VERSION ""

NS_ :

BS_:

BU_: ETH

BO_ 1060 PCS_alertLog: 8 Vector__XXX
 SG_ PCS_alertID M : 0|7@1+ (1,0) [0|0] "" Vector__XXX
 SG_ PCS_alertSet : 15|1@1+ (1,0) [0|0] "" Vector__XXX
 SG_ PCS_a001_llcFrequency m1 : 16|8@1+ (1,50) [0|0] "" Vector__XXX
 SG_ PCS_a002_phState m2 : 16|4@1+ (1,0) [0|0] "" Vector__XXX
 SG_ PCS_a003_phState m3 : 16|4@1+ (1,0) [0|0] "" Vector__XXX
 SG_ PCS_a004_phState m4 : 16|4@1+ (1,0) [0|0] "" Vector__XXX
 SG_ PCS_a005_outputV m5 : 16|8@1+ (2,0) [0|0] "" Vector__XXX
 SG_ PCS_a006_phState m6 : 16|4@1+ (1,0) [0|0] "" Vector__XXX
 SG_ PCS_a007_phATemperature m7 : 16|7@1+ (1,0) [0|0] "" Vector__XXX
 SG_ PCS_a008_phState m8 : 16|4@1+ (1,0) [0|0] "" Vector__XXX
 SG_ PCS_a009_phState m9 : 16|4@1+ (1,0) [0|0] "" Vector__XXX
 SG_ PCS_a010_phState m10 : 16|4@1+ (1,0) [0|0] "" Vector__XXX
 SG_ PCS_a011_phState m11 : 16|4@1+ (1,0) [0|0] "" Vector__XXX
 SG_ PCS_a012_phState m12 : 16|4@1+ (1,0) [0|0] "" Vector__XXX
 SG_ PCS_a013_phState m13 : 16|4@1+ (1,0) [0|0] "" Vector__XXX
 SG_ PCS_a014_phaTemperature m14 : 16|11@1- (0.1,40) [0|0] "" Vector__XXX
 SG_ PCS_a015_lvBusVoltage m15 : 16|8@1+ (0.15625,0) [0|0] "" Vector__XXX
 SG_ PCS_a016_phAVoltSrcMissingDetected m16 : 16|1@1+ (1,0) [0|0] "" Vector__XXX
 SG_ PCS_a018_PhaseDiff_L1N_L2N m18 : 16|9@1+ (1,-1) [0|0] "" Vector__XXX
 SG_ PCS_a019_pcsMaxAvailablePower m19 : 16|8@1+ (0.1,0) [0|0] "" Vector__XXX
 SG_ PCS_a020_chargeEnableLine m20 : 16|1@1+ (1,0) [0|0] "" Vector__XXX
 SG_ PCS_a021_HVP_hvsControl m21 : 16|1@1+ (1,0) [0|0] "" Vector__XXX
 SG_ PCS_a022_BMS_pcsRequest m22 : 16|1@1+ (1,0) [0|0] "" Vector__XXX
 SG_ PCS_a023_CP_chargeStatus m23 : 16|1@1+ (1,0) [0|0] "" Vector__XXX
 SG_ PCS_a024_VCFRONT_sensors m24 : 16|1@1+ (1,0) [0|0] "" Vector__XXX
 SG_ PCS_a025_cpu2ErrorCode m25 : 16|4@1+ (1,0) [0|0] "" Vector__XXX
 SG_ PCS_a026_CPU1_watchdog_alarmed m26 : 16|1@1+ (1,0) [0|0] "" Vector__XXX
 SG_ PCS_a027_chgPhATemp m27 : 16|8@1- (1,40) [0|0] "" Vector__XXX
 SG_ PCS_a028_outputV m28 : 16|10@1+ (0.5,0) [0|0] "" Vector__XXX
 SG_ PCS_a029_inputVrms m29 : 16|9@1+ (1,0) [0|0] "" Vector__XXX
 SG_ PCS_a030_canRxErrorType m30 : 16|3@1+ (1,0) [0|0] "" Vector__XXX
 SG_ PCS_a031_UI_chargeRequest m31 : 16|1@1+ (1,0) [0|0] "" Vector__XXX
 SG_ PCS_a032_phATransientRetryCount m32 : 16|9@1+ (0.1,0) [0|0] "" Vector__XXX
 SG_ PCS_a033_HV_busV m33 : 16|12@1+ (0.146484375,0) [0|0] "" Vector__XXX
 SG_ PCS_a034_HV_busV m34 : 16|12@1+ (0.146484375,0) [0|0] "" Vector__XXX
 SG_ PCS_a035_LV_busV m35 : 16|12@1+ (0.009765625,0) [0|0] "" Vector__XXX
 SG_ PCS_a036_LV_busV m36 : 16|12@1+ (0.009765625,0) [0|0] "" Vector__XXX
 SG_ PCS_a037_dcdcPwmDeassertedCount m37 : 16|8@1+ (1,0) [0|0] "" Vector__XXX
 SG_ PCS_a038_dcdcClaFaultCode m38 : 16|4@1+ (1,0) [0|0] "" Vector__XXX
 SG_ PCS_a039_SDModuleClockFault_HV m39 : 16|1@1+ (1,0) [0|0] "" Vector__XXX
 SG_ PCS_a040_dcdcLvVoltageTarget m40 : 16|8@1+ (0.1,0) [0|0] "" Vector__XXX
 SG_ PCS_a041_dcdcTemperature m41 : 16|11@1- (0.1,40) [0|0] "" Vector__XXX
 SG_ PCS_a042_dcdcEnableLine m42 : 16|1@1+ (1,0) [0|0] "" Vector__XXX
 SG_ PCS_a043_dcdcLvBusV m43 : 16|10@1+ (0.0390625,0) [0|0] "" Vector__XXX
 SG_ PCS_a044_FaultReasonCode m44 : 16|2@1+ (1,0) [0|0] "" Vector__XXX
 SG_ PCS_a045_hvBusEstimated_C_uF m45 : 16|10@1+ (7.820136852394917,0) [0|0] "" Vector__XXX
 SG_ PCS_a046_hvBusEstimated_C_uF m46 : 16|10@1+ (7.820136852394917,0) [0|0] "" Vector__XXX
 SG_ PCS_a047_cpu1BootLoaderCrcMismatch m47 : 16|1@1+ (1,0) [0|0] "" Vector__XXX
 SG_ PCS_a048_assertionReason m48 : 16|1@1+ (1,0) [0|0] "" Vector__XXX
 SG_ PCS_a049_dcdcTemperature m49 : 16|11@1- (0.1,40) [0|0] "" Vector__XXX
 SG_ PCS_a051_phState m51 : 16|4@1+ (1,0) [0|0] "" Vector__XXX
 SG_ PCS_a052_inputVrms m52 : 16|9@1+ (1,0) [0|0] "" Vector__XXX
 SG_ PCS_a053_inputVrms m53 : 16|9@1+ (1,0) [0|0] "" Vector__XXX
 SG_ PCS_a054_inputVrms m54 : 16|9@1+ (1,0) [0|0] "" Vector__XXX
 SG_ PCS_a057_inputVrms m57 : 16|10@1+ (0.5,0) [0|0] "" Vector__XXX
 SG_ PCS_a058_inputVrms m58 : 16|10@1+ (0.5,0) [0|0] "" Vector__XXX
 SG_ PCS_a059_inputVrms m59 : 16|10@1+ (0.5,0) [0|0] "" Vector__XXX
 SG_ PCS_a060_inputVPeak m60 : 16|10@1+ (0.5,0) [0|0] "" Vector__XXX
 SG_ PCS_a061_chgInputVdcOffset_L1N m61 : 16|8@1+ (1,0) [0|0] "" Vector__XXX
 SG_ PCS_a062_chgInputIOffset m62 : 16|12@1- (0.01,0) [0|0] "" Vector__XXX
 SG_ PCS_a063_chgOutputV m63 : 16|10@1+ (1,0) [0|0] "" Vector__XXX
 SG_ PCS_a064_chgOutputIOffset m64 : 16|12@1- (0.01,0) [0|0] "" Vector__XXX
 SG_ PCS_a065_inputVrms m65 : 16|10@1+ (0.5,0) [0|0] "" Vector__XXX
 SG_ PCS_a066_dcdcHvBusVolt m66 : 16|14@1+ (0.1,0) [0|0] "" Vector__XXX
 SG_ PCS_a067_dcdcLvBusVolt m67 : 16|13@1+ (0.01,0) [0|0] "" Vector__XXX
 SG_ PCS_a068_dcdcTankVolt m68 : 16|16@1- (0.03051757813,0) [0|0] "" Vector__XXX
 SG_ PCS_a069_phState m69 : 16|4@1+ (1,0) [0|0] "" Vector__XXX
 SG_ PCS_a070_phState m70 : 16|4@1+ (1,0) [0|0] "" Vector__XXX
 SG_ PCS_a071_phState m71 : 16|4@1+ (1,0) [0|0] "" Vector__XXX
 SG_ PCS_a072_task1Stopped m72 : 16|1@1+ (1,0) [0|0] "" Vector__XXX
 SG_ PCS_a073_inputL1NVrms m73 : 16|9@1+ (1,0) [0|0] "" Vector__XXX
 SG_ PCS_a074_dcdcLvBusV m74 : 16|10@1+ (0.0390625,0) [0|0] "" Vector__XXX
 SG_ PCS_a075_dcdcLvBusV m75 : 16|10@1+ (0.0390625,0) [0|0] "" Vector__XXX
 SG_ PCS_a076_pcsControlRequest m76 : 16|2@1+ (1,0) [0|0] "" Vector__XXX
 SG_ PCS_a078_phaTemperature m78 : 16|8@1- (1,40) [0|0] "" Vector__XXX
 SG_ PCS_a079_eepromOperation m79 : 16|4@1+ (1,0) [0|0] "" Vector__XXX
 SG_ PCS_a080_phADamaged m80 : 16|1@1+ (1,0) [0|0] "" Vector__XXX
 SG_ PCS_a081_dcdcLvBusV m81 : 16|10@1+ (0.0390625,0) [0|0] "" Vector__XXX
 SG_ PCS_a082_dcdcLvBusV m82 : 16|10@1+ (0.0390625,0) [0|0] "" Vector__XXX
 SG_ PCS_a083_logId m83 : 16|4@1+ (1,0) [0|0] "" Vector__XXX
 SG_ PCS_a084_dcdcSubState m84 : 16|5@1+ (1,0) [0|0] "" Vector__XXX
 SG_ PCS_a085_dcdcHalfPeriodUs m85 : 16|16@1+ (0.005,0) [0|0] "" Vector__XXX
 SG_ PCS_a086_dcdcTemperature m86 : 16|12@1- (0.1,0) [0|0] "" Vector__XXX
 SG_ PCS_a087_recordID m87 : 16|8@1+ (1,0) [0|0] "" Vector__XXX
 SG_ PCS_a088_gridConfig m88 : 16|4@1+ (1,0) [0|0] "" Vector__XXX
 SG_ PCS_a089_hvSlewRate m89 : 16|8@1- (2,0) [0|0] "" Vector__XXX
 SG_ PCS_a090_vRmsL1N m90 : 16|9@1+ (1,0) [0|0] "" Vector__XXX
 SG_ PCS_a091_intBusTarget m91 : 16|9@1+ (1,0) [0|0] "" Vector__XXX
 SG_ PCS_a092_pfcIrmsPhA m92 : 16|7@1+ (0.2,0) [0|0] "" Vector__XXX
 SG_ PCS_a093_powerRail5VN m93 : 16|10@1+ (0.01,0) [0|0] "" Vector__XXX
 SG_ PCS_a094_malfunctionCode m94 : 16|2@1+ (1,0) [0|0] "" Vector__XXX
 SG_ PCS_a095_powerRail5VN m95 : 16|10@1+ (0.01,0) [0|0] "" Vector__XXX
 SG_ PCS_a096_gridConfig m96 : 16|4@1+ (1,0) [0|0] "" Vector__XXX
 SG_ PCS_a097_phADamaged m97 : 16|1@1+ (1,0) [0|0] "" Vector__XXX
 SG_ PCS_a098_gridConfig m98 : 16|4@1+ (1,0) [0|0] "" Vector__XXX
 SG_ PCS_a099_gridConfig m99 : 16|4@1+ (1,0) [0|0] "" Vector__XXX
 SG_ PCS_a100_inputVrms m100 : 16|9@1+ (1,0) [0|0] "" Vector__XXX
 SG_ PCS_a101_phPllFreq m101 : 16|12@1+ (0.01,40) [0|0] "" Vector__XXX
 SG_ PCS_a102_pcsControlRequest m102 : 16|2@1+ (1,0) [0|0] "" Vector__XXX
 SG_ PCS_a103_lvBusVoltMin m103 : 16|8@1+ (0.1,0) [0|0] "" Vector__XXX
 SG_ PCS_a104_ambientTemperature m104 : 16|11@1- (0.1,40) [0|0] "" Vector__XXX
 SG_ PCS_a105_vRmsL1N m105 : 16|9@1+ (1,0) [0|0] "" Vector__XXX
 SG_ PCS_a107_VC_pcsInterface m107 : 16|1@1+ (1,0) [0|0] "" Vector__XXX
 SG_ PCS_a108_installedInAWrongPlatform m108 : 16|1@1+ (1,0) [0|0] "" Vector__XXX
 SG_ PCS_a109_inputL2NVrms m109 : 16|9@1+ (1,0) [0|0] "" Vector__XXX
 SG_ PCS_a016_phBVoltSrcMissingDetected m16 : 17|1@1+ (1,0) [0|0] "" Vector__XXX
 SG_ PCS_a020_chargeEnableCan m20 : 17|1@1+ (1,0) [0|0] "" Vector__XXX
 SG_ PCS_a022_BMS_chargeStatus m22 : 17|1@1+ (1,0) [0|0] "" Vector__XXX
 SG_ PCS_a023_CP_status m23 : 17|1@1+ (1,0) [0|0] "" Vector__XXX
 SG_ PCS_a024_VCFRONT_vehicleStatus m24 : 17|1@1+ (1,0) [0|0] "" Vector__XXX
 SG_ PCS_a026_CPU2_watchdog_alarmed m26 : 17|1@1+ (1,0) [0|0] "" Vector__XXX
 SG_ PCS_a039_SDModuleClockFault_LV m39 : 17|1@1+ (1,0) [0|0] "" Vector__XXX
 SG_ PCS_a042_dcdcEnableCan m42 : 17|1@1+ (1,0) [0|0] "" Vector__XXX
 SG_ PCS_a047_cpu2BootLoaderCrcMismatch m47 : 17|1@1+ (1,0) [0|0] "" Vector__XXX
 SG_ PCS_a048_4bitsData1 m48 : 17|4@1+ (1,0) [0|0] "" Vector__XXX
 SG_ PCS_a072_task2Stopped m72 : 17|1@1+ (1,0) [0|0] "" Vector__XXX
 SG_ PCS_a080_phBDamaged m80 : 17|1@1+ (1,0) [0|0] "" Vector__XXX
 SG_ PCS_a097_phBDamaged m97 : 17|1@1+ (1,0) [0|0] "" Vector__XXX
 SG_ PCS_a016_phCVoltSrcMissingDetected m16 : 18|1@1+ (1,0) [0|0] "" Vector__XXX
 SG_ PCS_a024_VCFRONT_systemStatus m24 : 18|1@1+ (1,0) [0|0] "" Vector__XXX
 SG_ PCS_a026_NMIFlagRegisters m26 : 18|11@1+ (1,0) [0|0] "" Vector__XXX
 SG_ PCS_a044_shortTime_us m44 : 18|10@1+ (0.03128054740957967,0) [0|0] "" Vector__XXX
 SG_ PCS_a076_dcdcSubState m76 : 18|5@1+ (1,0) [0|0] "" Vector__XXX
 SG_ PCS_a080_phCDamaged m80 : 18|1@1+ (1,0) [0|0] "" Vector__XXX
 SG_ PCS_a097_phCDamaged m97 : 18|1@1+ (1,0) [0|0] "" Vector__XXX
 SG_ PCS_a102_NMIFlagRegisters m102 : 18|11@1+ (1,0) [0|0] "" Vector__XXX
 SG_ PCS_a024_VCFRONT_coolant m24 : 19|1@1+ (1,0) [0|0] "" Vector__XXX
 SG_ PCS_a080_phANVRAMStoredState m80 : 19|3@1+ (1,0) [0|0] "" Vector__XXX
 SG_ PCS_a097_phANVRAMStoredState m97 : 19|3@1+ (1,0) [0|0] "" Vector__XXX
 SG_ PCS_a006_intBusPrechargeTarget m6 : 20|9@1+ (1,0) [0|0] "" Vector__XXX
 SG_ PCS_a008_phaseTemperature m8 : 20|11@1- (0.1,40) [0|0] "" Vector__XXX
 SG_ PCS_a009_pfcCurrentRms m9 : 20|9@1+ (0.1,0) [0|0] "" Vector__XXX
 SG_ PCS_a010_pfcCurrentRms m10 : 20|9@1+ (0.1,0) [0|0] "" Vector__XXX
 SG_ PCS_a011_llcCurrent m11 : 20|8@1+ (0.1,0) [0|0] "" Vector__XXX
 SG_ PCS_a012_llcFrequency m12 : 20|8@1+ (1,50) [0|0] "" Vector__XXX
 SG_ PCS_a013_intBusPrechargeTarget m13 : 20|9@1+ (1,0) [0|0] "" Vector__XXX
 SG_ PCS_a024_VCFRONT_vehNm m24 : 20|1@1+ (1,0) [0|0] "" Vector__XXX
 SG_ PCS_a025_bootromStatus m25 : 20|4@1+ (1,0) [0|0] "" Vector__XXX
 SG_ PCS_a038_dcdcSubState m38 : 20|5@1+ (1,0) [0|0] "" Vector__XXX
 SG_ PCS_a051_pfcCurrentRms m51 : 20|9@1+ (0.1,0) [0|0] "" Vector__XXX
 SG_ PCS_a069_inputIDelta m69 : 20|10@1+ (0.1,0) [0|0] "" Vector__XXX
 SG_ PCS_a070_inputVDelta m70 : 20|10@1+ (0.1,0) [0|0] "" Vector__XXX
 SG_ PCS_a071_inputVrms m71 : 20|10@1+ (0.5,0) [0|0] "" Vector__XXX
 SG_ PCS_a079_eepromOperationRegion m79 : 20|2@1+ (1,0) [0|0] "" Vector__XXX
 SG_ PCS_a088_phAFrequency m88 : 20|12@1+ (0.01,40) [0|0] "" Vector__XXX
 SG_ PCS_a096_phAFrequency m96 : 20|12@1+ (0.01,40) [0|0] "" Vector__XXX
 SG_ PCS_a098_phAFrequency m98 : 20|12@1+ (0.01,40) [0|0] "" Vector__XXX
 SG_ PCS_a099_phAFrequency m99 : 20|12@1+ (0.01,40) [0|0] "" Vector__XXX
 SG_ PCS_a024_VC_pcsManagement m24 : 21|1@1+ (1,0) [0|0] "" Vector__XXX
 SG_ PCS_a024_VCFRONT_LVPowerState m24 : 22|1@1+ (1,0) [0|0] "" Vector__XXX
 SG_ PCS_a007_phBTemperature m7 : 23|7@1+ (1,0) [0|0] "" Vector__XXX
 SG_ PCS_a076_dcdcEnableLine m76 : 23|1@1+ (1,0) [0|0] "" Vector__XXX
 SG_ PCS_a092_pfcIrmsPhB m92 : 23|7@1+ (0.2,0) [0|0] "" Vector__XXX
 SG_ PCS_a001_llcCurrent m1 : 24|8@1+ (0.1,0) [0|0] "" Vector__XXX
 SG_ PCS_a005_outputVOvThreshold m5 : 24|8@1+ (2,0) [0|0] "" Vector__XXX
 SG_ PCS_a019_utilityPowerAvailable m19 : 24|8@1+ (0.1,0) [0|0] "" Vector__XXX
 SG_ PCS_a025_bootloaderStatus m25 : 24|4@1+ (1,0) [0|0] "" Vector__XXX
 SG_ PCS_a027_chgPhBTemp m27 : 24|8@1- (1,40) [0|0] "" Vector__XXX
 SG_ PCS_a030_canID m30 : 24|16@1+ (1,0) [0|0] "" Vector__XXX
 SG_ PCS_a040_dcdcLvVoltage m40 : 24|8@1+ (0.1,0) [0|0] "" Vector__XXX
 SG_ PCS_a047_calculatedBootloaderCrc m47 : 24|32@1+ (1,0) [0|0] "" Vector__XXX
 SG_ PCS_a048_4bitsData2 m48 : 24|4@1+ (1,0) [0|0] "" Vector__XXX
 SG_ PCS_a061_chgInputVdcOffset_L2N m61 : 24|8@1+ (1,0) [0|0] "" Vector__XXX
 SG_ PCS_a076_dcdcPwmEnableDeassertedCount m76 : 24|8@1+ (1,0) [0|0] "" Vector__XXX
 SG_ PCS_a078_phbTemperature m78 : 24|8@1- (1,40) [0|0] "" Vector__XXX
 SG_ PCS_a079_recordID m79 : 24|8@1+ (1,0) [0|0] "" Vector__XXX
 SG_ PCS_a080_phBNVRAMStoredState m80 : 24|3@1+ (1,0) [0|0] "" Vector__XXX
 SG_ PCS_a084_dcdcLvBusV m84 : 24|8@1+ (0.15625,0) [0|0] "" Vector__XXX
 SG_ PCS_a087_recordStatus m87 : 24|16@1+ (1,0) [0|0] "" Vector__XXX
 SG_ PCS_a089_avgSlewRate m89 : 24|8@1- (2,0) [0|0] "" Vector__XXX
 SG_ PCS_a097_phBNVRAMStoredState m97 : 24|3@1+ (1,0) [0|0] "" Vector__XXX
 SG_ PCS_a103_lvBusVoltMax m103 : 24|8@1+ (0.1,0) [0|0] "" Vector__XXX
 SG_ PCS_a018_PhaseDiff_L2N_L3N m18 : 25|9@1+ (1,-1) [0|0] "" Vector__XXX
 SG_ PCS_a032_phBTransientRetryCount m32 : 25|9@1+ (0.1,0) [0|0] "" Vector__XXX
 SG_ PCS_a038_dcdcLvBusV m38 : 25|8@1+ (0.15625,0) [0|0] "" Vector__XXX
 SG_ PCS_a053_inputIrms m53 : 25|10@1+ (0.1,0) [0|0] "" Vector__XXX
 SG_ PCS_a054_inputIrms m54 : 25|10@1+ (0.1,0) [0|0] "" Vector__XXX
 SG_ PCS_a073_inputL2NVrms m73 : 25|9@1+ (1,0) [0|0] "" Vector__XXX
 SG_ PCS_a090_vRmsL2N m90 : 25|9@1+ (1,0) [0|0] "" Vector__XXX
 SG_ PCS_a091_intBusMaxRippleLevel m91 : 25|9@1+ (0.1,0) [0|0] "" Vector__XXX
 SG_ PCS_a100_phIntBusVolt m100 : 25|9@1+ (1,0) [0|0] "" Vector__XXX
 SG_ PCS_a105_vRmsL2N m105 : 25|9@1+ (1,0) [0|0] "" Vector__XXX
 SG_ PCS_a109_inputL3NVrms m109 : 25|9@1+ (1,0) [0|0] "" Vector__XXX
 SG_ PCS_a028_outputVUvThreshold m28 : 26|10@1+ (0.5,0) [0|0] "" Vector__XXX
 SG_ PCS_a043_dcdcHvBusV m43 : 26|12@1+ (0.146484375,0) [0|0] "" Vector__XXX
 SG_ PCS_a045_hvBusEstimated_R_kOhm m45 : 26|10@1+ (0.04887585532746823,0) [0|0] "" Vector__XXX
 SG_ PCS_a046_hvBusEstimated_R_kOhm m46 : 26|10@1+ (0.04887585532746823,0) [0|0] "" Vector__XXX
 SG_ PCS_a057_inputFrequency m57 : 26|9@1+ (0.1,40) [0|0] "" Vector__XXX
 SG_ PCS_a058_inputFrequency m58 : 26|12@1+ (0.01,40) [0|0] "" Vector__XXX
 SG_ PCS_a059_inputOvRmsThreshold m59 : 26|10@1+ (0.5,0) [0|0] "" Vector__XXX
 SG_ PCS_a060_inputOvPeakThreshold m60 : 26|10@1+ (0.5,0) [0|0] "" Vector__XXX
 SG_ PCS_a063_hvpHvLinkVoltage m63 : 26|11@1- (1,0) [0|0] "" Vector__XXX
 SG_ PCS_a065_inputFrequency m65 : 26|9@1+ (0.1,40) [0|0] "" Vector__XXX
 SG_ PCS_a074_dcdcHvBusV m74 : 26|12@1+ (0.146484375,0) [0|0] "" Vector__XXX
 SG_ PCS_a075_dcdcHvBusV m75 : 26|12@1+ (0.146484375,0) [0|0] "" Vector__XXX
 SG_ PCS_a081_dcdcHvBusV m81 : 26|12@1+ (0.146484375,0) [0|0] "" Vector__XXX
 SG_ PCS_a082_dcdcHvBusV m82 : 26|12@1+ (0.146484375,0) [0|0] "" Vector__XXX
 SG_ PCS_a093_powerRail3V3 m93 : 26|10@1+ (0.01,0) [0|0] "" Vector__XXX
 SG_ PCS_a095_pcsControlRequest m95 : 26|2@1+ (1,0) [0|0] "" Vector__XXX
 SG_ PCS_a014_phbTemperature m14 : 27|11@1- (0.1,40) [0|0] "" Vector__XXX
 SG_ PCS_a080_phCNVRAMStoredState m80 : 27|3@1+ (1,0) [0|0] "" Vector__XXX
 SG_ PCS_a097_phCNVRAMStoredState m97 : 27|3@1+ (1,0) [0|0] "" Vector__XXX
 SG_ PCS_a011_llcCurrentTarget m11 : 28|8@1+ (0.1,0) [0|0] "" Vector__XXX
 SG_ PCS_a012_llcCurrent m12 : 28|8@1+ (0.1,0) [0|0] "" Vector__XXX
 SG_ PCS_a025_bootromRequestFlag m25 : 28|1@1+ (1,0) [0|0] "" Vector__XXX
 SG_ PCS_a044_dcdcLvBusCurrent_A m44 : 28|10@1+ (0.39100684261974583,0) [0|0] "" Vector__XXX
 SG_ PCS_a086_pcsAmbientTemperature m86 : 28|12@1- (0.1,0) [0|0] "" Vector__XXX
 SG_ PCS_a101_phMachineModelFreq m101 : 28|12@1+ (0.01,40) [0|0] "" Vector__XXX
 SG_ PCS_a006_intBusV m6 : 29|9@1+ (1,0) [0|0] "" Vector__XXX
 SG_ PCS_a013_intBusV m13 : 29|9@1+ (1,0) [0|0] "" Vector__XXX
 SG_ PCS_a025_bootromRequestStatusFlag m25 : 29|1@1+ (1,0) [0|0] "" Vector__XXX
 SG_ PCS_a026_systemResetRegisters m26 : 29|11@1+ (1,0) [0|0] "" Vector__XXX
 SG_ PCS_a051_llcCurrent m51 : 29|8@1+ (0.1,0) [0|0] "" Vector__XXX
 SG_ PCS_a067_vcfrontPcsEFuseV m67 : 29|10@1+ (0.1,0) [0|0] "" Vector__XXX
 SG_ PCS_a102_systemResetRegisters m102 : 29|11@1+ (1,0) [0|0] "" Vector__XXX
 SG_ PCS_a007_phCTemperature m7 : 30|7@1+ (1,0) [0|0] "" Vector__XXX
 SG_ PCS_a069_inputVrms m69 : 30|10@1+ (0.5,0) [0|0] "" Vector__XXX
 SG_ PCS_a070_inputVrms m70 : 30|10@1+ (0.5,0) [0|0] "" Vector__XXX
 SG_ PCS_a071_intBusV m71 : 30|9@1+ (1,0) [0|0] "" Vector__XXX
 SG_ PCS_a092_pfcIrmsPhC m92 : 30|7@1+ (0.2,0) [0|0] "" Vector__XXX
 SG_ PCS_a008_inputVrms m8 : 31|9@1+ (1,0) [0|0] "" Vector__XXX
 SG_ PCS_a001_phState m1 : 32|4@1+ (1,0) [0|0] "" Vector__XXX
 SG_ PCS_a009_pfcCurrentTarget m9 : 32|12@1+ (0.01,0) [0|0] "" Vector__XXX
 SG_ PCS_a010_llcCurrent m10 : 32|8@1+ (0.1,0) [0|0] "" Vector__XXX
 SG_ PCS_a019_userPowerRequest m19 : 32|8@1+ (0.1,0) [0|0] "" Vector__XXX
 SG_ PCS_a025_cpu2StoredAppCrcLsb16 m25 : 32|16@1+ (1,0) [0|0] "" Vector__XXX
 SG_ PCS_a027_chgPhCTemp m27 : 32|8@1- (1,40) [0|0] "" Vector__XXX
 SG_ PCS_a029_chgInputPower m29 : 32|8@1+ (0.1,0) [0|0] "" Vector__XXX
 SG_ PCS_a040_dcdcLvOutputCurrent m40 : 32|13@1- (0.1,0) [0|0] "" Vector__XXX
 SG_ PCS_a048_8bitsData1 m48 : 32|8@1+ (1,0) [0|0] "" Vector__XXX
 SG_ PCS_a061_chgInputVdcOffset_L3N m61 : 32|8@1+ (1,0) [0|0] "" Vector__XXX
 SG_ PCS_a066_hvpHvLinkVoltage m66 : 32|11@1- (1,0) [0|0] "" Vector__XXX
 SG_ PCS_a068_dcdcTankVoltOffset m68 : 32|16@1- (0.001525878906,0) [0|0] "" Vector__XXX
 SG_ PCS_a078_phcTemperature m78 : 32|8@1- (1,40) [0|0] "" Vector__XXX
 SG_ PCS_a079_eepromOperationErrorCode m79 : 32|5@1+ (1,0) [0|0] "" Vector__XXX
 SG_ PCS_a084_dcdcHvBusV m84 : 32|10@1+ (0.5859375,0) [0|0] "" Vector__XXX
 SG_ PCS_a088_phBFrequency m88 : 32|12@1+ (0.01,40) [0|0] "" Vector__XXX
 SG_ PCS_a089_G m89 : 32|4@1+ (0.2,0) [0|0] "" Vector__XXX
 SG_ PCS_a096_phBFrequency m96 : 32|12@1+ (0.01,40) [0|0] "" Vector__XXX
 SG_ PCS_a098_phBFrequency m98 : 32|12@1+ (0.01,40) [0|0] "" Vector__XXX
 SG_ PCS_a099_phBFrequency m99 : 32|12@1+ (0.01,40) [0|0] "" Vector__XXX
 SG_ PCS_a103_hvBusVoltMax m103 : 32|9@1+ (1,0) [0|0] "" Vector__XXX
 SG_ PCS_a038_dcdcHvBusV m38 : 33|10@1+ (0.5859375,0) [0|0] "" Vector__XXX
 SG_ PCS_a018_PhaseDiff_L1N_L3N m18 : 34|9@1+ (1,-1) [0|0] "" Vector__XXX
 SG_ PCS_a032_phCTransientRetryCount m32 : 34|9@1+ (0.1,0) [0|0] "" Vector__XXX
 SG_ PCS_a073_inputL3NVrms m73 : 34|9@1+ (1,0) [0|0] "" Vector__XXX
 SG_ PCS_a090_vRmsL3N m90 : 34|9@1+ (1,0) [0|0] "" Vector__XXX
 SG_ PCS_a091_pfcCurrentIrms m91 : 34|8@1+ (0.1,0) [0|0] "" Vector__XXX
 SG_ PCS_a100_phKwhCounter m100 : 34|13@1+ (1,0) [0|0] "" Vector__XXX
 SG_ PCS_a105_vRmsL3N m105 : 34|9@1+ (1,0) [0|0] "" Vector__XXX
 SG_ PCS_a001_pfcCurrentRms m1 : 36|9@1+ (0.1,0) [0|0] "" Vector__XXX
 SG_ PCS_a011_llcFrequency m11 : 36|8@1+ (1,50) [0|0] "" Vector__XXX
 SG_ PCS_a012_outOfIBandDuration m12 : 36|7@1+ (0.05,0) [0|0] "" Vector__XXX
 SG_ PCS_a089_HV_busV m89 : 36|9@1+ (0.8203125,0) [0|0] "" Vector__XXX
 SG_ PCS_a007_ambientTemperature m7 : 37|7@1+ (1,0) [0|0] "" Vector__XXX
 SG_ PCS_a051_intBusV m51 : 37|9@1+ (1,0) [0|0] "" Vector__XXX
 SG_ PCS_a092_chgTempPhA m92 : 37|8@1- (1,40) [0|0] "" Vector__XXX
 SG_ PCS_a006_inputVrms m6 : 38|9@1+ (1,0) [0|0] "" Vector__XXX
 SG_ PCS_a013_inputVrms m13 : 38|9@1+ (1,0) [0|0] "" Vector__XXX
 SG_ PCS_a044_vTankPeak_abs_V m44 : 38|10@1+ (1,0) [0|0] "" Vector__XXX
 SG_ PCS_a071_inputFrequency m71 : 39|9@1+ (0.1,40) [0|0] "" Vector__XXX
 SG_ PCS_a008_inputIrms m8 : 40|10@1+ (0.1,0) [0|0] "" Vector__XXX
 SG_ PCS_a010_intBusV m10 : 40|9@1+ (1,0) [0|0] "" Vector__XXX
 SG_ PCS_a014_phcTemperature m14 : 40|11@1- (0.1,40) [0|0] "" Vector__XXX
 SG_ PCS_a019_phAFaulted m19 : 40|1@1+ (1,0) [0|0] "" Vector__XXX
 SG_ PCS_a027_chgPhANoFlowBucket m27 : 40|5@1+ (0.2,0) [0|0] "" Vector__XXX
 SG_ PCS_a029_bmsPowerCommand m29 : 40|8@1+ (0.1,0) [0|0] "" Vector__XXX
 SG_ PCS_a043_hvPrechargeTargetV m43 : 40|12@1+ (0.146484375,0) [0|0] "" Vector__XXX
 SG_ PCS_a048_8bitsData2 m48 : 40|8@1+ (1,0) [0|0] "" Vector__XXX
 SG_ PCS_a053_acChargeCurrentLimit m53 : 40|7@1+ (1,0) [0|0] "" Vector__XXX
 SG_ PCS_a054_acChargeCurrentLimit m54 : 40|7@1+ (1,0) [0|0] "" Vector__XXX
 SG_ PCS_a061_chgInputVdcOffset_L1L2 m61 : 40|8@1+ (1,0) [0|0] "" Vector__XXX
 SG_ PCS_a067_vcfrontVcrightVoltage m67 : 40|10@1+ (0.1,0) [0|0] "" Vector__XXX
 SG_ PCS_a069_intBusV m69 : 40|9@1+ (1,0) [0|0] "" Vector__XXX
 SG_ PCS_a070_intBusV m70 : 40|9@1+ (1,0) [0|0] "" Vector__XXX
 SG_ PCS_a075_dcdcSubState m75 : 40|5@1+ (1,0) [0|0] "" Vector__XXX
 SG_ PCS_a078_dcdcTemperature m78 : 40|8@1- (1,40) [0|0] "" Vector__XXX
 SG_ PCS_a079_operationAddress m79 : 40|16@1+ (1,0) [0|0] "" Vector__XXX
 SG_ PCS_a081_faultedSubstate m81 : 40|5@1+ (1,0) [0|0] "" Vector__XXX
 SG_ PCS_a082_faultedSubstate m82 : 40|5@1+ (1,0) [0|0] "" Vector__XXX
 SG_ PCS_a086_vcfrontPTCoolantTemp m86 : 40|12@1- (0.1,0) [0|0] "" Vector__XXX
 SG_ PCS_a093_powerRail1V5 m93 : 40|8@1+ (0.01,0) [0|0] "" Vector__XXX
 SG_ PCS_a101_phMachineModelCurrent m101 : 40|9@1+ (0.1,0) [0|0] "" Vector__XXX
 SG_ PCS_a102_dcdcEnableLine m102 : 40|1@1+ (1,0) [0|0] "" Vector__XXX
 SG_ PCS_a019_phBFaulted m19 : 41|1@1+ (1,0) [0|0] "" Vector__XXX
 SG_ PCS_a103_hvPrechargeTargetV m103 : 41|9@1+ (1,0) [0|0] "" Vector__XXX
 SG_ PCS_a019_phCFaulted m19 : 42|1@1+ (1,0) [0|0] "" Vector__XXX
 SG_ PCS_a084_dcdcHvBusVDropRate m84 : 42|12@1+ (1,0) [0|0] "" Vector__XXX
 SG_ PCS_a091_phaseInputVrms m91 : 42|9@1+ (1,0) [0|0] "" Vector__XXX
 SG_ PCS_a012_batteryV m12 : 43|9@1+ (1,0) [0|0] "" Vector__XXX
 SG_ PCS_a018_PhaseDiff_L1L2_L1N m18 : 43|9@1+ (1,-1) [0|0] "" Vector__XXX
 SG_ PCS_a032_phAFaulted m32 : 43|1@1+ (1,0) [0|0] "" Vector__XXX
 SG_ PCS_a038_dcdcLvBusCurrent_A m38 : 43|10@1- (0.78125,0) [0|0] "" Vector__XXX
 SG_ PCS_a073_inputNGVrms m73 : 43|9@1+ (1,0) [0|0] "" Vector__XXX
 SG_ PCS_a090_vRmsL1L2 m90 : 43|9@1+ (1,0) [0|0] "" Vector__XXX
 SG_ PCS_a105_vRmsL1L2 m105 : 43|9@1+ (1,0) [0|0] "" Vector__XXX
 SG_ PCS_a007_inputVrms m7 : 44|9@1+ (1,0) [0|0] "" Vector__XXX
 SG_ PCS_a009_llcCurrent m9 : 44|8@1+ (0.1,0) [0|0] "" Vector__XXX
 SG_ PCS_a011_intBusV m11 : 44|8@1+ (2,0) [0|0] "" Vector__XXX
 SG_ PCS_a032_phBFaulted m32 : 44|1@1+ (1,0) [0|0] "" Vector__XXX
 SG_ PCS_a088_phCFrequency m88 : 44|12@1+ (0.01,40) [0|0] "" Vector__XXX
 SG_ PCS_a096_phCFrequency m96 : 44|12@1+ (0.01,40) [0|0] "" Vector__XXX
 SG_ PCS_a098_phCFrequency m98 : 44|12@1+ (0.01,40) [0|0] "" Vector__XXX
 SG_ PCS_a099_phCFrequency m99 : 44|12@1+ (0.01,40) [0|0] "" Vector__XXX
 SG_ PCS_a001_intBusV m1 : 45|9@1+ (1,0) [0|0] "" Vector__XXX
 SG_ PCS_a032_phCFaulted m32 : 45|1@1+ (1,0) [0|0] "" Vector__XXX
 SG_ PCS_a089_PhaseShift m89 : 45|5@1+ (0.5,0) [0|0] "" Vector__XXX
 SG_ PCS_a092_chgTempPhB m92 : 45|8@1- (1,40) [0|0] "" Vector__XXX
 SG_ PCS_a051_intBusVTarget m51 : 46|9@1+ (1,0) [0|0] "" Vector__XXX
 SG_ PCS_a006_inputVToIntBusDeltaMax m6 : 47|7@1+ (1,0) [0|0] "" Vector__XXX
 SG_ PCS_a013_inputVToIntBusDeltaMax m13 : 47|7@1+ (1,0) [0|0] "" Vector__XXX
 SG_ PCS_a053_startingInputVrms m53 : 47|9@1+ (1,0) [0|0] "" Vector__XXX
 SG_ PCS_a054_startingInputVrms m54 : 47|9@1+ (1,0) [0|0] "" Vector__XXX
 SG_ PCS_a027_chgPhBNoFlowBucket m27 : 48|5@1+ (0.2,0) [0|0] "" Vector__XXX
 SG_ PCS_a029_phaseConfig m29 : 48|4@1+ (1,0) [0|0] "" Vector__XXX
 SG_ PCS_a048_16bitsData1 m48 : 48|8@1+ (1,0) [0|0] "" Vector__XXX
 SG_ PCS_a061_PllSourceIrrational_L1N m61 : 48|1@1+ (1,0) [0|0] "" Vector__XXX
 SG_ PCS_a071_llcFrequency m71 : 48|8@1+ (1,50) [0|0] "" Vector__XXX
 SG_ PCS_a078_ptCoolantTemp m78 : 48|8@1- (1,40) [0|0] "" Vector__XXX
 SG_ PCS_a093_powerRail1V2 m93 : 48|8@1+ (0.01,0) [0|0] "" Vector__XXX
 SG_ PCS_a100_phKwhCounterDeltaFromMax m100 : 48|13@1+ (1,0) [0|0] "" Vector__XXX
 SG_ PCS_a010_intBusVTarget m10 : 49|9@1+ (1,0) [0|0] "" Vector__XXX
 SG_ PCS_a061_PllSourceIrrational_L2N m61 : 49|1@1+ (1,0) [0|0] "" Vector__XXX
 SG_ PCS_a069_inputFrequency m69 : 49|9@1+ (0.1,40) [0|0] "" Vector__XXX
 SG_ PCS_a070_inputFrequency m70 : 49|9@1+ (0.1,40) [0|0] "" Vector__XXX
 SG_ PCS_a101_phInputVoltage m101 : 49|9@1+ (1,0) [0|0] "" Vector__XXX
 SG_ PCS_a061_PllSourceIrrational_L3N m61 : 50|1@1+ (1,0) [0|0] "" Vector__XXX
 SG_ PCS_a089_Freq m89 : 50|9@1+ (1,0) [0|0] "" Vector__XXX
 SG_ PCS_a103_faultPresent m103 : 50|1@1+ (1,0) [0|0] "" Vector__XXX
 SG_ PCS_a061_PllSourceIrrational_L1L2 m61 : 51|1@1+ (1,0) [0|0] "" Vector__XXX
 SG_ PCS_a091_phaseTemp m91 : 51|8@1- (1,0) [0|0] "" Vector__XXX
 SG_ PCS_a103_lvBusCurrentMax m103 : 51|8@1+ (1,0) [0|0] "" Vector__XXX
 SG_ PCS_a009_intBusV m9 : 52|8@1+ (2,0) [0|0] "" Vector__XXX
 SG_ PCS_a011_outputV m11 : 52|8@1+ (2,0) [0|0] "" Vector__XXX
 SG_ PCS_a012_transientRetryCount m12 : 52|9@1+ (0.1,0) [0|0] "" Vector__XXX
 SG_ PCS_a018_L1NLocked m18 : 52|1@1+ (1,0) [0|0] "" Vector__XXX
 SG_ PCS_a073_phaseConfig m73 : 52|4@1+ (1,0) [0|0] "" Vector__XXX
 SG_ PCS_a090_evaluatedGridConfig m90 : 52|4@1+ (1,0) [0|0] "" Vector__XXX
 SG_ PCS_a105_L1NStatus m105 : 52|2@1+ (1,0) [0|0] "" Vector__XXX
 SG_ PCS_a007_inputIrms m7 : 53|8@1+ (0.5,0) [0|0] "" Vector__XXX
 SG_ PCS_a018_L2NLocked m18 : 53|1@1+ (1,0) [0|0] "" Vector__XXX
 SG_ PCS_a038_dcdcPwmEnableDeassertedCount m38 : 53|7@1+ (1,0) [0|0] "" Vector__XXX
 SG_ PCS_a092_chgTempPhC m92 : 53|8@1- (1,40) [0|0] "" Vector__XXX
 SG_ PCS_a006_inputFrequency m6 : 54|7@1+ (1,40) [0|0] "" Vector__XXX
 SG_ PCS_a013_inputFrequency m13 : 54|7@1+ (1,40) [0|0] "" Vector__XXX
 SG_ PCS_a018_L3NLocked m18 : 54|1@1+ (1,0) [0|0] "" Vector__XXX
 SG_ PCS_a105_L2NStatus m105 : 54|2@1+ (1,0) [0|0] "" Vector__XXX
 SG_ PCS_a018_L1L2Locked m18 : 55|1@1+ (1,0) [0|0] "" Vector__XXX
 SG_ PCS_a051_intBusStaticRipple m51 : 55|6@1+ (1,0) [0|0] "" Vector__XXX
 SG_ PCS_a027_chgPhCNoFlowBucket m27 : 56|5@1+ (0.2,0) [0|0] "" Vector__XXX
 SG_ PCS_a053_phaseConfig m53 : 56|4@1+ (1,0) [0|0] "" Vector__XXX
 SG_ PCS_a054_phaseConfig m54 : 56|4@1+ (1,0) [0|0] "" Vector__XXX
 SG_ PCS_a073_cpType m73 : 56|2@1+ (1,0) [0|0] "" Vector__XXX
 SG_ PCS_a079_eepromErrorCount m79 : 56|5@1+ (1,0) [0|0] "" Vector__XXX
 SG_ PCS_a090_phASourceMissing m90 : 56|1@1+ (1,0) [0|0] "" Vector__XXX
 SG_ PCS_a093_irrational1V2Rail m93 : 56|1@1+ (1,0) [0|0] "" Vector__XXX
 SG_ PCS_a105_L3NStatus m105 : 56|2@1+ (1,0) [0|0] "" Vector__XXX
 SG_ PCS_a090_phBSourceMissing m90 : 57|1@1+ (1,0) [0|0] "" Vector__XXX
 SG_ PCS_a093_irrational1V5Rail m93 : 57|1@1+ (1,0) [0|0] "" Vector__XXX
 SG_ PCS_a090_phCSourceMissing m90 : 58|1@1+ (1,0) [0|0] "" Vector__XXX
 SG_ PCS_a093_irrational3V3Rail m93 : 58|1@1+ (1,0) [0|0] "" Vector__XXX
 SG_ PCS_a101_retryCount m101 : 58|2@1+ (1,0) [0|0] "" Vector__XXX
 SG_ PCS_a105_L1L2Status m105 : 58|2@1+ (1,0) [0|0] "" Vector__XXX
 SG_ PCS_a089_fastDischargeMode m89 : 59|1@1+ (1,0) [0|0] "" Vector__XXX
 SG_ PCS_a093_irrational5VNRail m93 : 59|1@1+ (1,0) [0|0] "" Vector__XXX
 SG_ PCS_a103_usingReducedMinPrechargePowerLimit m103 : 59|1@1+ (1,0) [0|0] "" Vector__XXX
 SG_ PCS_a038_dcdcPwmEnableLine m38 : 60|1@1+ (1,0) [0|0] "" Vector__XXX
 SG_ PCS_a089_slowDischargeMode m89 : 60|1@1+ (1,0) [0|0] "" Vector__XXX
 SG_ PCS_alertSource : 61|3@1+ (1,0) [0|0] "" Vector__XXX

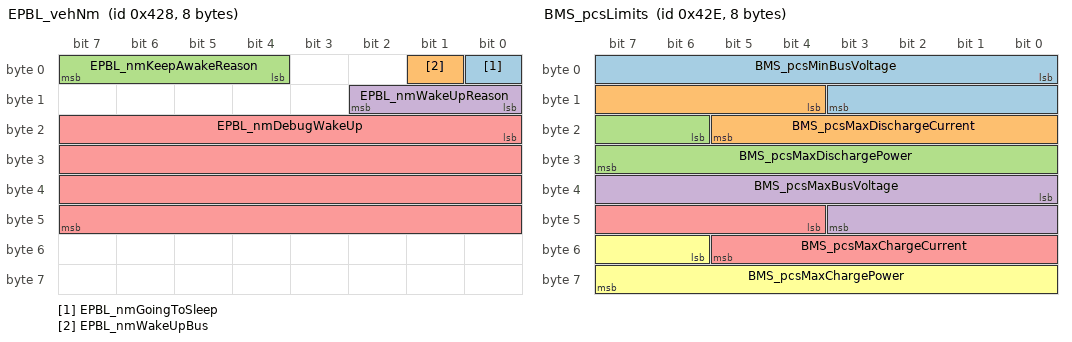
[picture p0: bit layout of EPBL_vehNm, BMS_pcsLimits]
BO_ 1064 EPBL_vehNm: 8 Vector__XXX
 SG_ EPBL_nmGoingToSleep : 0|1@1+ (1,0) [0|0] "" Vector__XXX
 SG_ EPBL_nmWakeUpBus : 1|1@1+ (1,0) [0|0] "" Vector__XXX
 SG_ EPBL_nmKeepAwakeReason : 4|4@1+ (1,0) [0|0] "" Vector__XXX
 SG_ EPBL_nmWakeUpReason : 8|3@1+ (1,0) [0|0] "" Vector__XXX
 SG_ EPBL_nmDebugWakeUp : 16|32@1+ (1,0) [0|0] "" Vector__XXX

BO_ 1066 VCSEC_TPMSConnectionData: 8 Vector__XXX
 SG_ VCSEC_TPMSSensorState0 : 0|3@1+ (1,0) [0|0] "" Vector__XXX
 SG_ VCSEC_TPMSRSSI0 : 3|7@1+ (1,-127) [0|0] "" Vector__XXX
 SG_ VCSEC_TPMSConnectionTypeCurrent0 : 10|2@1+ (1,0) [0|0] "" Vector__XXX
 SG_ VCSEC_TPMSConnectionTypeDesired0 : 12|2@1+ (1,0) [0|0] "" Vector__XXX
 SG_ VCSEC_TPMSSensorState1 : 14|3@1+ (1,0) [0|0] "" Vector__XXX
 SG_ VCSEC_TPMSRSSI1 : 17|7@1+ (1,-127) [0|0] "" Vector__XXX
 SG_ VCSEC_TPMSConnectionTypeCurrent1 : 24|2@1+ (1,0) [0|0] "" Vector__XXX
 SG_ VCSEC_TPMSConnectionTypeDesired1 : 26|2@1+ (1,0) [0|0] "" Vector__XXX
 SG_ VCSEC_TPMSSensorState2 : 28|3@1+ (1,0) [0|0] "" Vector__XXX
 SG_ VCSEC_TPMSRSSI2 : 31|7@1+ (1,-127) [0|0] "" Vector__XXX
 SG_ VCSEC_TPMSConnectionTypeCurrent2 : 38|2@1+ (1,0) [0|0] "" Vector__XXX
 SG_ VCSEC_TPMSConnectionTypeDesired2 : 40|2@1+ (1,0) [0|0] "" Vector__XXX
 SG_ VCSEC_TPMSSensorState3 : 42|3@1+ (1,0) [0|0] "" Vector__XXX
 SG_ VCSEC_TPMSRSSI3 : 45|7@1+ (1,-127) [0|0] "" Vector__XXX
 SG_ VCSEC_TPMSConnectionTypeCurrent3 : 52|2@1+ (1,0) [0|0] "" Vector__XXX
 SG_ VCSEC_TPMSConnectionTypeDesired3 : 54|2@1+ (1,0) [0|0] "" Vector__XXX
 SG_ VCSEC_TPMSSensorPresence0 : 56|2@1+ (1,0) [0|0] "" Vector__XXX
 SG_ VCSEC_TPMSSensorPresence1 : 58|2@1+ (1,0) [0|0] "" Vector__XXX
 SG_ VCSEC_TPMSSensorPresence2 : 60|2@1+ (1,0) [0|0] "" Vector__XXX
 SG_ VCSEC_TPMSSensorPresence3 : 62|2@1+ (1,0) [0|0] "" Vector__XXX

BO_ 1070 BMS_pcsLimits: 8 Vector__XXX
 SG_ BMS_pcsMinBusVoltage : 0|12@1+ (0.25,0) [0|0] "" Vector__XXX
 SG_ BMS_pcsMaxDischargeCurrent : 12|10@1+ (0.1,0) [0|0] "" Vector__XXX
 SG_ BMS_pcsMaxDischargePower : 22|10@1+ (0.025,0) [0|0] "" Vector__XXX
 SG_ BMS_pcsMaxBusVoltage : 32|12@1+ (0.25,0) [0|0] "" Vector__XXX
 SG_ BMS_pcsMaxChargeCurrent : 44|10@1+ (0.1,0) [0|0] "" Vector__XXX
 SG_ BMS_pcsMaxChargePower : 54|10@1+ (0.025,0) [0|0] "" Vector__XXX

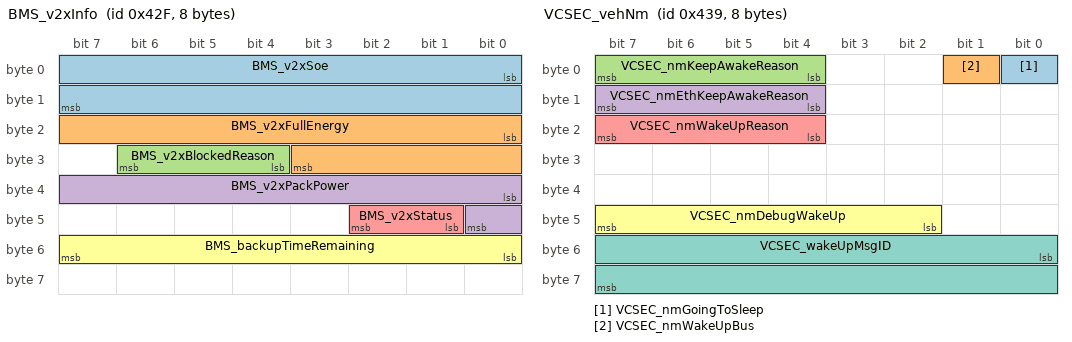
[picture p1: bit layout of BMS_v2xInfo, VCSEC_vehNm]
BO_ 1071 BMS_v2xInfo: 8 Vector__XXX
 SG_ BMS_v2xSoe : 0|16@1+ (0.002,0) [0|0] "" Vector__XXX
 SG_ BMS_v2xFullEnergy : 16|12@1+ (0.05,0) [0|0] "" Vector__XXX
 SG_ BMS_v2xBlockedReason : 28|3@1+ (1,0) [0|0] "" Vector__XXX
 SG_ BMS_v2xPackPower : 32|9@1+ (0.1,-25) [0|0] "" Vector__XXX
 SG_ BMS_v2xStatus : 41|2@1+ (1,0) [0|0] "" Vector__XXX
 SG_ BMS_backupTimeRemaining : 48|8@1+ (1,0) [0|0] "" Vector__XXX

BO_ 1074 BMS_hvsNm: 8 Vector__XXX
 SG_ BMS_hvsGoToSleep : 0|1@1+ (1,0) [0|0] "" Vector__XXX
 SG_ BMS_nmHeartbeatCounter : 1|4@1+ (1,0) [0|0] "" Vector__XXX

BO_ 1081 VCSEC_vehNm: 8 Vector__XXX
 SG_ VCSEC_nmGoingToSleep : 0|1@1+ (1,0) [0|0] "" Vector__XXX
 SG_ VCSEC_nmWakeUpBus : 1|1@1+ (1,0) [0|0] "" Vector__XXX
 SG_ VCSEC_nmKeepAwakeReason : 4|4@1+ (1,0) [0|0] "" Vector__XXX
 SG_ VCSEC_nmEthKeepAwakeReason : 12|4@1+ (1,0) [0|0] "" Vector__XXX
 SG_ VCSEC_nmWakeUpReason : 20|4@1+ (1,0) [0|0] "" Vector__XXX
 SG_ VCSEC_nmDebugWakeUp : 42|6@1+ (1,0) [0|0] "" Vector__XXX
 SG_ VCSEC_wakeUpMsgID : 48|16@1+ (1,0) [0|0] "" Vector__XXX

BO_ 1082 VCSEC_TPMSLocate: 8 Vector__XXX
 SG_ VCSEC_TPMSLocateIndex M : 0|2@1+ (1,0) [0|0] "" Vector__XXX
 SG_ VCSEC_TPMSLongBiasAccum0 m0 : 2|16@1- (1,0) [0|0] "" Vector__XXX
 SG_ VCSEC_TPMSLongBiasAccum1 m1 : 2|16@1- (1,0) [0|0] "" Vector__XXX
 SG_ VCSEC_TPMSLongBiasAccum2 m2 : 2|16@1- (1,0) [0|0] "" Vector__XXX
 SG_ VCSEC_TPMSLongBiasAccum3 m3 : 2|16@1- (1,0) [0|0] "" Vector__XXX
 SG_ VCSEC_TPMSLatBiasAccum0 m0 : 18|16@1- (1,0) [0|0] "" Vector__XXX
 SG_ VCSEC_TPMSLatBiasAccum1 m1 : 18|16@1- (1,0) [0|0] "" Vector__XXX
 SG_ VCSEC_TPMSLatBiasAccum2 m2 : 18|16@1- (1,0) [0|0] "" Vector__XXX
 SG_ VCSEC_TPMSLatBiasAccum3 m3 : 18|16@1- (1,0) [0|0] "" Vector__XXX
 SG_ VCSEC_TPMSLatBiasCount0 m0 : 34|14@1+ (1,0) [0|0] "" Vector__XXX
 SG_ VCSEC_TPMSLatBiasCount1 m1 : 34|14@1+ (1,0) [0|0] "" Vector__XXX
 SG_ VCSEC_TPMSLatBiasCount2 m2 : 34|14@1+ (1,0) [0|0] "" Vector__XXX
 SG_ VCSEC_TPMSLatBiasCount3 m3 : 34|14@1+ (1,0) [0|0] "" Vector__XXX
 SG_ VCSEC_TPMSLongBiasCount0 m0 : 48|14@1+ (1,0) [0|0] "" Vector__XXX
 SG_ VCSEC_TPMSLongBiasCount1 m1 : 48|14@1+ (1,0) [0|0] "" Vector__XXX
 SG_ VCSEC_TPMSLongBiasCount2 m2 : 48|14@1+ (1,0) [0|0] "" Vector__XXX
 SG_ VCSEC_TPMSLongBiasCount3 m3 : 48|14@1+ (1,0) [0|0] "" Vector__XXX

BO_ 1083 VCSEC_peripheralOTAStatus: 8 Vector__XXX
 SG_ VCSEC_peripheralOTAStatusIndex M : 0|3@1+ (1,0) [0|0] "" Vector__XXX
 SG_ VCSEC_KeyfobStagingProgress m4 : 8|7@1+ (1,0) [0|0] "" Vector__XXX
 SG_ VCSEC_TPMSStagingProgress0 m0 : 8|7@1+ (1,0) [0|0] "" Vector__XXX
 SG_ VCSEC_TPMSStagingProgress1 m1 : 8|7@1+ (1,0) [0|0] "" Vector__XXX
 SG_ VCSEC_TPMSStagingProgress2 m2 : 8|7@1+ (1,0) [0|0] "" Vector__XXX
 SG_ VCSEC_TPMSStagingProgress3 m3 : 8|7@1+ (1,0) [0|0] "" Vector__XXX
 SG_ VCSEC_KeyfobUpdateLastTxStatus m4 : 16|8@1+ (1,0) [0|0] "" Vector__XXX
 SG_ VCSEC_TPMSUpdateState0 m0 : 16|8@1+ (1,0) [0|0] "" Vector__XXX
 SG_ VCSEC_TPMSUpdateState1 m1 : 16|8@1+ (1,0) [0|0] "" Vector__XXX
 SG_ VCSEC_TPMSUpdateState2 m2 : 16|8@1+ (1,0) [0|0] "" Vector__XXX
 SG_ VCSEC_TPMSUpdateState3 m3 : 16|8@1+ (1,0) [0|0] "" Vector__XXX
 SG_ VCSEC_KeyfobUpdateLastRespStatus m4 : 24|8@1+ (1,0) [0|0] "" Vector__XXX
 SG_ VCSEC_TPMSUpdateLastStatus0 m0 : 24|8@1+ (1,0) [0|0] "" Vector__XXX
 SG_ VCSEC_TPMSUpdateLastStatus1 m1 : 24|8@1+ (1,0) [0|0] "" Vector__XXX
 SG_ VCSEC_TPMSUpdateLastStatus2 m2 : 24|8@1+ (1,0) [0|0] "" Vector__XXX
 SG_ VCSEC_TPMSUpdateLastStatus3 m3 : 24|8@1+ (1,0) [0|0] "" Vector__XXX
 SG_ VCSEC_KeyfobUpdateBlockTimeoutCount m4 : 32|4@1+ (1,0) [0|0] "" Vector__XXX
 SG_ VCSEC_TPMSUpdateBlockTimeoutCount0 m0 : 32|4@1+ (1,0) [0|0] "" Vector__XXX
 SG_ VCSEC_TPMSUpdateBlockTimeoutCount1 m1 : 32|4@1+ (1,0) [0|0] "" Vector__XXX
 SG_ VCSEC_TPMSUpdateBlockTimeoutCount2 m2 : 32|4@1+ (1,0) [0|0] "" Vector__XXX
 SG_ VCSEC_TPMSUpdateBlockTimeoutCount3 m3 : 32|4@1+ (1,0) [0|0] "" Vector__XXX
 SG_ VCSEC_KeyfobUpdateBlockErrorCount m4 : 36|4@1+ (1,0) [0|0] "" Vector__XXX
 SG_ VCSEC_TPMSUpdateBlockErrorCount0 m0 : 36|4@1+ (1,0) [0|0] "" Vector__XXX
 SG_ VCSEC_TPMSUpdateBlockErrorCount1 m1 : 36|4@1+ (1,0) [0|0] "" Vector__XXX
 SG_ VCSEC_TPMSUpdateBlockErrorCount2 m2 : 36|4@1+ (1,0) [0|0] "" Vector__XXX
 SG_ VCSEC_TPMSUpdateBlockErrorCount3 m3 : 36|4@1+ (1,0) [0|0] "" Vector__XXX
 SG_ VCSEC_KeyfobUpdateCRCRequestTimeoutCount m4 : 40|4@1+ (1,0) [0|0] "" Vector__XXX
 SG_ VCSEC_TPMSUpdateCRCRequestTimeoutCount0 m0 : 40|4@1+ (1,0) [0|0] "" Vector__XXX
 SG_ VCSEC_TPMSUpdateCRCRequestTimeoutCount1 m1 : 40|4@1+ (1,0) [0|0] "" Vector__XXX
 SG_ VCSEC_TPMSUpdateCRCRequestTimeoutCount2 m2 : 40|4@1+ (1,0) [0|0] "" Vector__XXX
 SG_ VCSEC_TPMSUpdateCRCRequestTimeoutCount3 m3 : 40|4@1+ (1,0) [0|0] "" Vector__XXX
 SG_ VCSEC_KeyfobUpdateLocationSetCount m4 : 44|4@1+ (1,0) [0|0] "" Vector__XXX
 SG_ VCSEC_TPMSUpdateLocationSetCount0 m0 : 44|4@1+ (1,0) [0|0] "" Vector__XXX
 SG_ VCSEC_TPMSUpdateLocationSetCount1 m1 : 44|4@1+ (1,0) [0|0] "" Vector__XXX
 SG_ VCSEC_TPMSUpdateLocationSetCount2 m2 : 44|4@1+ (1,0) [0|0] "" Vector__XXX
 SG_ VCSEC_TPMSUpdateLocationSetCount3 m3 : 44|4@1+ (1,0) [0|0] "" Vector__XXX
 SG_ VCSEC_KeyfobUpdateStalledBlockCount m4 : 48|4@1+ (1,0) [0|0] "" Vector__XXX
 SG_ VCSEC_TPMSUpdateStalledBlockCount0 m0 : 48|4@1+ (1,0) [0|0] "" Vector__XXX
 SG_ VCSEC_TPMSUpdateStalledBlockCount1 m1 : 48|4@1+ (1,0) [0|0] "" Vector__XXX
 SG_ VCSEC_TPMSUpdateStalledBlockCount2 m2 : 48|4@1+ (1,0) [0|0] "" Vector__XXX
 SG_ VCSEC_TPMSUpdateStalledBlockCount3 m3 : 48|4@1+ (1,0) [0|0] "" Vector__XXX
 SG_ VCSEC_KeyfobUpdateWaitForFlashCount m4 : 52|4@1+ (1,0) [0|0] "" Vector__XXX
 SG_ VCSEC_TPMSUpdateWaitForFlashCount0 m0 : 52|4@1+ (1,0) [0|0] "" Vector__XXX
 SG_ VCSEC_TPMSUpdateWaitForFlashCount1 m1 : 52|4@1+ (1,0) [0|0] "" Vector__XXX
 SG_ VCSEC_TPMSUpdateWaitForFlashCount2 m2 : 52|4@1+ (1,0) [0|0] "" Vector__XXX
 SG_ VCSEC_TPMSUpdateWaitForFlashCount3 m3 : 52|4@1+ (1,0) [0|0] "" Vector__XXX
 SG_ VCSEC_KeyfobUpdateExpectReconnect m4 : 56|1@1+ (1,0) [0|0] "" Vector__XXX
 SG_ VCSEC_TPMSUpdateExpectReconnect0 m0 : 56|1@1+ (1,0) [0|0] "" Vector__XXX
 SG_ VCSEC_TPMSUpdateExpectReconnect1 m1 : 56|1@1+ (1,0) [0|0] "" Vector__XXX
 SG_ VCSEC_TPMSUpdateExpectReconnect2 m2 : 56|1@1+ (1,0) [0|0] "" Vector__XXX
 SG_ VCSEC_TPMSUpdateExpectReconnect3 m3 : 56|1@1+ (1,0) [0|0] "" Vector__XXX
 SG_ VCSEC_TPMSUpdateHasUpdated0 m0 : 57|1@1+ (1,0) [0|0] "" Vector__XXX
 SG_ VCSEC_TPMSUpdateHasUpdated1 m1 : 57|1@1+ (1,0) [0|0] "" Vector__XXX
 SG_ VCSEC_TPMSUpdateHasUpdated2 m2 : 57|1@1+ (1,0) [0|0] "" Vector__XXX
 SG_ VCSEC_TPMSUpdateHasUpdated3 m3 : 57|1@1+ (1,0) [0|0] "" Vector__XXX
 SG_ VCSEC_keyWhitelistIndexBeingUpdated m4 : 57|5@1+ (1,0) [0|0] "" Vector__XXX
 SG_ VCSEC_TPMSUpdateHasStarted0 m0 : 58|1@1+ (1,0) [0|0] "" Vector__XXX
 SG_ VCSEC_TPMSUpdateHasStarted1 m1 : 58|1@1+ (1,0) [0|0] "" Vector__XXX
 SG_ VCSEC_TPMSUpdateHasStarted2 m2 : 58|1@1+ (1,0) [0|0] "" Vector__XXX
 SG_ VCSEC_TPMSUpdateHasStarted3 m3 : 58|1@1+ (1,0) [0|0] "" Vector__XXX
 SG_ VCSEC_TPMSUpdateRetryLimitReached0 m0 : 59|1@1+ (1,0) [0|0] "" Vector__XXX
 SG_ VCSEC_TPMSUpdateRetryLimitReached1 m1 : 59|1@1+ (1,0) [0|0] "" Vector__XXX
 SG_ VCSEC_TPMSUpdateRetryLimitReached2 m2 : 59|1@1+ (1,0) [0|0] "" Vector__XXX
 SG_ VCSEC_TPMSUpdateRetryLimitReached3 m3 : 59|1@1+ (1,0) [0|0] "" Vector__XXX

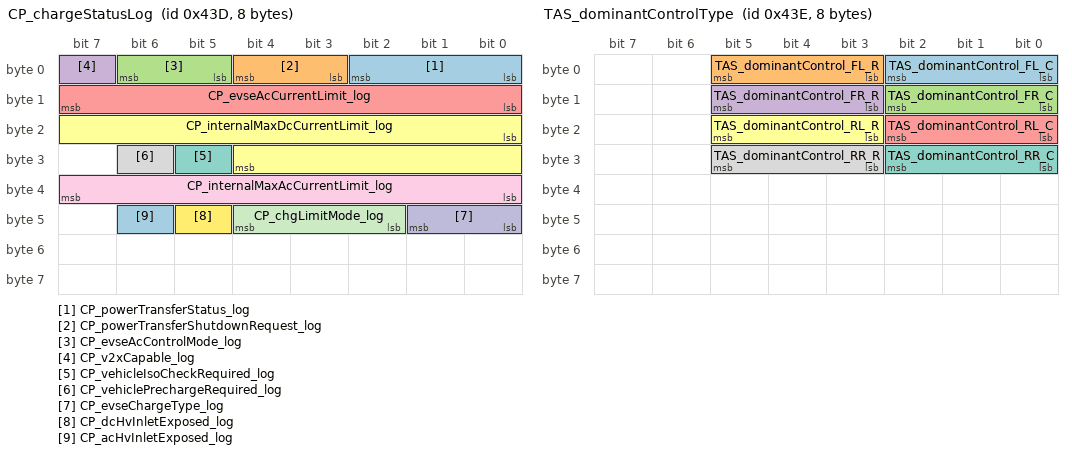
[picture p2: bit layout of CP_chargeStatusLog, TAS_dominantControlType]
BO_ 1085 CP_chargeStatusLog: 8 Vector__XXX
 SG_ CP_powerTransferStatus_log : 0|3@1+ (1,0) [0|0] "" Vector__XXX
 SG_ CP_powerTransferShutdownRequest_log : 3|2@1+ (1,0) [0|0] "" Vector__XXX
 SG_ CP_evseAcControlMode_log : 5|2@1+ (1,0) [0|0] "" Vector__XXX
 SG_ CP_v2xCapable_log : 7|1@1+ (1,0) [0|0] "" Vector__XXX
 SG_ CP_evseAcCurrentLimit_log : 8|8@1+ (0.5,0) [0|0] "" Vector__XXX
 SG_ CP_internalMaxDcCurrentLimit_log : 16|13@1+ (0.25,0) [0|0] "" Vector__XXX
 SG_ CP_vehicleIsoCheckRequired_log : 29|1@1+ (1,0) [0|0] "" Vector__XXX
 SG_ CP_vehiclePrechargeRequired_log : 30|1@1+ (1,0) [0|0] "" Vector__XXX
 SG_ CP_internalMaxAcCurrentLimit_log : 32|8@1+ (0.5,0) [0|0] "" Vector__XXX
 SG_ CP_evseChargeType_log : 40|2@1+ (1,0) [0|0] "" Vector__XXX
 SG_ CP_chgLimitMode_log : 42|3@1+ (1,0) [0|0] "" Vector__XXX
 SG_ CP_dcHvInletExposed_log : 45|1@1+ (1,0) [0|0] "" Vector__XXX
 SG_ CP_acHvInletExposed_log : 46|1@1+ (1,0) [0|0] "" Vector__XXX

BO_ 1086 TAS_dominantControlType: 8 Vector__XXX
 SG_ TAS_dominantControl_FL_C : 0|3@1+ (1,0) [0|0] "" Vector__XXX
 SG_ TAS_dominantControl_FL_R : 3|3@1+ (1,0) [0|0] "" Vector__XXX
 SG_ TAS_dominantControl_FR_C : 8|3@1+ (1,0) [0|0] "" Vector__XXX
 SG_ TAS_dominantControl_FR_R : 11|3@1+ (1,0) [0|0] "" Vector__XXX
 SG_ TAS_dominantControl_RL_C : 16|3@1+ (1,0) [0|0] "" Vector__XXX
 SG_ TAS_dominantControl_RL_R : 19|3@1+ (1,0) [0|0] "" Vector__XXX
 SG_ TAS_dominantControl_RR_C : 24|3@1+ (1,0) [0|0] "" Vector__XXX
 SG_ TAS_dominantControl_RR_R : 27|3@1+ (1,0) [0|0] "" Vector__XXX

BO_ 1089 VC_pcsInterface: 8 Vector__XXX
 SG_ VC_pcsLVVoltageTarget m0 : 0|13@1+ (0.01,0) [0|0] "" Vector__XXX
 SG_ VC_pcsResistanceFiltered m1 : 0|16@1+ (0.01,0) [0|0] "" Vector__XXX
 SG_ VC_pcsLVMinVoltageLimit m0 : 13|13@1+ (0.01,0) [0|0] "" Vector__XXX
 SG_ VC_pcsLVMaxDchrgCurrentLimit m1 : 16|12@1+ (0.1,0) [0|0] "" Vector__XXX
 SG_ VC_pcsLVMaxVoltageLimit m0 : 27|13@1+ (0.01,0) [0|0] "" Vector__XXX
 SG_ VC_defaultPcsLVVoltageTarget m1 : 28|13@1+ (0.01,0) [0|0] "" Vector__XXX
 SG_ VC_lvHwProtSelfTestActive m1 : 41|1@1+ (1,0) [0|0] "" Vector__XXX
 SG_ VC_lvBatteryDischargeRequest m1 : 42|1@1+ (1,0) [0|0] "" Vector__XXX
 SG_ VC_goodForPCSPowerCycle m0 : 46|1@1+ (1,0) [0|0] "" Vector__XXX
 SG_ VC_LVBatteryCannotSupportVehicle m0 : 47|1@1+ (1,0) [0|0] "" Vector__XXX
 SG_ VC_pcsInterfaceMuxIndex M : 48|1@1+ (1,0) [0|0] "" Vector__XXX
 SG_ VC_pcsInterfaceCounter : 50|4@1+ (1,0) [0|0] "" Vector__XXX
 SG_ VC_pcsInterfaceChecksum : 56|8@1+ (1,0) [0|0] "" Vector__XXX

BO_ 1090 VCBATT_pcsInterface: 8 Vector__XXX
 SG_ VCBATT_pcsLVVoltageTarget m0 : 0|13@1+ (0.01,0) [0|0] "" Vector__XXX
 SG_ VCBATT_pcsResistanceFiltered m1 : 0|16@1+ (0.01,0) [0|0] "" Vector__XXX
 SG_ VCBATT_pcsLVMinVoltageLimit m0 : 13|13@1+ (0.01,0) [0|0] "" Vector__XXX
 SG_ VCBATT_pcsLVMaxDchrgCurrentLimit m1 : 16|12@1+ (0.1,0) [0|0] "" Vector__XXX
 SG_ VCBATT_pcsLVMaxVoltageLimit m0 : 27|13@1+ (0.01,0) [0|0] "" Vector__XXX
 SG_ VCBATT_defaultPcsLVVoltageTarget m1 : 28|13@1+ (0.01,0) [0|0] "" Vector__XXX
 SG_ VCBATT_lvHwProtSelfTestActive m1 : 41|1@1+ (1,0) [0|0] "" Vector__XXX
 SG_ VCBATT_lvBatteryDischargeRequest m1 : 42|1@1+ (1,0) [0|0] "" Vector__XXX
 SG_ VCBATT_goodForPCSPowerCycle m0 : 46|1@1+ (1,0) [0|0] "" Vector__XXX
 SG_ VCBATT_LVBatteryCannotSupportVehicle m0 : 47|1@1+ (1,0) [0|0] "" Vector__XXX
 SG_ VCBATT_pcsInterfaceMuxIndex M : 48|1@1+ (1,0) [0|0] "" Vector__XXX
 SG_ VCBATT_pcsInterfaceCounter : 50|4@1+ (1,0) [0|0] "" Vector__XXX
 SG_ VCBATT_pcsInterfaceChecksum : 56|8@1+ (1,0) [0|0] "" Vector__XXX

BO_ 1091 VC_pcsManagement: 8 Vector__XXX
 SG_ VC_pcsManagementChecksum : 0|8@1+ (1,0) [0|0] "" Vector__XXX
 SG_ VC_pcsManagementCounter : 8|4@1+ (1,0) [0|0] "" Vector__XXX
 SG_ VC_pcsManagementMuxIndex M : 12|1@1+ (1,0) [0|0] "" Vector__XXX
 SG_ VC_dcdcLVVoltageTargetMax m0 : 16|10@1+ (0.1,0) [0|0] "" Vector__XXX
 SG_ VC_dcdcLVVoltageTargetMin m0 : 26|10@1+ (0.1,0) [0|0] "" Vector__XXX
 SG_ VC_dcdcLVInputPowerLimit m0 : 36|8@1+ (50,0) [0|0] "" Vector__XXX

BO_ 1092 PCS2_alertLog: 8 Vector__XXX
 SG_ PCS2_alertID M : 0|8@1+ (1,0) [0|0] "" Vector__XXX
 SG_ PCS2_alertSet : 15|1@1+ (1,0) [0|0] "" Vector__XXX
 SG_ PCS2_a001_CPU0_watchdog_alarmed m1 : 16|1@1+ (1,0) [0|0] "" Vector__XXX
 SG_ PCS2_a002_canRxErrorType m2 : 16|3@1+ (1,0) [0|0] "" Vector__XXX
 SG_ PCS2_a003_assertionCode m3 : 16|2@1+ (1,0) [0|0] "" Vector__XXX
 SG_ PCS2_a004_acL1NOverVoltageTrip m4 : 16|1@1+ (1,0) [0|0] "" Vector__XXX
 SG_ PCS2_a005_acL1OverCurrentTrip m5 : 16|1@1+ (1,0) [0|0] "" Vector__XXX
 SG_ PCS2_a006_acL2NOverVoltageTrip m6 : 16|1@1+ (1,0) [0|0] "" Vector__XXX
 SG_ PCS2_a007_acL2OverCurrentTrip m7 : 16|1@1+ (1,0) [0|0] "" Vector__XXX
 SG_ PCS2_a008_acL3NOverVoltageTrip m8 : 16|1@1+ (1,0) [0|0] "" Vector__XXX
 SG_ PCS2_a009_acL3OverCurrentTrip m9 : 16|1@1+ (1,0) [0|0] "" Vector__XXX
 SG_ PCS2_a010_acLNOverCurrentTrip m10 : 16|1@1+ (1,0) [0|0] "" Vector__XXX
 SG_ PCS2_a011_hvdcOverCurrentTrip m11 : 16|1@1+ (1,0) [0|0] "" Vector__XXX
 SG_ PCS2_a012_cycloATankOverCurrentTrip m12 : 16|1@1+ (1,0) [0|0] "" Vector__XXX
 SG_ PCS2_a013_DcdcALv2Temp m13 : 16|11@1- (0.15,70.05) [0|0] "" Vector__XXX
 SG_ PCS2_a014_cycloBTankOverCurrentTrip m14 : 16|1@1+ (1,0) [0|0] "" Vector__XXX
 SG_ PCS2_a015_DcdcAHvTemp m15 : 16|11@1- (0.15,70.05) [0|0] "" Vector__XXX
 SG_ PCS2_a016_dcdcATankOverCurrentTrip m16 : 16|1@1+ (1,0) [0|0] "" Vector__XXX
 SG_ PCS2_a017_DcdcBLv2Temp m17 : 16|11@1- (0.15,70.05) [0|0] "" Vector__XXX
 SG_ PCS2_a018_dcdcBTankOverCurrentTrip m18 : 16|1@1+ (1,0) [0|0] "" Vector__XXX
 SG_ PCS2_a019_DcacADcTemp m19 : 16|11@1- (0.15,70.05) [0|0] "" Vector__XXX
 SG_ PCS2_a020_DcacBDcTemp m20 : 16|11@1- (0.15,70.05) [0|0] "" Vector__XXX
 SG_ PCS2_a021_4V5RailUnderVoltageTrip m21 : 16|1@1+ (1,0) [0|0] "" Vector__XXX
 SG_ PCS2_a024_DcacATxTemp m24 : 16|11@1- (0.15,70.05) [0|0] "" Vector__XXX
 SG_ PCS2_a025_DcacBTxTemp m25 : 16|11@1- (0.15,70.05) [0|0] "" Vector__XXX
 SG_ PCS2_a026_AcConnectorTemp m26 : 16|11@1- (0.15,70.05) [0|0] "" Vector__XXX
 SG_ PCS2_a027_AmbientTemp m27 : 16|11@1- (0.15,70.05) [0|0] "" Vector__XXX
 SG_ PCS2_a028_CoolantTemp m28 : 16|11@1- (0.15,70.05) [0|0] "" Vector__XXX
 SG_ PCS2_a029_DcacAAc1Temp m29 : 16|11@1- (0.15,70.05) [0|0] "" Vector__XXX
 SG_ PCS2_a030_DcacAAc2Temp m30 : 16|11@1- (0.15,70.05) [0|0] "" Vector__XXX
 SG_ PCS2_a031_DcacBAc1Temp m31 : 16|11@1- (0.15,70.05) [0|0] "" Vector__XXX
 SG_ PCS2_a032_DcacBAc2Temp m32 : 16|11@1- (0.15,70.05) [0|0] "" Vector__XXX
 SG_ PCS2_a033_taskUtilizationPercentage m33 : 16|8@1+ (1,0) [0|0] "" Vector__XXX
 SG_ PCS2_a034_lvBusVoltage m34 : 16|13@1+ (0.01,0) [0|0] "" Vector__XXX
 SG_ PCS2_a035_lvBusVoltage m35 : 16|13@1+ (0.01,0) [0|0] "" Vector__XXX
 SG_ PCS2_a036_hvBusVoltage m36 : 16|11@1+ (1,0) [0|0] "" Vector__XXX
 SG_ PCS2_a037_hvBusVoltage m37 : 16|11@1+ (1,0) [0|0] "" Vector__XXX
 SG_ PCS2_a038_hvBusVoltage m38 : 16|11@1+ (1,0) [0|0] "" Vector__XXX
 SG_ PCS2_a039_hvBusVoltage m39 : 16|11@1+ (1,0) [0|0] "" Vector__XXX
 SG_ PCS2_a040_hvBusVoltage m40 : 16|11@1+ (1,0) [0|0] "" Vector__XXX
 SG_ PCS2_a041_hvBusVoltage m41 : 16|11@1+ (1,0) [0|0] "" Vector__XXX
 SG_ PCS2_a042_hvBattVoltage m42 : 16|11@1+ (1,0) [0|0] "" Vector__XXX
 SG_ PCS2_a043_hvBattVoltage m43 : 16|11@1+ (1,0) [0|0] "" Vector__XXX
 SG_ PCS2_a044_hvBattVoltage m44 : 16|11@1+ (1,0) [0|0] "" Vector__XXX
 SG_ PCS2_a045_hvBattVoltage m45 : 16|11@1+ (1,0) [0|0] "" Vector__XXX
 SG_ PCS2_a046_hvBattVoltage m46 : 16|11@1+ (1,0) [0|0] "" Vector__XXX
 SG_ PCS2_a047_hvBattVoltage m47 : 16|11@1+ (1,0) [0|0] "" Vector__XXX
 SG_ PCS2_a048_hvBusVoltage m48 : 16|11@1+ (1,0) [0|0] "" Vector__XXX
 SG_ PCS2_a049_hvBusVoltage m49 : 16|11@1+ (1,0) [0|0] "" Vector__XXX
 SG_ PCS2_a050_VC_pcsInterface m50 : 16|1@1+ (1,0) [0|0] "" Vector__XXX
 SG_ PCS2_a051_BMS_pcsRequest m51 : 16|1@1+ (1,0) [0|0] "" Vector__XXX
 SG_ PCS2_a052_CP_chargeStatus m52 : 16|1@1+ (1,0) [0|0] "" Vector__XXX
 SG_ PCS2_a053_HV_dcdcControl m53 : 16|1@1+ (1,0) [0|0] "" Vector__XXX
 SG_ PCS2_a054_UI_chargeRequest m54 : 16|1@1+ (1,0) [0|0] "" Vector__XXX
 SG_ PCS2_a055_tankCapacitanceDefined m55 : 16|1@1+ (1,0) [0|0] "" Vector__XXX
 SG_ PCS2_a056_tankCapacitanceDefined m56 : 16|1@1+ (1,0) [0|0] "" Vector__XXX
 SG_ PCS2_a057_tankCapacitanceDefined m57 : 16|1@1+ (1,0) [0|0] "" Vector__XXX
 SG_ PCS2_a058_tankCapacitanceDefined m58 : 16|1@1+ (1,0) [0|0] "" Vector__XXX
 SG_ PCS2_a059_dcdcHvcEnableLineTZLatchedBit m59 : 16|1@1+ (1,0) [0|0] "" Vector__XXX
 SG_ PCS2_a060_maxRetriesAllowed m60 : 16|4@1+ (1,0) [0|0] "" Vector__XXX
 SG_ PCS2_a061_maxRetriesAllowed m61 : 16|4@1+ (1,0) [0|0] "" Vector__XXX
 SG_ PCS2_a062_acL1NVrms m62 : 16|7@1+ (3,0) [0|0] "" Vector__XXX
 SG_ PCS2_a063_phase_diff_L1N_L2N m63 : 16|8@1+ (1,0) [0|0] "" Vector__XXX
 SG_ PCS2_a064_leakageInductance m64 : 16|12@1+ (0.1,0) [0|0] "" Vector__XXX
 SG_ PCS2_a065_leakageInductance m65 : 16|12@1+ (0.1,0) [0|0] "" Vector__XXX
 SG_ PCS2_a066_leakageInductance m66 : 16|12@1+ (0.1,0) [0|0] "" Vector__XXX
 SG_ PCS2_a067_leakageInductance m67 : 16|12@1+ (0.1,0) [0|0] "" Vector__XXX
 SG_ PCS2_a068_recordProblemBitfield m68 : 16|8@1+ (1,0) [0|0] "" Vector__XXX
 SG_ PCS2_a069_recordNotFound m69 : 16|1@1+ (1,0) [0|0] "" Vector__XXX
 SG_ PCS2_a070_recordNotFound m70 : 16|1@1+ (1,0) [0|0] "" Vector__XXX
 SG_ PCS2_a071_hvBattBotSensorMeasurement m71 : 16|12@1- (1,0) [0|0] "" Vector__XXX
 SG_ PCS2_a072_hvBattTopSensorMeasurement m72 : 16|12@1- (1,0) [0|0] "" Vector__XXX
 SG_ PCS2_a073_hvBusBotSensorMeasurement m73 : 16|12@1- (1,0) [0|0] "" Vector__XXX
 SG_ PCS2_a074_hvBusTopSensorMeasurement m74 : 16|12@1- (1,0) [0|0] "" Vector__XXX
 SG_ PCS2_a075_hvBattFullSensorMeasurement m75 : 16|12@1- (1,0) [0|0] "" Vector__XXX
 SG_ PCS2_a076_hvBusFullSensorMeasurement m76 : 16|12@1- (1,0) [0|0] "" Vector__XXX
 SG_ PCS2_a077_lvBusVoltageMeasurement m77 : 16|13@1+ (0.01,0) [0|0] "" Vector__XXX
 SG_ PCS2_a078_acL1NVoltageOffset m78 : 16|13@1- (0.5,0) [0|0] "" Vector__XXX
 SG_ PCS2_a079_acL2NVoltageOffset m79 : 16|13@1- (0.5,0) [0|0] "" Vector__XXX
 SG_ PCS2_a080_acL3NVoltageOffset m80 : 16|13@1- (0.5,0) [0|0] "" Vector__XXX
 SG_ PCS2_a081_acL1CurrentOffset m81 : 16|12@1- (0.5,0) [0|0] "" Vector__XXX
 SG_ PCS2_a082_acL2CurrentOffset m82 : 16|12@1- (0.5,0) [0|0] "" Vector__XXX
 SG_ PCS2_a083_acL3CurrentOffset m83 : 16|12@1- (0.5,0) [0|0] "" Vector__XXX
 SG_ PCS2_a084_acNCurrentOffset m84 : 16|12@1- (0.5,0) [0|0] "" Vector__XXX
 SG_ PCS2_a085_dcacEnableLineStatus m85 : 16|1@1+ (1,0) [0|0] "" Vector__XXX
 SG_ PCS2_a086_lvBusVoltage m86 : 16|13@1+ (0.01,0) [0|0] "" Vector__XXX
 SG_ PCS2_a087_lvBusVoltage m87 : 16|13@1+ (0.01,0) [0|0] "" Vector__XXX
 SG_ PCS2_a088_linesFaulted m88 : 16|3@1+ (1,0) [0|0] "" Vector__XXX
 SG_ PCS2_a090_DcdcModelLvMosfetTemp m90 : 16|9@1- (1,106) [0|0] "" Vector__XXX
 SG_ PCS2_a091_DcdcModelTxWindingTemp m91 : 16|9@1- (1,106) [0|0] "" Vector__XXX
 SG_ PCS2_a092_zcd_alert_counts m92 : 16|5@1+ (1,0) [0|0] "" Vector__XXX
 SG_ PCS2_a094_cycloABlockedReason m94 : 16|3@1+ (1,0) [0|0] "" Vector__XXX
 SG_ PCS2_a095_cycloABlockedReason m95 : 16|3@1+ (1,0) [0|0] "" Vector__XXX
 SG_ PCS2_a096_VCSUPER_thermalStatus10Hz m96 : 16|1@1+ (1,0) [0|0] "" Vector__XXX
 SG_ PCS2_a097_GTW_carState m97 : 16|1@1+ (1,0) [0|0] "" Vector__XXX
 SG_ PCS2_a098_EGGRIGHT3_thermalCommand10Hz m98 : 16|1@1+ (1,0) [0|0] "" Vector__XXX
 SG_ PCS2_a099_lineFaulted m99 : 16|2@1+ (1,0) [0|0] "" Vector__XXX
 SG_ PCS2_a100_linesFaulted m100 : 16|3@1+ (1,0) [0|0] "" Vector__XXX
 SG_ PCS2_a101_lineFaulted m101 : 16|2@1+ (1,0) [0|0] "" Vector__XXX
 SG_ PCS2_a102_linesFaulted m102 : 16|3@1+ (1,0) [0|0] "" Vector__XXX
 SG_ PCS2_a103_IsoTempSensor m103 : 16|4@1+ (1,0) [0|0] "" Vector__XXX
 SG_ PCS2_a104_lineFaulted m104 : 16|2@1+ (1,0) [0|0] "" Vector__XXX
 SG_ PCS2_a105_linesFaulted m105 : 16|3@1+ (1,0) [0|0] "" Vector__XXX
 SG_ PCS2_a106_systemNeutral m106 : 16|2@1+ (1,0) [0|0] "" Vector__XXX
 SG_ PCS2_a107_line_1_damper_current m107 : 16|6@1- (1,0) [0|0] "" Vector__XXX
 SG_ PCS2_a109_consecutiveTriggerEvents m109 : 16|9@1+ (1,0) [0|0] "" Vector__XXX
 SG_ PCS2_a110_deratingFactorThreshold m110 : 16|7@1+ (0.01,0) [0|0] "" Vector__XXX
 SG_ PCS2_a112_linesFaulted m112 : 16|3@1+ (1,0) [0|0] "" Vector__XXX
 SG_ PCS2_a113_receivedCoolantFlow m113 : 16|9@1+ (0.1,0) [0|0] "" Vector__XXX
 SG_ PCS2_a114_estimatedHvbusCapacitance m114 : 16|10@1+ (10,0) [0|0] "" Vector__XXX
 SG_ PCS2_a115_lineVoltage m115 : 16|7@1+ (3,0) [0|0] "" Vector__XXX
 SG_ PCS2_a116_chgRetryCount m116 : 16|9@1+ (0.1,0) [0|0] "" Vector__XXX
 SG_ PCS2_a117_VCRIGHT_LVHealth m117 : 16|1@1+ (1,0) [0|0] "" Vector__XXX
 SG_ PCS2_a118_presentHvBusVoltage m118 : 16|11@1+ (1,0) [0|0] "" Vector__XXX
 SG_ PCS2_a119_presentHvBusVoltage m119 : 16|11@1+ (1,0) [0|0] "" Vector__XXX
 SG_ PCS2_a120_logId m120 : 16|8@1+ (1,0) [0|0] "" Vector__XXX
 SG_ PCS2_a121_maxDcdcLvTemp m121 : 16|8@1- (1,46) [0|0] "" Vector__XXX
 SG_ PCS2_a122_recordNotFound m122 : 16|1@1+ (1,0) [0|0] "" Vector__XXX
 SG_ PCS2_a123_DcdcBHvTemp m123 : 16|11@1- (0.15,70.05) [0|0] "" Vector__XXX
 SG_ PCS2_a124_tankCurrentRef m124 : 16|3@1+ (10,100) [0|0] "" Vector__XXX
 SG_ PCS2_a125_lntp_state m125 : 16|1@1+ (1,0) [0|0] "" Vector__XXX
 SG_ PCS2_a126_ipcCpu0LockSuccessiveGrabFailCount m126 : 16|3@1+ (1,0) [0|0] "" Vector__XXX
 SG_ PCS2_a127_acLineClkHealthStatus m127 : 16|2@1+ (1,0) [0|0] "" Vector__XXX
 SG_ PCS2_a128_acLineClkHealthStatus m128 : 16|2@1+ (1,0) [0|0] "" Vector__XXX
 SG_ PCS2_a129_hvBusVoltage m129 : 16|7@1+ (10,100) [0|0] "" Vector__XXX
 SG_ PCS2_a130_serverStateAtRetry m130 : 16|3@1+ (1,0) [0|0] "" Vector__XXX
 SG_ PCS2_a131_microgridHeartbeat1hzRms m131 : 16|8@1+ (0.001,0) [0|0] "" Vector__XXX
 SG_ PCS2_a132_gridFrequency m132 : 16|13@1+ (0.01,0) [0|0] "" Vector__XXX
 SG_ PCS2_a136_failedSequence m136 : 16|4@1+ (1,0) [0|0] "" Vector__XXX
 SG_ PCS2_a137_failedSequence m137 : 16|4@1+ (1,0) [0|0] "" Vector__XXX
 SG_ PCS2_a140_halfBusCompensation m140 : 16|7@1- (1,0) [0|0] "" Vector__XXX
 SG_ PCS2_a141_boostOverCurrentThreshold m141 : 16|13@1- (0.1,0) [0|0] "" Vector__XXX
 SG_ PCS2_a142_AcLineGdpsDataMissing m142 : 16|1@1+ (1,0) [0|0] "" Vector__XXX
 SG_ PCS2_a143_AcTankGdpsDataMissing m143 : 16|1@1+ (1,0) [0|0] "" Vector__XXX
 SG_ PCS2_a144_DcTankGdpsDataMissing m144 : 16|1@1+ (1,0) [0|0] "" Vector__XXX
 SG_ PCS2_a145_DcdcHvdcGdpsDataMissing m145 : 16|1@1+ (1,0) [0|0] "" Vector__XXX
 SG_ PCS2_a146_leg1_Irms m146 : 16|10@1+ (0.1,0) [0|0] "" Vector__XXX
 SG_ PCS2_a147_4V5RailOverVoltageTrip m147 : 16|1@1+ (1,0) [0|0] "" Vector__XXX
 SG_ PCS2_a148_l1nPostRelayVoltage m148 : 16|7@1- (10,0) [0|0] "" Vector__XXX
 SG_ PCS2_a149_buckBoostPermanentFault m149 : 16|1@1+ (1,0) [0|0] "" Vector__XXX
 SG_ PCS2_a150_presentBurstMode m150 : 16|2@1+ (1,0) [0|0] "" Vector__XXX
 SG_ PCS2_a151_DcdcBLv1Temp m151 : 16|11@1- (0.15,70.05) [0|0] "" Vector__XXX
 SG_ PCS2_a152_DcdcBLv3Temp m152 : 16|11@1- (0.15,70.05) [0|0] "" Vector__XXX
 SG_ PCS2_a153_zcd_alert_counts m153 : 16|5@1+ (1,0) [0|0] "" Vector__XXX
 SG_ PCS2_a154_adcReferenceDataMissing m154 : 16|1@1+ (1,0) [0|0] "" Vector__XXX
 SG_ PCS2_a155_VC_LVHealth m155 : 16|1@1+ (1,0) [0|0] "" Vector__XXX
 SG_ PCS2_a156_VCFRONT_coolant m156 : 16|1@1+ (1,0) [0|0] "" Vector__XXX
 SG_ PCS2_a157_VC_pcsManagement m157 : 16|1@1+ (1,0) [0|0] "" Vector__XXX
 SG_ PCS2_a158_DcdcModelHvMosfetTemp m158 : 16|9@1- (1,106) [0|0] "" Vector__XXX
 SG_ PCS2_a159_HVDCGdpsHealthStatus m159 : 16|2@1+ (1,0) [0|0] "" Vector__XXX
 SG_ PCS2_a160_VCLEFT_networkManagement m160 : 16|1@1+ (1,0) [0|0] "" Vector__XXX
 SG_ PCS2_a161_VCREAR_networkManagement m161 : 16|1@1+ (1,0) [0|0] "" Vector__XXX
 SG_ PCS2_a162_cycloTankLeakageInductance m162 : 16|12@1+ (0.1,0) [0|0] "" Vector__XXX
 SG_ PCS2_a163_cycloTankLeakageInductance m163 : 16|12@1+ (0.1,0) [0|0] "" Vector__XXX
 SG_ PCS2_a164_zcdFallingPu m164 : 16|7@1+ (0.01,0) [0|0] "" Vector__XXX
 SG_ PCS2_a165_dutyP m165 : 16|7@1+ (0.01,0) [0|0] "" Vector__XXX
 SG_ PCS2_a166_vcrTZLatchStatus m166 : 16|1@1+ (1,0) [0|0] "" Vector__XXX
 SG_ PCS2_a168_timeBelow70pct m168 : 16|14@1+ (0.002,0) [0|0] "" Vector__XXX
 SG_ PCS2_a169_measuredHalfPeriodDifference m169 : 16|10@1+ (1,0) [0|0] "" Vector__XXX
 SG_ PCS2_a172_dcdcExternalRequest m172 : 16|2@1+ (1,0) [0|0] "" Vector__XXX
 SG_ PCS2_a175_lvBusVoltage m175 : 16|6@1+ (1,1) [0|0] "" Vector__XXX
 SG_ PCS2_a001_CPU1_watchdog_alarmed m1 : 17|1@1+ (1,0) [0|0] "" Vector__XXX
 SG_ PCS2_a004_chgMainStateMachineState m4 : 17|4@1+ (1,0) [0|0] "" Vector__XXX
 SG_ PCS2_a005_chgMainStateMachineState m5 : 17|4@1+ (1,0) [0|0] "" Vector__XXX
 SG_ PCS2_a006_chgMainStateMachineState m6 : 17|4@1+ (1,0) [0|0] "" Vector__XXX
 SG_ PCS2_a007_chgMainStateMachineState m7 : 17|4@1+ (1,0) [0|0] "" Vector__XXX
 SG_ PCS2_a008_chgMainStateMachineState m8 : 17|4@1+ (1,0) [0|0] "" Vector__XXX
 SG_ PCS2_a009_chgMainStateMachineState m9 : 17|4@1+ (1,0) [0|0] "" Vector__XXX
 SG_ PCS2_a010_chgMainStateMachineState m10 : 17|4@1+ (1,0) [0|0] "" Vector__XXX
 SG_ PCS2_a011_hvdcMaxThreshold m11 : 17|13@1- (0.1,0) [0|0] "" Vector__XXX
 SG_ PCS2_a021_10V0RailUnderVoltageTrip m21 : 17|1@1+ (1,0) [0|0] "" Vector__XXX
 SG_ PCS2_a051_BMS_chargeStatus m51 : 17|1@1+ (1,0) [0|0] "" Vector__XXX
 SG_ PCS2_a052_CP_status m52 : 17|1@1+ (1,0) [0|0] "" Vector__XXX
 SG_ PCS2_a053_HVP_hvsControl m53 : 17|1@1+ (1,0) [0|0] "" Vector__XXX
 SG_ PCS2_a055_leakageInductanceDefined m55 : 17|1@1+ (1,0) [0|0] "" Vector__XXX
 SG_ PCS2_a056_leakageInductanceDefined m56 : 17|1@1+ (1,0) [0|0] "" Vector__XXX
 SG_ PCS2_a057_leakageInductanceDefined m57 : 17|1@1+ (1,0) [0|0] "" Vector__XXX
 SG_ PCS2_a058_leakageInductanceDefined m58 : 17|1@1+ (1,0) [0|0] "" Vector__XXX
 SG_ PCS2_a059_dcdcHvcEnableLineStatus m59 : 17|1@1+ (1,0) [0|0] "" Vector__XXX
 SG_ PCS2_a069_recordOversized m69 : 17|1@1+ (1,0) [0|0] "" Vector__XXX
 SG_ PCS2_a070_recordOversized m70 : 17|1@1+ (1,0) [0|0] "" Vector__XXX
 SG_ PCS2_a085_dcacTZFlagStatus m85 : 17|1@1+ (1,0) [0|0] "" Vector__XXX
 SG_ PCS2_a122_recordOversized m122 : 17|1@1+ (1,0) [0|0] "" Vector__XXX
 SG_ PCS2_a125_lnbp_state m125 : 17|1@1+ (1,0) [0|0] "" Vector__XXX
 SG_ PCS2_a142_AcLineGdpsDataOutOfSpec m142 : 17|1@1+ (1,0) [0|0] "" Vector__XXX
 SG_ PCS2_a143_AcTankGdpsDataOutOfSpec m143 : 17|1@1+ (1,0) [0|0] "" Vector__XXX
 SG_ PCS2_a144_DcTankGdpsDataOutOfSpec m144 : 17|1@1+ (1,0) [0|0] "" Vector__XXX
 SG_ PCS2_a145_DcdcHvdcGdpsDataOutOfSpec m145 : 17|1@1+ (1,0) [0|0] "" Vector__XXX
 SG_ PCS2_a147_10V0RailOverVoltageTrip m147 : 17|1@1+ (1,0) [0|0] "" Vector__XXX
 SG_ PCS2_a149_buckBoostRampFaultCount m149 : 17|5@1+ (1,0) [0|0] "" Vector__XXX
 SG_ PCS2_a154_adcReferenceOutOfSpec m154 : 17|1@1+ (1,0) [0|0] "" Vector__XXX
 SG_ PCS2_a156_VCFRONT_sensors m156 : 17|1@1+ (1,0) [0|0] "" Vector__XXX
 SG_ PCS2_a166_hvcTZLatchStatus m166 : 17|1@1+ (1,0) [0|0] "" Vector__XXX
 SG_ PCS2_a001_CPU2_watchdog_alarmed m1 : 18|1@1+ (1,0) [0|0] "" Vector__XXX
 SG_ PCS2_a021_18V0RailUnderVoltageTrip m21 : 18|1@1+ (1,0) [0|0] "" Vector__XXX
 SG_ PCS2_a051_BMS_gridFormControl m51 : 18|1@1+ (1,0) [0|0] "" Vector__XXX
 SG_ PCS2_a052_CP_gridFormControl m52 : 18|1@1+ (1,0) [0|0] "" Vector__XXX
 SG_ PCS2_a055_magnetizingInductanceDefined m55 : 18|1@1+ (1,0) [0|0] "" Vector__XXX
 SG_ PCS2_a056_magnetizingInductanceDefined m56 : 18|1@1+ (1,0) [0|0] "" Vector__XXX
 SG_ PCS2_a057_magnetizingInductanceDefined m57 : 18|1@1+ (1,0) [0|0] "" Vector__XXX
 SG_ PCS2_a058_magnetizingInductanceDefined m58 : 18|1@1+ (1,0) [0|0] "" Vector__XXX
 SG_ PCS2_a059_dcdcVcrEnableLineTZLatchedBit m59 : 18|1@1+ (1,0) [0|0] "" Vector__XXX
 SG_ PCS2_a069_recordUndersized m69 : 18|1@1+ (1,0) [0|0] "" Vector__XXX
 SG_ PCS2_a070_recordUndersized m70 : 18|1@1+ (1,0) [0|0] "" Vector__XXX
 SG_ PCS2_a085_bmsEnableRequest m85 : 18|1@1+ (1,0) [0|0] "" Vector__XXX
 SG_ PCS2_a101_lineToChassisVoltage m101 : 18|10@1- (1,0) [0|0] "" Vector__XXX
 SG_ PCS2_a122_recordUndersized m122 : 18|1@1+ (1,0) [0|0] "" Vector__XXX
 SG_ PCS2_a125_lntn_state m125 : 18|1@1+ (1,0) [0|0] "" Vector__XXX
 SG_ PCS2_a127_dcac1_L1EnableHealthStatus m127 : 18|2@1+ (1,0) [0|0] "" Vector__XXX
 SG_ PCS2_a128_dcac2_L1EnableHealthStatus m128 : 18|2@1+ (1,0) [0|0] "" Vector__XXX
 SG_ PCS2_a142_AcLineGdpsDataStale m142 : 18|1@1+ (1,0) [0|0] "" Vector__XXX
 SG_ PCS2_a143_AcTankGdpsDataStale m143 : 18|1@1+ (1,0) [0|0] "" Vector__XXX
 SG_ PCS2_a144_DcTankGdpsDataStale m144 : 18|1@1+ (1,0) [0|0] "" Vector__XXX
 SG_ PCS2_a145_DcdcHvdcGdpsDataStale m145 : 18|1@1+ (1,0) [0|0] "" Vector__XXX
 SG_ PCS2_a147_18V0RailOverVoltageTrip m147 : 18|1@1+ (1,0) [0|0] "" Vector__XXX
 SG_ PCS2_a150_previousBurstMode m150 : 18|2@1+ (1,0) [0|0] "" Vector__XXX
 SG_ PCS2_a166_vcrEnableLineStatus m166 : 18|1@1+ (1,0) [0|0] "" Vector__XXX
 SG_ PCS2_a172_dcdcInternalRequest m172 : 18|2@1+ (1,0) [0|0] "" Vector__XXX
 SG_ PCS2_a001_CPU3_watchdog_alarmed m1 : 19|1@1+ (1,0) [0|0] "" Vector__XXX
 SG_ PCS2_a021_4V5RailUnderVoltageThreshold m21 : 19|5@1+ (1,0) [0|0] "" Vector__XXX
 SG_ PCS2_a051_BMS_pcsLimits m51 : 19|1@1+ (1,0) [0|0] "" Vector__XXX
 SG_ PCS2_a059_dcdcVcrEnableLineStatus m59 : 19|1@1+ (1,0) [0|0] "" Vector__XXX
 SG_ PCS2_a069_recordVersionMismatch m69 : 19|1@1+ (1,0) [0|0] "" Vector__XXX
 SG_ PCS2_a070_recordVersionMismatch m70 : 19|1@1+ (1,0) [0|0] "" Vector__XXX
 SG_ PCS2_a085_outletGridFormEnableRequest m85 : 19|1@1+ (1,0) [0|0] "" Vector__XXX
 SG_ PCS2_a094_cycloBBlockedReason m94 : 19|3@1+ (1,0) [0|0] "" Vector__XXX
 SG_ PCS2_a095_cycloBBlockedReason m95 : 19|3@1+ (1,0) [0|0] "" Vector__XXX
 SG_ PCS2_a102_lineToLineVoltage m102 : 19|10@1- (1,0) [0|0] "" Vector__XXX
 SG_ PCS2_a122_recordVersionMismatch m122 : 19|1@1+ (1,0) [0|0] "" Vector__XXX
 SG_ PCS2_a124_L1NInstantaneousVoltage m124 : 19|7@1- (10,0) [0|0] "" Vector__XXX
 SG_ PCS2_a125_lnbn_state m125 : 19|1@1+ (1,0) [0|0] "" Vector__XXX
 SG_ PCS2_a126_ipcCpu1LockSuccessiveGrabFailCount m126 : 19|3@1+ (1,0) [0|0] "" Vector__XXX
 SG_ PCS2_a147_BuckBoostLVInputOVTrip m147 : 19|1@1+ (1,0) [0|0] "" Vector__XXX
 SG_ PCS2_a166_hvcEnableLineStatus m166 : 19|1@1+ (1,0) [0|0] "" Vector__XXX
 SG_ PCS2_a001_power_on_reset_triggered m1 : 20|1@1+ (1,0) [0|0] "" Vector__XXX
 SG_ PCS2_a051_BMS_packConfig m51 : 20|1@1+ (1,0) [0|0] "" Vector__XXX
 SG_ PCS2_a059_dcdcStageState m59 : 20|3@1+ (1,0) [0|0] "" Vector__XXX
 SG_ PCS2_a060_retryCount m60 : 20|4@1+ (1,0) [0|0] "" Vector__XXX
 SG_ PCS2_a061_retryCount m61 : 20|4@1+ (1,0) [0|0] "" Vector__XXX
 SG_ PCS2_a069_recordCRCMismatch m69 : 20|1@1+ (1,0) [0|0] "" Vector__XXX
 SG_ PCS2_a070_recordCRCMismatch m70 : 20|1@1+ (1,0) [0|0] "" Vector__XXX
 SG_ PCS2_a085_cpGridFormEnableRequest m85 : 20|1@1+ (1,0) [0|0] "" Vector__XXX
 SG_ PCS2_a103_IsoTempSenseIrrational m103 : 20|1@1+ (1,0) [0|0] "" Vector__XXX
 SG_ PCS2_a122_recordCRCMismatch m122 : 20|1@1+ (1,0) [0|0] "" Vector__XXX
 SG_ PCS2_a127_dcac1_L2EnableHealthStatus m127 : 20|2@1+ (1,0) [0|0] "" Vector__XXX
 SG_ PCS2_a128_dcac2_L2EnableHealthStatus m128 : 20|2@1+ (1,0) [0|0] "" Vector__XXX
 SG_ PCS2_a136_mosfetLegUnderTest m136 : 20|3@1+ (1,0) [0|0] "" Vector__XXX
 SG_ PCS2_a137_mosfetLegUnderTest m137 : 20|3@1+ (1,0) [0|0] "" Vector__XXX
 SG_ PCS2_a172_dcdcStageState m172 : 20|3@1+ (1,0) [0|0] "" Vector__XXX
 SG_ PCS2_a001_software_reset_requested m1 : 21|1@1+ (1,0) [0|0] "" Vector__XXX
 SG_ PCS2_a004_gridFormStateMachineState m4 : 21|3@1+ (1,0) [0|0] "" Vector__XXX
 SG_ PCS2_a005_gridFormStateMachineState m5 : 21|3@1+ (1,0) [0|0] "" Vector__XXX
 SG_ PCS2_a006_gridFormStateMachineState m6 : 21|3@1+ (1,0) [0|0] "" Vector__XXX
 SG_ PCS2_a007_gridFormStateMachineState m7 : 21|3@1+ (1,0) [0|0] "" Vector__XXX
 SG_ PCS2_a008_gridFormStateMachineState m8 : 21|3@1+ (1,0) [0|0] "" Vector__XXX
 SG_ PCS2_a009_gridFormStateMachineState m9 : 21|3@1+ (1,0) [0|0] "" Vector__XXX
 SG_ PCS2_a010_gridFormStateMachineState m10 : 21|3@1+ (1,0) [0|0] "" Vector__XXX
 SG_ PCS2_a051_HVBATT_pcsAuxRequest m51 : 21|1@1+ (1,0) [0|0] "" Vector__XXX
 SG_ PCS2_a085_packEOLGridFormEnableRequest m85 : 21|1@1+ (1,0) [0|0] "" Vector__XXX
 SG_ PCS2_a092_zcd_error_pu m92 : 21|7@1+ (0.01,0) [0|0] "" Vector__XXX
 SG_ PCS2_a103_IsoTempSenseOutOfBounds m103 : 21|1@1+ (1,0) [0|0] "" Vector__XXX
 SG_ PCS2_a001_reset_pin_asserted m1 : 22|1@1+ (1,0) [0|0] "" Vector__XXX
 SG_ PCS2_a051_BMS_coolantStatus m51 : 22|1@1+ (1,0) [0|0] "" Vector__XXX
 SG_ PCS2_a103_IsoTempSensorFallTimeOutOfBounds m103 : 22|1@1+ (1,0) [0|0] "" Vector__XXX
 SG_ PCS2_a127_dcac1_L3EnableHealthStatus m127 : 22|2@1+ (1,0) [0|0] "" Vector__XXX
 SG_ PCS2_a128_dcac2_L3EnableHealthStatus m128 : 22|2@1+ (1,0) [0|0] "" Vector__XXX
 SG_ PCS2_a175_lvBusVoltageTarget m175 : 22|6@1+ (1,1) [0|0] "" Vector__XXX
 SG_ PCS2_a001_hardware_security_watchdog_alarmed m1 : 23|1@1+ (1,0) [0|0] "" Vector__XXX
 SG_ PCS2_a103_IsoTempSensorRiseTimeOutOfBounds m103 : 23|1@1+ (1,0) [0|0] "" Vector__XXX
 SG_ PCS2_a172_vcrEfuseState m172 : 23|1@1+ (1,0) [0|0] "" Vector__XXX
 SG_ PCS2_a001_debugger_warm_reset m1 : 24|1@1+ (1,0) [0|0] "" Vector__XXX
 SG_ PCS2_a002_canID m2 : 24|32@1+ (1,0) [0|0] "" Vector__XXX
 SG_ PCS2_a004_acManagerOperatingMode m4 : 24|4@1+ (1,0) [0|0] "" Vector__XXX
 SG_ PCS2_a005_acManagerOperatingMode m5 : 24|4@1+ (1,0) [0|0] "" Vector__XXX
 SG_ PCS2_a006_acManagerOperatingMode m6 : 24|4@1+ (1,0) [0|0] "" Vector__XXX
 SG_ PCS2_a007_acManagerOperatingMode m7 : 24|4@1+ (1,0) [0|0] "" Vector__XXX
 SG_ PCS2_a008_acManagerOperatingMode m8 : 24|4@1+ (1,0) [0|0] "" Vector__XXX
 SG_ PCS2_a009_acManagerOperatingMode m9 : 24|4@1+ (1,0) [0|0] "" Vector__XXX
 SG_ PCS2_a010_acManagerOperatingMode m10 : 24|4@1+ (1,0) [0|0] "" Vector__XXX
 SG_ PCS2_a021_10V0RailUnderVoltageThreshold m21 : 24|5@1+ (1,0) [0|0] "" Vector__XXX
 SG_ PCS2_a033_longestModuleIndex m33 : 24|6@1+ (1,0) [0|0] "" Vector__XXX
 SG_ PCS2_a059_dcdcStageRequestProcessed m59 : 24|2@1+ (1,0) [0|0] "" Vector__XXX
 SG_ PCS2_a060_pauseRequestedByDcdc m60 : 24|1@1+ (1,0) [0|0] "" Vector__XXX
 SG_ PCS2_a061_pauseRequestedByDcdc m61 : 24|1@1+ (1,0) [0|0] "" Vector__XXX
 SG_ PCS2_a062_acL2NVrms m62 : 24|7@1+ (3,0) [0|0] "" Vector__XXX
 SG_ PCS2_a063_phase_diff_L1N_L3N m63 : 24|8@1+ (1,0) [0|0] "" Vector__XXX
 SG_ PCS2_a068_diagnosticWord m68 : 24|32@1+ (1,0) [0|0] "" Vector__XXX
 SG_ PCS2_a088_startVoltageRms m88 : 24|7@1+ (3,0) [0|0] "" Vector__XXX
 SG_ PCS2_a099_lineToChassisVoltageRms m99 : 24|7@1+ (3,0) [0|0] "" Vector__XXX
 SG_ PCS2_a100_lineToLineVoltageRms m100 : 24|7@1+ (3,0) [0|0] "" Vector__XXX
 SG_ PCS2_a103_IsoTempSensorMIA m103 : 24|1@1+ (1,0) [0|0] "" Vector__XXX
 SG_ PCS2_a104_lineToChassisVoltageRms m104 : 24|7@1+ (3,0) [0|0] "" Vector__XXX
 SG_ PCS2_a105_lineToLineVoltageRms m105 : 24|7@1+ (3,0) [0|0] "" Vector__XXX
 SG_ PCS2_a106_systemNeutralToChassisVoltage m106 : 24|7@1+ (3,0) [0|0] "" Vector__XXX
 SG_ PCS2_a107_line_2_damper_current m107 : 24|6@1- (1,0) [0|0] "" Vector__XXX
 SG_ PCS2_a110_combinedDeratingFactor m110 : 24|7@1+ (0.01,0) [0|0] "" Vector__XXX
 SG_ PCS2_a112_startVoltageRms m112 : 24|7@1+ (3,0) [0|0] "" Vector__XXX
 SG_ PCS2_a121_maxDcdcLvModelTemp m121 : 24|8@1- (1,46) [0|0] "" Vector__XXX
 SG_ PCS2_a126_ipcCpu2LockSuccessiveGrabFailCount m126 : 24|3@1+ (1,0) [0|0] "" Vector__XXX
 SG_ PCS2_a127_dcac1_LNEnableHealthStatus m127 : 24|2@1+ (1,0) [0|0] "" Vector__XXX
 SG_ PCS2_a128_dcac2_LNEnableHealthStatus m128 : 24|2@1+ (1,0) [0|0] "" Vector__XXX
 SG_ PCS2_a129_lvBusVoltage m129 : 24|10@1+ (0.1,0) [0|0] "" Vector__XXX
 SG_ PCS2_a130_retriesAttempted m130 : 24|8@1+ (1,0) [0|0] "" Vector__XXX
 SG_ PCS2_a131_microgridHeartbeat2hzRms m131 : 24|8@1+ (0.001,0) [0|0] "" Vector__XXX
 SG_ PCS2_a136_mosfetIndexUnderTest m136 : 24|4@1+ (1,0) [0|0] "" Vector__XXX
 SG_ PCS2_a137_mosfetIndexUnderTest m137 : 24|4@1+ (1,0) [0|0] "" Vector__XXX
 SG_ PCS2_a140_halfBusHvTopVoltage m140 : 24|11@1+ (1,0) [0|0] "" Vector__XXX
 SG_ PCS2_a147_4V5RailOverVoltageThreshold m147 : 24|5@1+ (1,0) [0|0] "" Vector__XXX
 SG_ PCS2_a148_l2nPostRelayVoltage m148 : 24|7@1- (10,0) [0|0] "" Vector__XXX
 SG_ PCS2_a149_buckBoostCmpssFaultCount m149 : 24|5@1+ (1,0) [0|0] "" Vector__XXX
 SG_ PCS2_a150_levelNotFinishedCounts m150 : 24|6@1+ (1,0) [0|0] "" Vector__XXX
 SG_ PCS2_a153_zcd_rising_pu m153 : 24|7@1+ (0.01,0) [0|0] "" Vector__XXX
 SG_ PCS2_a164_zcdRisingPu m164 : 24|7@1+ (0.01,0) [0|0] "" Vector__XXX
 SG_ PCS2_a165_dutyS m165 : 24|7@1+ (0.01,0) [0|0] "" Vector__XXX
 SG_ PCS2_a172_vcrEfuseCommandedState m172 : 24|1@1+ (1,0) [0|0] "" Vector__XXX
 SG_ PCS2_a001_cpuID m1 : 25|3@1+ (1,0) [0|0] "" Vector__XXX
 SG_ PCS2_a090_DcdcModelLvMosfetCoolantTemp m90 : 25|9@1- (1,106) [0|0] "" Vector__XXX
 SG_ PCS2_a091_DcdcModelTxWindingCoolantTemp m91 : 25|9@1- (1,106) [0|0] "" Vector__XXX
 SG_ PCS2_a103_IsoTempSensorRiseFallMismatch m103 : 25|1@1+ (1,0) [0|0] "" Vector__XXX
 SG_ PCS2_a109_chgMainStateMachineState m109 : 25|4@1+ (1,0) [0|0] "" Vector__XXX
 SG_ PCS2_a113_receivedCoolantTemp m113 : 25|11@1- (0.15,70.05) [0|0] "" Vector__XXX
 SG_ PCS2_a116_maxChgRetriesAllowed m116 : 25|9@1+ (0.1,0) [0|0] "" Vector__XXX
 SG_ PCS2_a158_DcdcModelHvMosfetCoolantTemp m158 : 25|9@1- (1,106) [0|0] "" Vector__XXX
 SG_ PCS2_a059_dcdcRequest m59 : 26|2@1+ (1,0) [0|0] "" Vector__XXX
 SG_ PCS2_a103_RiseTimeOpenLoop m103 : 26|11@1+ (50,0) [0|0] "" Vector__XXX
 SG_ PCS2_a114_estimatedResistanceLinear m114 : 26|16@1+ (10,0) [0|0] "" Vector__XXX
 SG_ PCS2_a124_L2NInstantaneousVoltage m124 : 26|7@1- (10,0) [0|0] "" Vector__XXX
 SG_ PCS2_a127_dcac1_acTankClkHealthStatus m127 : 26|2@1+ (1,0) [0|0] "" Vector__XXX
 SG_ PCS2_a128_dcac2_acTankClkHealthStatus m128 : 26|2@1+ (1,0) [0|0] "" Vector__XXX
 SG_ PCS2_a146_leg2_Irms m146 : 26|10@1+ (0.1,0) [0|0] "" Vector__XXX
 SG_ PCS2_a169_sequence m169 : 26|4@1+ (1,0) [0|0] "" Vector__XXX
 SG_ PCS2_a013_DcdcALv2TempUpperThreshold m13 : 27|11@1- (0.15,70.05) [0|0] "" Vector__XXX
 SG_ PCS2_a015_DcdcAHvTempUpperThreshold m15 : 27|11@1- (0.15,70.05) [0|0] "" Vector__XXX
 SG_ PCS2_a017_DcdcBLv2TempUpperThreshold m17 : 27|11@1- (0.15,70.05) [0|0] "" Vector__XXX
 SG_ PCS2_a019_DcacADcTempUpperThreshold m19 : 27|11@1- (0.15,70.05) [0|0] "" Vector__XXX
 SG_ PCS2_a020_DcacBDcTempUpperThreshold m20 : 27|11@1- (0.15,70.05) [0|0] "" Vector__XXX
 SG_ PCS2_a024_DcacATxTempUpperThreshold m24 : 27|11@1- (0.15,70.05) [0|0] "" Vector__XXX
 SG_ PCS2_a025_DcacBTxTempUpperThreshold m25 : 27|11@1- (0.15,70.05) [0|0] "" Vector__XXX
 SG_ PCS2_a026_AcConnectorTempUpperThreshold m26 : 27|11@1- (0.15,70.05) [0|0] "" Vector__XXX
 SG_ PCS2_a027_AmbientTempUpperThreshold m27 : 27|11@1- (0.15,70.05) [0|0] "" Vector__XXX
 SG_ PCS2_a028_CoolantTempUpperThreshold m28 : 27|11@1- (0.15,70.05) [0|0] "" Vector__XXX
 SG_ PCS2_a029_DcacAAc1TempUpperThreshold m29 : 27|11@1- (0.15,70.05) [0|0] "" Vector__XXX
 SG_ PCS2_a030_DcacAAc2TempUpperThreshold m30 : 27|11@1- (0.15,70.05) [0|0] "" Vector__XXX
 SG_ PCS2_a031_DcacBAc1TempUpperThreshold m31 : 27|11@1- (0.15,70.05) [0|0] "" Vector__XXX
 SG_ PCS2_a032_DcacBAc2TempUpperThreshold m32 : 27|11@1- (0.15,70.05) [0|0] "" Vector__XXX
 SG_ PCS2_a036_hvBusTopVoltage m36 : 27|11@1+ (1,0) [0|0] "" Vector__XXX
 SG_ PCS2_a037_hvBusTopVoltage m37 : 27|11@1+ (1,0) [0|0] "" Vector__XXX
 SG_ PCS2_a038_hvBusTopVoltage m38 : 27|11@1+ (1,0) [0|0] "" Vector__XXX
 SG_ PCS2_a039_hvBusTopVoltage m39 : 27|11@1+ (1,0) [0|0] "" Vector__XXX
 SG_ PCS2_a040_hvBusTopVoltage m40 : 27|11@1+ (1,0) [0|0] "" Vector__XXX
 SG_ PCS2_a041_hvBusTopVoltage m41 : 27|11@1+ (1,0) [0|0] "" Vector__XXX
 SG_ PCS2_a042_hvBattTopVoltage m42 : 27|11@1+ (1,0) [0|0] "" Vector__XXX
 SG_ PCS2_a043_hvBattTopVoltage m43 : 27|11@1+ (1,0) [0|0] "" Vector__XXX
 SG_ PCS2_a044_hvBattTopVoltage m44 : 27|11@1+ (1,0) [0|0] "" Vector__XXX
 SG_ PCS2_a045_hvBattTopVoltage m45 : 27|11@1+ (1,0) [0|0] "" Vector__XXX
 SG_ PCS2_a046_hvBattTopVoltage m46 : 27|11@1+ (1,0) [0|0] "" Vector__XXX
 SG_ PCS2_a047_hvBattTopVoltage m47 : 27|11@1+ (1,0) [0|0] "" Vector__XXX
 SG_ PCS2_a048_hvBusTopVoltage m48 : 27|11@1+ (1,0) [0|0] "" Vector__XXX
 SG_ PCS2_a049_hvBusTopVoltage m49 : 27|11@1+ (1,0) [0|0] "" Vector__XXX
 SG_ PCS2_a118_hvVoltageTarget m118 : 27|11@1+ (1,0) [0|0] "" Vector__XXX
 SG_ PCS2_a119_startUpHvVoltage m119 : 27|11@1+ (1,0) [0|0] "" Vector__XXX
 SG_ PCS2_a123_DcdcBHvTempUpperThreshold m123 : 27|11@1- (0.15,70.05) [0|0] "" Vector__XXX
 SG_ PCS2_a126_ipcCpu3LockSuccessiveGrabFailCount m126 : 27|3@1+ (1,0) [0|0] "" Vector__XXX
 SG_ PCS2_a151_DcdcBLv1TempUpperThreshold m151 : 27|11@1- (0.15,70.05) [0|0] "" Vector__XXX
 SG_ PCS2_a152_DcdcBLv3TempUpperThreshold m152 : 27|11@1- (0.15,70.05) [0|0] "" Vector__XXX
 SG_ PCS2_a064_leakageInductanceOutOfSpec m64 : 28|1@1+ (1,0) [0|0] "" Vector__XXX
 SG_ PCS2_a065_leakageInductanceOutOfSpec m65 : 28|1@1+ (1,0) [0|0] "" Vector__XXX
 SG_ PCS2_a066_leakageInductanceOutOfSpec m66 : 28|1@1+ (1,0) [0|0] "" Vector__XXX
 SG_ PCS2_a067_leakageInductanceOutOfSpec m67 : 28|1@1+ (1,0) [0|0] "" Vector__XXX
 SG_ PCS2_a071_hvBattExternalRefValue m71 : 28|11@1+ (1,0) [0|0] "" Vector__XXX
 SG_ PCS2_a072_hvBattExternalRefValue m72 : 28|11@1+ (1,0) [0|0] "" Vector__XXX
 SG_ PCS2_a073_hvBusExternalRefValue m73 : 28|11@1+ (1,0) [0|0] "" Vector__XXX
 SG_ PCS2_a074_hvBusExternalRefValue m74 : 28|11@1+ (1,0) [0|0] "" Vector__XXX
 SG_ PCS2_a075_hvBattExternalRefValue m75 : 28|11@1+ (1,0) [0|0] "" Vector__XXX
 SG_ PCS2_a076_hvBusExternalRefValue m76 : 28|11@1+ (1,0) [0|0] "" Vector__XXX
 SG_ PCS2_a081_acL1CurrentRMS m81 : 28|11@1- (0.1,0) [0|0] "" Vector__XXX
 SG_ PCS2_a082_acL2CurrentRMS m82 : 28|11@1- (0.1,0) [0|0] "" Vector__XXX
 SG_ PCS2_a083_acL3CurrentRMS m83 : 28|11@1- (0.1,0) [0|0] "" Vector__XXX
 SG_ PCS2_a084_acNCurrentRMS m84 : 28|11@1- (0.1,0) [0|0] "" Vector__XXX
 SG_ PCS2_a092_zcd_threshold_at_fault m92 : 28|4@1+ (0.01,0) [0|0] "" Vector__XXX
 SG_ PCS2_a127_dcac1_dcTankClkHealthStatus m127 : 28|2@1+ (1,0) [0|0] "" Vector__XXX
 SG_ PCS2_a128_dcac2_dcTankClkHealthStatus m128 : 28|2@1+ (1,0) [0|0] "" Vector__XXX
 SG_ PCS2_a136_measuredResonantFrequency m136 : 28|15@1+ (0.1,0) [0|0] "" Vector__XXX
 SG_ PCS2_a137_measuredResonantFrequency m137 : 28|15@1+ (0.1,0) [0|0] "" Vector__XXX
 SG_ PCS2_a162_cycloTankMagInductance m162 : 28|12@1+ (0.1,0) [0|0] "" Vector__XXX
 SG_ PCS2_a163_cycloTankMagInductance m163 : 28|12@1+ (0.1,0) [0|0] "" Vector__XXX
 SG_ PCS2_a175_hvBusVoltage m175 : 28|11@1+ (1,0) [0|0] "" Vector__XXX
 SG_ PCS2_a109_acManagerOperatingMode m109 : 29|4@1+ (1,0) [0|0] "" Vector__XXX
 SG_ PCS2_a132_L1NGridVoltage m132 : 29|8@1+ (2,0) [0|0] "" Vector__XXX
 SG_ PCS2_a149_buckBoost18VOVFault m149 : 29|1@1+ (1,0) [0|0] "" Vector__XXX
 SG_ PCS2_a033_qualifyCounts m33 : 30|4@1+ (1,0) [0|0] "" Vector__XXX
 SG_ PCS2_a127_dcac1_hvEnableHealthStatus m127 : 30|2@1+ (1,0) [0|0] "" Vector__XXX
 SG_ PCS2_a128_dcac2_hvEnableHealthStatus m128 : 30|2@1+ (1,0) [0|0] "" Vector__XXX
 SG_ PCS2_a149_buckBoostInputOVFault m149 : 30|1@1+ (1,0) [0|0] "" Vector__XXX
 SG_ PCS2_a168_timeBelow50pct m168 : 30|14@1+ (0.002,0) [0|0] "" Vector__XXX
 SG_ PCS2_a149_buckBoost18VLeakyBucketFault m149 : 31|1@1+ (1,0) [0|0] "" Vector__XXX
 SG_ PCS2_a005_acL1MaxThreshold m5 : 32|13@1- (0.1,0) [0|0] "" Vector__XXX
 SG_ PCS2_a007_acL2MaxThreshold m7 : 32|13@1- (0.1,0) [0|0] "" Vector__XXX
 SG_ PCS2_a009_acL3MaxThreshold m9 : 32|13@1- (0.1,0) [0|0] "" Vector__XXX
 SG_ PCS2_a011_hvdcMinThreshold m11 : 32|13@1- (0.1,0) [0|0] "" Vector__XXX
 SG_ PCS2_a021_18V0RailUnderVoltageThreshold m21 : 32|5@1+ (1,0) [0|0] "" Vector__XXX
 SG_ PCS2_a034_voltageFaultThreshold m34 : 32|13@1+ (0.01,0) [0|0] "" Vector__XXX
 SG_ PCS2_a035_voltageFaultThreshold m35 : 32|13@1+ (0.01,0) [0|0] "" Vector__XXX
 SG_ PCS2_a062_acL3NVrms m62 : 32|7@1+ (3,0) [0|0] "" Vector__XXX
 SG_ PCS2_a063_phase_diff_L2N_L3N m63 : 32|8@1+ (1,0) [0|0] "" Vector__XXX
 SG_ PCS2_a064_magnetizingInductance m64 : 32|12@1+ (0.1,0) [0|0] "" Vector__XXX
 SG_ PCS2_a065_magnetizingInductance m65 : 32|12@1+ (0.1,0) [0|0] "" Vector__XXX
 SG_ PCS2_a066_magnetizingInductance m66 : 32|12@1+ (0.1,0) [0|0] "" Vector__XXX
 SG_ PCS2_a067_magnetizingInductance m67 : 32|12@1+ (0.1,0) [0|0] "" Vector__XXX
 SG_ PCS2_a077_lvBusExternalRefValue m77 : 32|13@1+ (0.01,0) [0|0] "" Vector__XXX
 SG_ PCS2_a078_acL1NVoltageRMS m78 : 32|7@1+ (3,0) [0|0] "" Vector__XXX
 SG_ PCS2_a079_acL2NVoltageRMS m79 : 32|7@1+ (3,0) [0|0] "" Vector__XXX
 SG_ PCS2_a080_acL3NVoltageRMS m80 : 32|7@1+ (3,0) [0|0] "" Vector__XXX
 SG_ PCS2_a086_voltageFaultThreshold m86 : 32|13@1+ (0.01,0) [0|0] "" Vector__XXX
 SG_ PCS2_a087_voltageFaultThreshold m87 : 32|13@1+ (0.01,0) [0|0] "" Vector__XXX
 SG_ PCS2_a088_underVoltageRmsThreshold m88 : 32|7@1+ (3,0) [0|0] "" Vector__XXX
 SG_ PCS2_a092_zcd_fault_counter_limit m92 : 32|5@1+ (1,0) [0|0] "" Vector__XXX
 SG_ PCS2_a099_neutralToChassisVoltageRms m99 : 32|7@1+ (3,0) [0|0] "" Vector__XXX
 SG_ PCS2_a100_overVoltageRmsThreshold m100 : 32|7@1+ (3,0) [0|0] "" Vector__XXX
 SG_ PCS2_a101_neutralToChassisVoltage m101 : 32|8@1- (5,0) [0|0] "" Vector__XXX
 SG_ PCS2_a102_lineToLineVoltageRms m102 : 32|7@1+ (3,0) [0|0] "" Vector__XXX
 SG_ PCS2_a104_underVoltageRmsThreshold m104 : 32|7@1+ (3,0) [0|0] "" Vector__XXX
 SG_ PCS2_a105_underVoltageRmsThreshold m105 : 32|7@1+ (3,0) [0|0] "" Vector__XXX
 SG_ PCS2_a106_overVoltageThreshold m106 : 32|7@1+ (3,0) [0|0] "" Vector__XXX
 SG_ PCS2_a107_line_3_damper_current m107 : 32|6@1- (1,0) [0|0] "" Vector__XXX
 SG_ PCS2_a110_txTempDeratingFactor m110 : 32|7@1+ (0.01,0) [0|0] "" Vector__XXX
 SG_ PCS2_a112_underVoltageRmsThreshold m112 : 32|7@1+ (3,0) [0|0] "" Vector__XXX
 SG_ PCS2_a121_remoteCoolantTemp m121 : 32|8@1- (1,46) [0|0] "" Vector__XXX
 SG_ PCS2_a127_dcac1_HealthCheckRetryCnt m127 : 32|5@1+ (1,0) [0|0] "" Vector__XXX
 SG_ PCS2_a128_dcac2_HealthCheckRetryCnt m128 : 32|5@1+ (1,0) [0|0] "" Vector__XXX
 SG_ PCS2_a147_10V0RailOverVoltageThreshold m147 : 32|5@1+ (1,0) [0|0] "" Vector__XXX
 SG_ PCS2_a148_l3nPostRelayVoltage m148 : 32|7@1- (10,0) [0|0] "" Vector__XXX
 SG_ PCS2_a149_buckBoost18VUVCmpssFault m149 : 32|1@1+ (1,0) [0|0] "" Vector__XXX
 SG_ PCS2_a150_burstOnCycles m150 : 32|3@1+ (1,0) [0|0] "" Vector__XXX
 SG_ PCS2_a153_zcd_falling_pu m153 : 32|7@1+ (0.01,0) [0|0] "" Vector__XXX
 SG_ PCS2_a164_thetaP m164 : 32|7@1- (0.05,0) [0|0] "" Vector__XXX
 SG_ PCS2_a165_fallingEdgeWindowPu m165 : 32|7@1+ (0.01,0) [0|0] "" Vector__XXX
 SG_ PCS2_a169_mosfetLegUnderTest m169 : 32|3@1+ (1,0) [0|0] "" Vector__XXX
 SG_ PCS2_a109_acRelayState m109 : 33|3@1+ (1,0) [0|0] "" Vector__XXX
 SG_ PCS2_a124_L3NInstantaneousVoltage m124 : 33|7@1- (10,0) [0|0] "" Vector__XXX
 SG_ PCS2_a149_buckBoostLVOVCmpssFault m149 : 33|1@1+ (1,0) [0|0] "" Vector__XXX
 SG_ PCS2_a033_longestModuleUtilizationPercentage m33 : 34|8@1+ (1,0) [0|0] "" Vector__XXX
 SG_ PCS2_a129_instantMeasuredZCDEvent m129 : 34|9@1+ (5,-1000) [0|0] "" Vector__XXX
 SG_ PCS2_a149_buckBoostLVUVCmpssFault m149 : 34|1@1+ (1,0) [0|0] "" Vector__XXX
 SG_ PCS2_a140_halfBusHvBotVoltage m140 : 35|11@1+ (1,0) [0|0] "" Vector__XXX
 SG_ PCS2_a149_buckBoostRetryPreventedFault m149 : 35|1@1+ (1,0) [0|0] "" Vector__XXX
 SG_ PCS2_a169_mosfetIndexUnderTest m169 : 35|4@1+ (1,0) [0|0] "" Vector__XXX
 SG_ PCS2_a109_acL1L2PeakVoltage m109 : 36|8@1+ (5,0) [0|0] "" Vector__XXX
 SG_ PCS2_a113_sensedCoolantTemp m113 : 36|11@1- (0.15,70.05) [0|0] "" Vector__XXX
 SG_ PCS2_a146_leg3_Irms m146 : 36|10@1+ (0.1,0) [0|0] "" Vector__XXX
 SG_ PCS2_a149_buckBoostRampTarget m149 : 36|12@1+ (0.01,0) [0|0] "" Vector__XXX
 SG_ PCS2_a092_hvBusCurrent m92 : 37|8@1- (0.2,0) [0|0] "" Vector__XXX
 SG_ PCS2_a103_FallTimeOpenLoop m103 : 37|11@1+ (50,0) [0|0] "" Vector__XXX
 SG_ PCS2_a132_L2NGridVoltage m132 : 37|8@1+ (2,0) [0|0] "" Vector__XXX
 SG_ PCS2_a036_hvBusBotVoltage m36 : 38|11@1+ (1,0) [0|0] "" Vector__XXX
 SG_ PCS2_a037_hvBusBotVoltage m37 : 38|11@1+ (1,0) [0|0] "" Vector__XXX
 SG_ PCS2_a038_hvBusBotVoltage m38 : 38|11@1+ (1,0) [0|0] "" Vector__XXX
 SG_ PCS2_a039_hvBusBotVoltage m39 : 38|11@1+ (1,0) [0|0] "" Vector__XXX
 SG_ PCS2_a040_hvBusBotVoltage m40 : 38|11@1+ (1,0) [0|0] "" Vector__XXX
 SG_ PCS2_a041_hvBusBotVoltage m41 : 38|11@1+ (1,0) [0|0] "" Vector__XXX
 SG_ PCS2_a042_hvBattBotVoltage m42 : 38|11@1+ (1,0) [0|0] "" Vector__XXX
 SG_ PCS2_a043_hvBattBotVoltage m43 : 38|11@1+ (1,0) [0|0] "" Vector__XXX
 SG_ PCS2_a044_hvBattBotVoltage m44 : 38|11@1+ (1,0) [0|0] "" Vector__XXX
 SG_ PCS2_a045_hvBattBotVoltage m45 : 38|11@1+ (1,0) [0|0] "" Vector__XXX
 SG_ PCS2_a046_hvBattBotVoltage m46 : 38|11@1+ (1,0) [0|0] "" Vector__XXX
 SG_ PCS2_a047_hvBattBotVoltage m47 : 38|11@1+ (1,0) [0|0] "" Vector__XXX
 SG_ PCS2_a048_hvBusBotVoltage m48 : 38|11@1+ (1,0) [0|0] "" Vector__XXX
 SG_ PCS2_a049_hvBusBotVoltage m49 : 38|11@1+ (1,0) [0|0] "" Vector__XXX
 SG_ PCS2_a107_line_1_error m107 : 38|6@1+ (10,0) [0|0] "" Vector__XXX
 SG_ PCS2_a062_acL1L2Vrms m62 : 39|7@1+ (3,0) [0|0] "" Vector__XXX
 SG_ PCS2_a110_dcTempDeratingFactor m110 : 39|7@1+ (0.01,0) [0|0] "" Vector__XXX
 SG_ PCS2_a175_DcdcModelTxWindingTemp m175 : 39|7@1+ (1,50) [0|0] "" Vector__XXX
 SG_ PCS2_a063_phase_diff_L1L3_L2L3 m63 : 40|8@1+ (1,0) [0|0] "" Vector__XXX
 SG_ PCS2_a075_hvBattTopBottomVoltageDelta m75 : 40|11@1+ (1,0) [0|0] "" Vector__XXX
 SG_ PCS2_a076_hvBusTopBottomVoltageDelta m76 : 40|11@1+ (1,0) [0|0] "" Vector__XXX
 SG_ PCS2_a088_presentVoltageRms m88 : 40|7@1+ (3,0) [0|0] "" Vector__XXX
 SG_ PCS2_a090_DcDcModelLvMosfetCoolantFlowRate m90 : 40|8@1+ (0.2,0) [0|0] "" Vector__XXX
 SG_ PCS2_a091_DcDcModelTxWindingCoolantFlowRate m91 : 40|8@1+ (0.2,0) [0|0] "" Vector__XXX
 SG_ PCS2_a099_overVoltageRmsThreshold m99 : 40|7@1+ (3,0) [0|0] "" Vector__XXX
 SG_ PCS2_a100_iticCurveSection m100 : 40|3@1+ (1,0) [0|0] "" Vector__XXX
 SG_ PCS2_a101_lineToChassisVoltageRms m101 : 40|7@1+ (3,0) [0|0] "" Vector__XXX
 SG_ PCS2_a102_overVoltageThreshold m102 : 40|10@1- (1,0) [0|0] "" Vector__XXX
 SG_ PCS2_a104_iticCurveSection m104 : 40|2@1+ (1,0) [0|0] "" Vector__XXX
 SG_ PCS2_a105_iticCurveSection m105 : 40|2@1+ (1,0) [0|0] "" Vector__XXX
 SG_ PCS2_a112_presentVoltageRms m112 : 40|7@1+ (3,0) [0|0] "" Vector__XXX
 SG_ PCS2_a118_presentLvBusVoltage m118 : 40|13@1+ (0.01,0) [0|0] "" Vector__XXX
 SG_ PCS2_a119_presentLvBusVoltage m119 : 40|13@1+ (0.01,0) [0|0] "" Vector__XXX
 SG_ PCS2_a121_localCoolantTemp m121 : 40|8@1- (1,46) [0|0] "" Vector__XXX
 SG_ PCS2_a124_L1InstantaneousCurrentCmd m124 : 40|5@1- (10,0) [0|0] "" Vector__XXX
 SG_ PCS2_a127_dcac1_HealthCheckMaxRetry m127 : 40|5@1+ (1,0) [0|0] "" Vector__XXX
 SG_ PCS2_a128_dcac2_HealthCheckMaxRetry m128 : 40|5@1+ (1,0) [0|0] "" Vector__XXX
 SG_ PCS2_a147_18V0RailOverVoltageThreshold m147 : 40|5@1+ (1,0) [0|0] "" Vector__XXX
 SG_ PCS2_a148_l2nPreRelayVoltage m148 : 40|7@1- (10,0) [0|0] "" Vector__XXX
 SG_ PCS2_a153_zcd_half_period_pu m153 : 40|7@1+ (0.01,0) [0|0] "" Vector__XXX
 SG_ PCS2_a158_DcDcModelHvMosfetCoolantFlowRate m158 : 40|8@1+ (0.2,0) [0|0] "" Vector__XXX
 SG_ PCS2_a162_hvBusVoltage m162 : 40|7@1+ (10,100) [0|0] "" Vector__XXX
 SG_ PCS2_a163_storedTankCapacitance m163 : 40|10@1+ (0.1,50) [0|0] "" Vector__XXX
 SG_ PCS2_a164_thetaS m164 : 40|7@1- (0.05,0) [0|0] "" Vector__XXX
 SG_ PCS2_a165_risingEdgeWindowPu m165 : 40|7@1+ (0.01,0) [0|0] "" Vector__XXX
 SG_ PCS2_a169_measuredResonantFrequency m169 : 40|15@1+ (0.1,0) [0|0] "" Vector__XXX
 SG_ PCS2_a033_taskID m33 : 42|3@1+ (1,0) [0|0] "" Vector__XXX
 SG_ PCS2_a114_estimatedResistanceLogarithm m114 : 42|16@1+ (10,0) [0|0] "" Vector__XXX
 SG_ PCS2_a129_instantMeasuredZCDHalfPrdPU m129 : 43|7@1+ (0.01,0) [0|0] "" Vector__XXX
 SG_ PCS2_a136_retryCount m136 : 43|4@1+ (1,0) [0|0] "" Vector__XXX
 SG_ PCS2_a137_retryCount m137 : 43|4@1+ (1,0) [0|0] "" Vector__XXX
 SG_ PCS2_a064_magnetizingInductanceOutOfSpec m64 : 44|1@1+ (1,0) [0|0] "" Vector__XXX
 SG_ PCS2_a065_magnetizingInductanceOutOfSpec m65 : 44|1@1+ (1,0) [0|0] "" Vector__XXX
 SG_ PCS2_a066_magnetizingInductanceOutOfSpec m66 : 44|1@1+ (1,0) [0|0] "" Vector__XXX
 SG_ PCS2_a067_magnetizingInductanceOutOfSpec m67 : 44|1@1+ (1,0) [0|0] "" Vector__XXX
 SG_ PCS2_a107_line_2_error m107 : 44|6@1+ (10,0) [0|0] "" Vector__XXX
 SG_ PCS2_a109_acL1L3PeakVoltage m109 : 44|8@1+ (5,0) [0|0] "" Vector__XXX
 SG_ PCS2_a168_timeBelow30pct m168 : 44|14@1+ (0.002,0) [0|0] "" Vector__XXX
 SG_ PCS2_a005_acL1MinThreshold m5 : 45|13@1- (0.1,0) [0|0] "" Vector__XXX
 SG_ PCS2_a007_acL2MinThreshold m7 : 45|13@1- (0.1,0) [0|0] "" Vector__XXX
 SG_ PCS2_a009_acL3MinThreshold m9 : 45|13@1- (0.1,0) [0|0] "" Vector__XXX
 SG_ PCS2_a033_cycleSkewPercentage m33 : 45|8@1+ (1,0) [0|0] "" Vector__XXX
 SG_ PCS2_a064_capacitance m64 : 45|9@1+ (0.05,15) [0|0] "" Vector__XXX
 SG_ PCS2_a065_capacitance m65 : 45|9@1+ (0.05,15) [0|0] "" Vector__XXX
 SG_ PCS2_a066_capacitance m66 : 45|10@1+ (0.1,50) [0|0] "" Vector__XXX
 SG_ PCS2_a067_capacitance m67 : 45|10@1+ (0.1,50) [0|0] "" Vector__XXX
 SG_ PCS2_a092_lvBusVoltage m92 : 45|6@1+ (1,1) [0|0] "" Vector__XXX
 SG_ PCS2_a124_L2InstantaneousCurrentCmd m124 : 45|5@1- (10,0) [0|0] "" Vector__XXX
 SG_ PCS2_a132_L3NGridVoltage m132 : 45|8@1+ (2,0) [0|0] "" Vector__XXX
 SG_ PCS2_a062_acL1L3Vrms m62 : 46|7@1+ (3,0) [0|0] "" Vector__XXX
 SG_ PCS2_a110_inductorLossDeratingFactor m110 : 46|7@1+ (0.01,0) [0|0] "" Vector__XXX
 SG_ PCS2_a146_legN_Irms m146 : 46|10@1+ (0.1,0) [0|0] "" Vector__XXX
 SG_ PCS2_a175_DcdcModelLvMosfetTemp m175 : 46|7@1+ (1,50) [0|0] "" Vector__XXX
 SG_ PCS2_a088_presentCurrentRms m88 : 47|9@1+ (2,0) [0|0] "" Vector__XXX
 SG_ PCS2_a101_overVoltageThreshold m101 : 47|10@1- (1,0) [0|0] "" Vector__XXX
 SG_ PCS2_a113_localNoFlowDetectionState m113 : 47|1@1+ (1,0) [0|0] "" Vector__XXX
 SG_ PCS2_a136_externalFaultDetected m136 : 47|1@1+ (1,0) [0|0] "" Vector__XXX
 SG_ PCS2_a137_externalFaultDetected m137 : 47|1@1+ (1,0) [0|0] "" Vector__XXX
 SG_ PCS2_a063_L1NAvailableForCharging m63 : 48|1@1+ (1,0) [0|0] "" Vector__XXX
 SG_ PCS2_a090_DcDcModelLVMosfetCurrent m90 : 48|7@1+ (1,0) [0|0] "" Vector__XXX
 SG_ PCS2_a091_DcDcModelTxWindingCurrent m91 : 48|7@1+ (1,0) [0|0] "" Vector__XXX
 SG_ PCS2_a099_iticCurveSection m99 : 48|3@1+ (1,0) [0|0] "" Vector__XXX
 SG_ PCS2_a103_ClosedLoopTime m103 : 48|11@1+ (50,0) [0|0] "" Vector__XXX
 SG_ PCS2_a113_remoteNoFlowDetectionState m113 : 48|1@1+ (1,0) [0|0] "" Vector__XXX
 SG_ PCS2_a121_dcdcAActive m121 : 48|1@1+ (1,0) [0|0] "" Vector__XXX
 SG_ PCS2_a136_hvVoltage m136 : 48|11@1+ (1,0) [0|0] "" Vector__XXX
 SG_ PCS2_a137_hvVoltage m137 : 48|11@1+ (1,0) [0|0] "" Vector__XXX
 SG_ PCS2_a147_BuckBoostLVInputOVThreshold m147 : 48|5@1+ (1,0) [0|0] "" Vector__XXX
 SG_ PCS2_a148_l3nPreRelayVoltage m148 : 48|7@1- (10,0) [0|0] "" Vector__XXX
 SG_ PCS2_a153_switching_freq_kHz m153 : 48|10@1+ (1,150) [0|0] "" Vector__XXX
 SG_ PCS2_a158_DcDcModelHvMosfetCurrent m158 : 48|7@1+ (1,0) [0|0] "" Vector__XXX
 SG_ PCS2_a162_storedTankCapacitance m162 : 48|10@1+ (0.1,50) [0|0] "" Vector__XXX
 SG_ PCS2_a164_commandedSwitchFreq m164 : 48|10@1+ (1,150) [0|0] "" Vector__XXX
 SG_ PCS2_a165_tankCurrentCommand m165 : 48|11@1+ (0.1,0) [0|0] "" Vector__XXX
 SG_ PCS2_a036_voltageFaultThreshold m36 : 49|11@1+ (1,0) [0|0] "" Vector__XXX
 SG_ PCS2_a037_voltageFaultThreshold m37 : 49|11@1+ (1,0) [0|0] "" Vector__XXX
 SG_ PCS2_a038_voltageFaultThreshold m38 : 49|11@1+ (1,0) [0|0] "" Vector__XXX
 SG_ PCS2_a039_voltageFaultThreshold m39 : 49|11@1+ (1,0) [0|0] "" Vector__XXX
 SG_ PCS2_a040_voltageFaultThreshold m40 : 49|11@1+ (1,0) [0|0] "" Vector__XXX
 SG_ PCS2_a041_voltageFaultThreshold m41 : 49|11@1+ (1,0) [0|0] "" Vector__XXX
 SG_ PCS2_a042_voltageFaultThreshold m42 : 49|11@1+ (1,0) [0|0] "" Vector__XXX
 SG_ PCS2_a043_voltageFaultThreshold m43 : 49|11@1+ (1,0) [0|0] "" Vector__XXX
 SG_ PCS2_a044_voltageFaultThreshold m44 : 49|11@1+ (1,0) [0|0] "" Vector__XXX
 SG_ PCS2_a045_voltageFaultThreshold m45 : 49|11@1+ (1,0) [0|0] "" Vector__XXX
 SG_ PCS2_a046_voltageFaultThreshold m46 : 49|11@1+ (1,0) [0|0] "" Vector__XXX
 SG_ PCS2_a047_voltageFaultThreshold m47 : 49|11@1+ (1,0) [0|0] "" Vector__XXX
 SG_ PCS2_a048_voltageFaultThreshold m48 : 49|11@1+ (1,0) [0|0] "" Vector__XXX
 SG_ PCS2_a049_voltageFaultThreshold m49 : 49|11@1+ (1,0) [0|0] "" Vector__XXX
 SG_ PCS2_a063_L2NAvailableForCharging m63 : 49|1@1+ (1,0) [0|0] "" Vector__XXX
 SG_ PCS2_a121_dcdcBActive m121 : 49|1@1+ (1,0) [0|0] "" Vector__XXX
 SG_ PCS2_a063_L3NAvailableForCharging m63 : 50|1@1+ (1,0) [0|0] "" Vector__XXX
 SG_ PCS2_a102_iticCurveSection m102 : 50|3@1+ (1,0) [0|0] "" Vector__XXX
 SG_ PCS2_a107_line_3_error m107 : 50|6@1+ (10,0) [0|0] "" Vector__XXX
 SG_ PCS2_a121_dcdcAHasHigherLvTemp m121 : 50|1@1+ (1,0) [0|0] "" Vector__XXX
 SG_ PCS2_a124_L3InstantaneousCurrentCmd m124 : 50|5@1- (10,0) [0|0] "" Vector__XXX
 SG_ PCS2_a129_commandedSwitchFreq m129 : 50|10@1+ (1,150) [0|0] "" Vector__XXX
 SG_ PCS2_a163_hvBusVoltage m163 : 50|7@1+ (10,100) [0|0] "" Vector__XXX
 SG_ PCS2_a063_L1L2AvailableForCharging m63 : 51|1@1+ (1,0) [0|0] "" Vector__XXX
 SG_ PCS2_a092_hvBusVoltage m92 : 51|7@1+ (10,100) [0|0] "" Vector__XXX
 SG_ PCS2_a121_dcdcAHasHigherLvModeledTemp m121 : 51|1@1+ (1,0) [0|0] "" Vector__XXX
 SG_ PCS2_a063_L1L3AvailableForCharging m63 : 52|1@1+ (1,0) [0|0] "" Vector__XXX
 SG_ PCS2_a109_acL2L3PeakVoltage m109 : 52|8@1+ (5,0) [0|0] "" Vector__XXX
 SG_ PCS2_a121_cycloAActive m121 : 52|1@1+ (1,0) [0|0] "" Vector__XXX
 SG_ PCS2_a033_alertThreshold m33 : 53|7@1+ (1,0) [0|0] "" Vector__XXX
 SG_ PCS2_a062_acL2L3Vrms m62 : 53|7@1+ (3,0) [0|0] "" Vector__XXX
 SG_ PCS2_a063_L2L3AvailableForCharging m63 : 53|1@1+ (1,0) [0|0] "" Vector__XXX
 SG_ PCS2_a110_junctionTempDeratingFactor m110 : 53|7@1+ (0.01,0) [0|0] "" Vector__XXX
 SG_ PCS2_a118_failedToReachFixedTarget m118 : 53|1@1+ (1,0) [0|0] "" Vector__XXX
 SG_ PCS2_a121_cycloBActive m121 : 53|1@1+ (1,0) [0|0] "" Vector__XXX
 SG_ PCS2_a132_currentLimit m132 : 53|7@1+ (1,0) [0|0] "" Vector__XXX
 SG_ PCS2_a175_DcdcModelHvMosfetTemp m175 : 53|7@1+ (1,50) [0|0] "" Vector__XXX
 SG_ PCS2_a064_capacitanceOutOfSpec m64 : 54|1@1+ (1,0) [0|0] "" Vector__XXX
 SG_ PCS2_a065_capacitanceOutOfSpec m65 : 54|1@1+ (1,0) [0|0] "" Vector__XXX
 SG_ PCS2_a121_localRemoteCoolantDelta m121 : 54|1@1+ (1,0) [0|0] "" Vector__XXX
 SG_ PCS2_a066_capacitanceOutOfSpec m66 : 55|1@1+ (1,0) [0|0] "" Vector__XXX
 SG_ PCS2_a067_capacitanceOutOfSpec m67 : 55|1@1+ (1,0) [0|0] "" Vector__XXX
 SG_ PCS2_a121_lvSensorToLocalCoolantDelta m121 : 55|1@1+ (1,0) [0|0] "" Vector__XXX
 SG_ PCS2_a124_tankMargin m124 : 55|4@1+ (0.1,1) [0|0] "" Vector__XXX
 SG_ PCS2_a088_gridConfig m88 : 56|2@1+ (1,0) [0|0] "" Vector__XXX
 SG_ PCS2_a107_bmsEnableRequest m107 : 56|1@1+ (1,0) [0|0] "" Vector__XXX
 SG_ PCS2_a121_lvSensorToModeledTempDelta m121 : 56|1@1+ (1,0) [0|0] "" Vector__XXX
 SG_ PCS2_a146_legs_paralleled_by_relay m146 : 56|1@1+ (1,0) [0|0] "" Vector__XXX
 SG_ PCS2_a148_acRelayState m148 : 56|3@1+ (1,0) [0|0] "" Vector__XXX
 SG_ PCS2_a101_iticCurveSection m101 : 57|3@1+ (1,0) [0|0] "" Vector__XXX
 SG_ PCS2_a107_outletGridFormEnableRequest m107 : 57|1@1+ (1,0) [0|0] "" Vector__XXX
 SG_ PCS2_a121_lvSensorReadingTooHigh m121 : 57|1@1+ (1,0) [0|0] "" Vector__XXX
 SG_ PCS2_a146_ac_harness_l2_l3_shorted m146 : 57|1@1+ (1,0) [0|0] "" Vector__XXX
 SG_ PCS2_a107_cpGridFormEnableRequest m107 : 58|1@1+ (1,0) [0|0] "" Vector__XXX
 SG_ PCS2_a114_useLinearResult m114 : 58|1@1+ (1,0) [0|0] "" Vector__XXX
 SG_ PCS2_a153_charging_flag m153 : 58|1@1+ (1,0) [0|0] "" Vector__XXX
 SG_ PCS2_a168_reason m168 : 58|1@1+ (1,0) [0|0] "" Vector__XXX
 SG_ PCS2_a107_packEOLGridFormEnableRequest m107 : 59|1@1+ (1,0) [0|0] "" Vector__XXX
 SG_ PCS2_a114_useLogarithmResult m114 : 59|1@1+ (1,0) [0|0] "" Vector__XXX
 SG_ PCS2_a136_acVoltagePresent m136 : 59|1@1+ (1,0) [0|0] "" Vector__XXX
 SG_ PCS2_a137_acVoltagePresent m137 : 59|1@1+ (1,0) [0|0] "" Vector__XXX
 SG_ PCS2_a153_L3_negative_flag m153 : 59|1@1+ (1,0) [0|0] "" Vector__XXX
 SG_ PCS2_alertSource : 60|4@1+ (1,0) [0|0] "" Vector__XXX

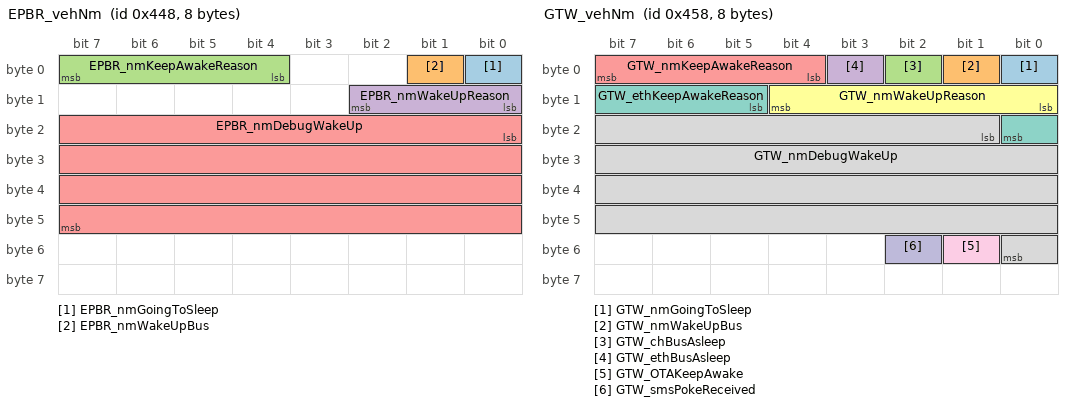
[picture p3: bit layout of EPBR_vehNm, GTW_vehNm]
BO_ 1096 EPBR_vehNm: 8 Vector__XXX
 SG_ EPBR_nmGoingToSleep : 0|1@1+ (1,0) [0|0] "" Vector__XXX
 SG_ EPBR_nmWakeUpBus : 1|1@1+ (1,0) [0|0] "" Vector__XXX
 SG_ EPBR_nmKeepAwakeReason : 4|4@1+ (1,0) [0|0] "" Vector__XXX
 SG_ EPBR_nmWakeUpReason : 8|3@1+ (1,0) [0|0] "" Vector__XXX
 SG_ EPBR_nmDebugWakeUp : 16|32@1+ (1,0) [0|0] "" Vector__XXX

BO_ 1106 BMS_voltageRegGain: 8 Vector__XXX
 SG_ BMS_driveGainKp : 0|10@1+ (8,0) [0|0] "" Vector__XXX
 SG_ BMS_driveGainKi : 10|11@1+ (1,0) [0|0] "" Vector__XXX

BO_ 1107 VEH_billing: 8 Vector__XXX
 SG_ VEH_pricebookId : 0|32@1+ (1,0) [0|0] "" Vector__XXX

BO_ 1112 GTW_vehNm: 8 Vector__XXX
 SG_ GTW_nmGoingToSleep : 0|1@1+ (1,0) [0|0] "" Vector__XXX
 SG_ GTW_nmWakeUpBus : 1|1@1+ (1,0) [0|0] "" Vector__XXX
 SG_ GTW_chBusAsleep : 2|1@1+ (1,0) [0|0] "" Vector__XXX
 SG_ GTW_ethBusAsleep : 3|1@1+ (1,0) [0|0] "" Vector__XXX
 SG_ GTW_nmKeepAwakeReason : 4|4@1+ (1,0) [0|0] "" Vector__XXX
 SG_ GTW_nmWakeUpReason : 8|5@1+ (1,0) [0|0] "" Vector__XXX
 SG_ GTW_ethKeepAwakeReason : 13|4@1+ (1,0) [0|0] "" Vector__XXX
 SG_ GTW_nmDebugWakeUp : 17|32@1+ (1,0) [0|0] "" Vector__XXX
 SG_ GTW_OTAKeepAwake : 49|1@1+ (1,0) [0|0] "" Vector__XXX
 SG_ GTW_smsPokeReceived : 50|1@1+ (1,0) [0|0] "" Vector__XXX

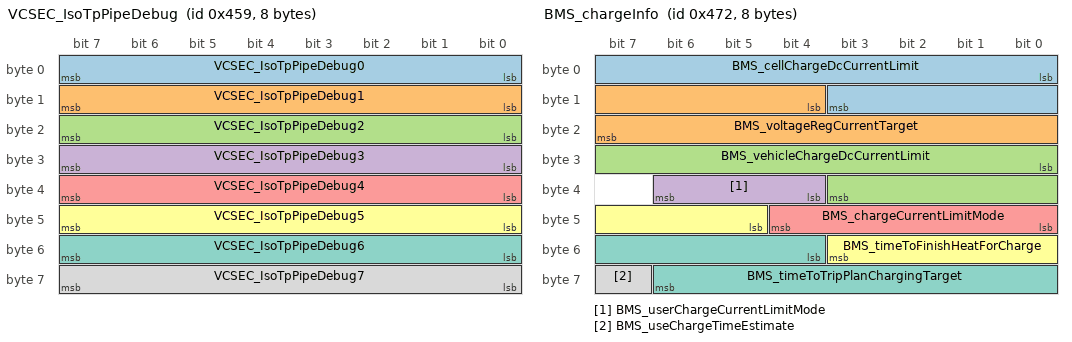
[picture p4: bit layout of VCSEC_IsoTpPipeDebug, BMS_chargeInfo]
BO_ 1113 VCSEC_IsoTpPipeDebug: 8 Vector__XXX
 SG_ VCSEC_IsoTpPipeDebug0 : 0|8@1+ (1,0) [0|0] "" Vector__XXX
 SG_ VCSEC_IsoTpPipeDebug1 : 8|8@1+ (1,0) [0|0] "" Vector__XXX
 SG_ VCSEC_IsoTpPipeDebug2 : 16|8@1+ (1,0) [0|0] "" Vector__XXX
 SG_ VCSEC_IsoTpPipeDebug3 : 24|8@1+ (1,0) [0|0] "" Vector__XXX
 SG_ VCSEC_IsoTpPipeDebug4 : 32|8@1+ (1,0) [0|0] "" Vector__XXX
 SG_ VCSEC_IsoTpPipeDebug5 : 40|8@1+ (1,0) [0|0] "" Vector__XXX
 SG_ VCSEC_IsoTpPipeDebug6 : 48|8@1+ (1,0) [0|0] "" Vector__XXX
 SG_ VCSEC_IsoTpPipeDebug7 : 56|8@1+ (1,0) [0|0] "" Vector__XXX

BO_ 1114 VCRIGHT_AP_hvacState10Hz: 8 Vector__XXX
 SG_ VCRIGHT_AP_hvacState10HzIndex M : 0|2@1+ (1,0) [0|0] "" Vector__XXX
 SG_ VCRIGHT_AP_autoDefogAvailable m0 : 2|1@1+ (1,0) [0|0] "" Vector__XXX
 SG_ VCRIGHT_AP_cameraTurnOnTime m1 : 2|9@1+ (5,0) [0|0] "" Vector__XXX
 SG_ VCRIGHT_AP_hvacFlashFoggingDetected m0 : 3|1@1+ (1,0) [0|0] "" Vector__XXX
 SG_ VCRIGHT_AP_hvacModelInitStatus m0 : 4|3@1+ (1,0) [0|0] "" Vector__XXX
 SG_ VCRIGHT_AP_cabinTempWindshield m0 : 7|8@1+ (0.5,-40) [0|0] "" Vector__XXX
 SG_ VCRIGHT_AP_cameraDefogType m1 : 11|2@1+ (1,0) [0|0] "" Vector__XXX
 SG_ VCRIGHT_ah_hvacFaultSurvivabilityTime m1 : 14|5@1+ (10,0) [0|0] "" Vector__XXX
 SG_ VCRIGHT_AP_cabinTempSideGlassRight m0 : 15|8@1+ (0.5,-40) [0|0] "" Vector__XXX
 SG_ VCRIGHT_ah_defoggingTimeNeeded m1 : 19|5@1+ (1,0) [0|0] "" Vector__XXX
 SG_ VCRIGHT_AP_cabinTempSideGlassLeft m0 : 23|8@1+ (0.5,-40) [0|0] "" Vector__XXX
 SG_ VCRIGHT_AP_cameraFanDutyRequest m1 : 24|7@1+ (1,0) [0|0] "" Vector__XXX
 SG_ VCRIGHT_AP_hvacRecircDoorPercent m0 : 31|6@1+ (1.6,0) [0|0] "" Vector__XXX
 SG_ VCRIGHT_ah_defogSystemState m1 : 31|3@1+ (1,0) [0|0] "" Vector__XXX
 SG_ VCRIGHT_AP_turnForwardCameraHeaterOnReason m1 : 34|3@1+ (1,0) [0|0] "" Vector__XXX
 SG_ VCRIGHT_AP_hvacAirDistributionMode m0 : 37|3@1+ (1,0) [0|0] "" Vector__XXX
 SG_ VCRIGHT_AP_turnCameraFanOffReason m1 : 38|3@1+ (1,0) [0|0] "" Vector__XXX
 SG_ VCRIGHT_AP_hvacEstimateWindshieldRH m0 : 40|8@1+ (1,0) [0|0] "" Vector__XXX
 SG_ VCRIGHT_AP_hvacMassflowTarget m0 : 48|8@1+ (1,0) [0|0] "" Vector__XXX
 SG_ VCRIGHT_AP_solarFluxOnRightWindow m1 : 48|8@1+ (5,0) [0|0] "" Vector__XXX
 SG_ VCRIGHT_AP_solarFluxOnLeftWindow m1 : 56|8@1+ (5,0) [0|0] "" Vector__XXX
 SG_ VCRIGHT_AP_tempDuctDefrost m0 : 56|8@1+ (0.5,-22) [0|0] "" Vector__XXX

BO_ 1115 VCRIGHT_AP_hvacState0Point1Hz: 8 Vector__XXX
 SG_ VCRIGHT_AP_hvacState0Point1HzIndex M : 0|1@1+ (1,0) [0|0] "" Vector__XXX
 SG_ VCRIGHT_AP_VOCPurgeRunCount m0 : 2|10@1+ (1,0) [0|0] "" Vector__XXX

BO_ 1116 CC_alertLog: 8 Vector__XXX
 SG_ CC_alertID M : 0|15@1+ (1,0) [0|0] "" Vector__XXX
 SG_ CC_alertType : 15|1@1+ (1,0) [0|0] "" Vector__XXX
 SG_ CC_a001_groundResistance m1 : 16|12@1+ (1000,0) [0|0] "" Vector__XXX
 SG_ CC_a003_gfciRmsCurrent m3 : 16|12@1+ (0.001,0) [0|0] "" Vector__XXX
 SG_ CC_a004_gfciErrorReason m4 : 16|8@1+ (1,0) [0|0] "" Vector__XXX
 SG_ CC_a006_line1Current m6 : 16|16@1+ (0.01,0) [0|0] "" Vector__XXX
 SG_ CC_a007_inputVoltage m7 : 16|16@1+ (0.01,0) [0|0] "" Vector__XXX
 SG_ CC_a008_inputVoltage m8 : 16|16@1+ (0.01,0) [0|0] "" Vector__XXX
 SG_ CC_a010_line1Voltage m10 : 16|12@1+ (0.1,0) [0|0] "" Vector__XXX
 SG_ CC_a011_pcbaTemp m11 : 16|9@1- (1,88) [0|0] "" Vector__XXX
 SG_ CC_a012_inputThermopile m12 : 16|12@1+ (1e-06,0) [0|0] "" Vector__XXX
 SG_ CC_a013_handleTemp m13 : 16|9@1- (1,88) [0|0] "" Vector__XXX
 SG_ CC_a014_failureCause m14 : 16|9@1+ (1,0) [0|0] "" Vector__XXX
 SG_ CC_a015_pilotHighVolage m15 : 16|16@1+ (0.001,0) [0|0] "" Vector__XXX
 SG_ CC_a027_handleTemperature m27 : 16|12@1- (0.1,0) [0|0] "" Vector__XXX
 SG_ CC_a032_meteringSpiCommsFailure m32 : 16|1@1+ (1,0) [0|0] "" Vector__XXX
 SG_ CC_a033_nominalVoltage m33 : 16|9@1+ (0.01,0) [0|0] "" Vector__XXX
 SG_ CC_a034_resetCause m34 : 16|4@1+ (1,0) [0|0] "" Vector__XXX
 SG_ CC_a035_gfciCalibrationOffset m35 : 16|16@1- (1,0) [0|0] "" Vector__XXX
 SG_ CC_a036_line1Voltage m36 : 16|12@1+ (0.1,0) [0|0] "" Vector__XXX
 SG_ CC_a037_expiredWatchdogModuleId m37 : 16|8@1+ (1,0) [0|0] "" Vector__XXX
 SG_ CC_a038_moduleMiaModuleId m38 : 16|8@1+ (1,0) [0|0] "" Vector__XXX
 SG_ CC_a039_intModuleTemperature m39 : 16|9@1- (1,88) [0|0] "" Vector__XXX
 SG_ CC_a040_handleTemperature m40 : 16|9@1- (1,88) [0|0] "" Vector__XXX
 SG_ CC_a041_inputThermopile m41 : 16|16@1- (1e-06,0) [0|0] "" Vector__XXX
 SG_ CC_a042_pcbaTemperature m42 : 16|9@1- (1,88) [0|0] "" Vector__XXX
 SG_ CC_a044_relayCoilVoltage m44 : 16|8@1+ (0.14,0) [0|0] "" Vector__XXX
 SG_ CC_a047_actuatorCurrPosDeg m47 : 16|12@1+ (0.1,0) [0|0] "" Vector__XXX
 SG_ CC_a048_adapterFaultReason m48 : 16|4@1+ (1,0) [0|0] "" Vector__XXX
 SG_ CC_a049_rs485FailReason m49 : 16|4@1+ (1,0) [0|0] "" Vector__XXX
 SG_ CC_a050_eFuseFaultReason m50 : 16|4@1+ (1,0) [0|0] "" Vector__XXX
 SG_ CC_a051_chcCriticalFaultReason m51 : 16|6@1+ (1,0) [0|0] "" Vector__XXX
 SG_ CC_a052_nominalVoltage m52 : 16|9@1+ (0.01,0) [0|0] "" Vector__XXX
 SG_ CC_a057_chcVitalsRequestFailureReason m57 : 16|4@1+ (1,0) [0|0] "" Vector__XXX
 SG_ CC_a060_persistenceFaultReason m60 : 16|4@1+ (1,0) [0|0] "" Vector__XXX
 SG_ CC_a032_meteringConfigMismatch m32 : 17|1@1+ (1,0) [0|0] "" Vector__XXX
 SG_ CC_a004_gfciAsicErrorBitfield m4 : 24|8@1+ (1,0) [0|0] "" Vector__XXX
 SG_ CC_a037_expiredWatchdogTaskId m37 : 24|8@1+ (1,0) [0|0] "" Vector__XXX
 SG_ CC_a038_moduleMiaTaskId m38 : 24|8@1+ (1,0) [0|0] "" Vector__XXX
 SG_ CC_a044_pcbaTemperature m44 : 24|9@1- (1,88) [0|0] "" Vector__XXX
 SG_ CC_a049_rs485DriverFault m49 : 24|32@1- (1,0) [0|0] "" Vector__XXX
 SG_ CC_a051_chcCriticalFaultUpdateAttempt m51 : 24|32@1+ (1,0) [0|0] "" Vector__XXX
 SG_ CC_a057_chcVitalsRequestExpectedCrc m57 : 24|32@1+ (1,0) [0|0] "" Vector__XXX
 SG_ CC_a014_meterFaultAddress m14 : 25|16@1+ (1,0) [0|0] "" Vector__XXX
 SG_ CC_a033_measuredVoltage m33 : 25|9@1+ (0.01,0) [0|0] "" Vector__XXX
 SG_ CC_a052_measuredVoltage m52 : 25|9@1+ (0.01,0) [0|0] "" Vector__XXX
 SG_ CC_a003_gfciRmsCurrentAvg m3 : 28|12@1+ (0.001,0) [0|0] "" Vector__XXX
 SG_ CC_a010_line2Voltage m10 : 28|12@1+ (0.1,0) [0|0] "" Vector__XXX
 SG_ CC_a012_inputThermopileDvdt m12 : 28|12@1+ (1e-06,0) [0|0] "" Vector__XXX
 SG_ CC_a027_handleTempFaultReason m27 : 28|4@1+ (1,0) [0|0] "" Vector__XXX
 SG_ CC_a036_line2Voltage m36 : 28|12@1+ (0.1,0) [0|0] "" Vector__XXX
 SG_ CC_a047_actuatorTargetPos m47 : 28|2@1+ (1,0) [0|0] "" Vector__XXX
 SG_ CC_a047_motorFaultReason m47 : 30|2@1+ (1,0) [0|0] "" Vector__XXX
 SG_ CC_a004_gfciSelfTestDuty m4 : 32|16@1- (0.0001,50) [0|0] "" Vector__XXX
 SG_ CC_a006_line2Current m6 : 32|16@1+ (0.01,0) [0|0] "" Vector__XXX
 SG_ CC_a007_inputLineVoltage m7 : 32|16@1+ (0.01,0) [0|0] "" Vector__XXX
 SG_ CC_a008_inputLineVoltage m8 : 32|16@1+ (0.01,0) [0|0] "" Vector__XXX
 SG_ CC_a015_smState m15 : 32|8@1+ (1,0) [0|0] "" Vector__XXX
 SG_ CC_a035_gfciFactoryOffset m35 : 32|16@1- (1,0) [0|0] "" Vector__XXX
 SG_ CC_a037_expiredWatchdogAppCRC m37 : 32|32@1+ (1,0) [0|0] "" Vector__XXX
 SG_ CC_a038_moduleMiaAppCRC m38 : 32|32@1+ (1,0) [0|0] "" Vector__XXX
 SG_ CC_a041_inputThermopileDvdt m41 : 32|16@1- (1e-06,0) [0|0] "" Vector__XXX
 SG_ CC_a003_dcGfciCurrent m3 : 40|10@1- (0.001,0) [0|0] "" Vector__XXX
 SG_ CC_a010_line3Voltage m10 : 40|12@1+ (0.1,0) [0|0] "" Vector__XXX
 SG_ CC_a036_line3Voltage m36 : 40|12@1+ (0.1,0) [0|0] "" Vector__XXX
 SG_ CC_a014_meterFaultData m14 : 41|16@1+ (1,0) [0|0] "" Vector__XXX
 SG_ CC_a004_gfciSelfTestCurrent m4 : 48|16@1- (0.0001,0) [0|0] "" Vector__XXX
 SG_ CC_a006_line3Current m6 : 48|16@1+ (0.01,0) [0|0] "" Vector__XXX
 SG_ CC_a007_inputNeutralVoltage m7 : 48|16@1+ (0.01,0) [0|0] "" Vector__XXX
 SG_ CC_a008_inputNeutralVoltage m8 : 48|16@1+ (0.01,0) [0|0] "" Vector__XXX
 SG_ CC_a035_gfciFactoryScaling m35 : 48|16@1+ (1,0) [0|0] "" Vector__XXX
 SG_ CC_a003_gfciFaultReason m3 : 50|4@1+ (1,0) [0|0] "" Vector__XXX
 SG_ CC_a010_line1StuckClosed m10 : 52|1@1+ (1,0) [0|0] "" Vector__XXX
 SG_ CC_a036_line1StuckOpen m36 : 52|1@1+ (1,0) [0|0] "" Vector__XXX
 SG_ CC_a010_line2StuckClosed m10 : 53|1@1+ (1,0) [0|0] "" Vector__XXX
 SG_ CC_a036_line2StuckOpen m36 : 53|1@1+ (1,0) [0|0] "" Vector__XXX
 SG_ CC_a010_line3StuckClosed m10 : 54|1@1+ (1,0) [0|0] "" Vector__XXX
 SG_ CC_a036_line3StuckOpen m36 : 54|1@1+ (1,0) [0|0] "" Vector__XXX
 SG_ CC_a003_gfciFaultBucket m3 : 56|4@1+ (1,0) [0|0] "" Vector__XXX
 SG_ CC_a014_meterRetryCount m14 : 57|4@1+ (1,0) [0|0] "" Vector__XXX

BO_ 1117 FC_evseBilling: 8 Vector__XXX
 SG_ FC_evseBillingDataSelect M : 0|1@1+ (1,0) [0|0] "" Vector__XXX
 SG_ FC_evseBillingEnergy m0 : 4|20@1+ (0.001,0) [0|0] "" Vector__XXX
 SG_ FC_evseMeterFwGitHash m1 : 4|56@1+ (1,0) [0|0] "" Vector__XXX
 SG_ FC_evseMeterPower m0 : 24|20@1+ (0.001,0) [0|0] "" Vector__XXX
 SG_ FC_evseMeterCurrent m0 : 44|10@1+ (1,0) [0|0] "" Vector__XXX
 SG_ FC_evseMeterVoltage m0 : 54|10@1+ (1,0) [0|0] "" Vector__XXX

BO_ 1118 VCFRONT1_LVSelfTests: 8 Vector__XXX
 SG_ VCFRONT1_LVSelfTestsChecksum : 0|8@1+ (1,0) [0|0] "" Vector__XXX
 SG_ VCFRONT1_LVSelfTestsCounter : 8|4@1+ (1,0) [0|0] "" Vector__XXX
 SG_ VCFRONT1_LVSelfTestsIndex M : 12|1@1+ (1,0) [0|0] "" Vector__XXX
 SG_ VCFRONT1_pcsDomainOvervoltageSelfTestResult m0 : 13|2@1+ (1,0) [0|0] "" Vector__XXX
 SG_ VCFRONT1_pcsDomainOvervoltageSelfTestState m0 : 16|3@1+ (1,0) [0|0] "" Vector__XXX
 SG_ VCFRONT1_pcsDomainUndervoltageSelfTestResult m0 : 19|2@1+ (1,0) [0|0] "" Vector__XXX
 SG_ VCFRONT1_pcsDomainUndervoltageSelfTestState m0 : 21|3@1+ (1,0) [0|0] "" Vector__XXX
 SG_ VCFRONT1_vcfrontBridgeEFuseASICSelfTestResult m0 : 24|2@1+ (1,0) [0|0] "" Vector__XXX
 SG_ VCFRONT1_vcfrontBridgeEFuseASICSelfTestState m0 : 26|3@1+ (1,0) [0|0] "" Vector__XXX
 SG_ VCFRONT1_pcsOvShutdownSelfTestResult m0 : 29|2@1+ (1,0) [0|0] "" Vector__XXX
 SG_ VCFRONT1_pcsOvShutdownSelfTestState m0 : 32|3@1+ (1,0) [0|0] "" Vector__XXX
 SG_ VCFRONT1_pcsOvShutdownOkToContinueSelfTests m0 : 35|1@1+ (1,0) [0|0] "" Vector__XXX
 SG_ VCFRONT1_uvProtectionState m0 : 36|4@1+ (1,0) [0|0] "" Vector__XXX

BO_ 1119 VCBATT1_LVSelfTests: 8 Vector__XXX
 SG_ VCBATT1_LVSelfTestsChecksum : 0|8@1+ (1,0) [0|0] "" Vector__XXX
 SG_ VCBATT1_LVSelfTestsCounter : 8|4@1+ (1,0) [0|0] "" Vector__XXX
 SG_ VCBATT1_LVSelfTestsIndex M : 12|1@1+ (1,0) [0|0] "" Vector__XXX
 SG_ VCBATT1_lvProtectionSelfTestsEnabled m1 : 13|1@1+ (1,0) [0|0] "" Vector__XXX
 SG_ VCBATT1_startBattDomainOvercurrentSelfTest m1 : 14|1@1+ (1,0) [0|0] "" Vector__XXX
 SG_ VCBATT1_startBattDomainOvervoltageSelfTest m1 : 15|1@1+ (1,0) [0|0] "" Vector__XXX
 SG_ VCBATT1_selfTestOrchestratorState m0 : 16|4@1+ (1,0) [0|0] "" Vector__XXX
 SG_ VCBATT1_startBattDomainUndervoltageSelfTest m1 : 16|1@1+ (1,0) [0|0] "" Vector__XXX
 SG_ VCBATT1_startDualPowerLoadsSelfTest m1 : 17|1@1+ (1,0) [0|0] "" Vector__XXX
 SG_ VCBATT1_startVCBattBridgeEFuseASICSelfTest m1 : 18|1@1+ (1,0) [0|0] "" Vector__XXX
 SG_ VCBATT1_startBattDomainOvercurrentVCLeftSelfTest m1 : 19|1@1+ (1,0) [0|0] "" Vector__XXX
 SG_ VCBATT1_selfTestsLastCompletedState m0 : 20|4@1+ (1,0) [0|0] "" Vector__XXX
 SG_ VCBATT1_startPCSOVShutdownSelfTest m1 : 20|1@1+ (1,0) [0|0] "" Vector__XXX
 SG_ VCBATT1_startPCSDomainOvervoltageSelfTest m1 : 21|1@1+ (1,0) [0|0] "" Vector__XXX
 SG_ VCBATT1_startBattDomainUndervoltageVCLeftSelfTest m1 : 22|1@1+ (1,0) [0|0] "" Vector__XXX
 SG_ VCBATT1_startPCSDomainUndervoltageSelfTest m1 : 23|1@1+ (1,0) [0|0] "" Vector__XXX
 SG_ VCBATT1_selfTestsTimedOut m0 : 24|1@1+ (1,0) [0|0] "" Vector__XXX
 SG_ VCBATT1_startVCFrontBridgeEFuseASICSelfTest m1 : 24|1@1+ (1,0) [0|0] "" Vector__XXX
 SG_ VCBATT1_battDomainOvercurrentSelfTestResult m1 : 25|2@1+ (1,0) [0|0] "" Vector__XXX
 SG_ VCBATT1_selfTestRetriesUsed m0 : 25|4@1+ (1,0) [0|0] "" Vector__XXX
 SG_ VCBATT1_battDomainOvercurrentSelfTestState m1 : 27|3@1+ (1,0) [0|0] "" Vector__XXX
 SG_ VCBATT1_battDomainOvervoltageSelfTestResult m1 : 30|2@1+ (1,0) [0|0] "" Vector__XXX
 SG_ VCBATT1_battDomainOvervoltageSelfTestState m1 : 32|3@1+ (1,0) [0|0] "" Vector__XXX
 SG_ VCBATT1_selfTestRetriesRemaining m0 : 32|4@1+ (1,0) [0|0] "" Vector__XXX
 SG_ VCBATT1_battDomainUndervoltageSelfTestResult m1 : 35|2@1+ (1,0) [0|0] "" Vector__XXX
 SG_ VCBATT1_selfTestsInProgress m0 : 36|1@1+ (1,0) [0|0] "" Vector__XXX
 SG_ VCBATT1_battDomainUndervoltageSelfTestState m1 : 37|3@1+ (1,0) [0|0] "" Vector__XXX
 SG_ VCBATT1_selfTestsRunningOrRetryPending m0 : 37|1@1+ (1,0) [0|0] "" Vector__XXX
 SG_ VCBATT1_selfTestsRequireHwProtArmed m0 : 38|1@1+ (1,0) [0|0] "" Vector__XXX
 SG_ VCBATT1_selfTestsBlockDriveOnWake m0 : 39|1@1+ (1,0) [0|0] "" Vector__XXX
 SG_ VCBATT1_dualPowerLoadsSelfTestResult m1 : 40|2@1+ (1,0) [0|0] "" Vector__XXX
 SG_ VCBATT1_selfTestsHoursUntilExpiry m0 : 40|8@1+ (1,0) [0|0] "" Vector__XXX
 SG_ VCBATT1_dualPowerLoadsSelfTestState m1 : 42|3@1+ (1,0) [0|0] "" Vector__XXX
 SG_ VCBATT1_vcbattBridgeEFuseASICSelfTestResult m1 : 45|2@1+ (1,0) [0|0] "" Vector__XXX
 SG_ VCBATT1_selfTestsKeepAwakeRequested m0 : 48|1@1+ (1,0) [0|0] "" Vector__XXX
 SG_ VCBATT1_vcbattBridgeEFuseASICSelfTestState m1 : 48|3@1+ (1,0) [0|0] "" Vector__XXX
 SG_ VCBATT1_selfTestsExpectVnfFaults m0 : 49|1@1+ (1,0) [0|0] "" Vector__XXX
 SG_ VCBATT1_uvProtectionState m1 : 51|4@1+ (1,0) [0|0] "" Vector__XXX

BO_ 1121 VC_TLVBMS_debug: 8 Vector__XXX
 SG_ VC_TLVBMS_debugMultiplexer M : 0|8@1+ (1,0) [0|0] "" Vector__XXX
 SG_ VC_TLVBMS_brickImpedanceAvg m5 : 8|14@1+ (2.5e-05,0) [0|0] "" Vector__XXX
 SG_ VC_TLVBMS_cacMin m1 : 8|12@1+ (0.005,0) [0|0] "" Vector__XXX
 SG_ VC_TLVBMS_dischargeVoltageLimit m4 : 8|12@1+ (0.015,0) [0|0] "" Vector__XXX
 SG_ VC_TLVBMS_impTestRGrowthMin m9 : 8|8@1+ (0.01,0.5) [0|0] "" Vector__XXX
 SG_ VC_TLVBMS_lowCurrentInterruptionCurrent m10 : 8|12@1- (0.001,0) [0|0] "" Vector__XXX
 SG_ VC_TLVBMS_maxDischargePower m6 : 8|12@1+ (2,-8000) [0|0] "" Vector__XXX
 SG_ VC_TLVBMS_packBirthEpochBinned m8 : 8|13@1+ (864000,0) [0|0] "" Vector__XXX
 SG_ VC_TLVBMS_socByOcvMinBrick1 m0 : 8|10@1+ (0.1,0) [0|0] "" Vector__XXX
 SG_ VC_TLVBMS_sohTestCompletionEpochTime m7 : 8|32@1+ (1,0) [0|0] "" Vector__XXX
 SG_ VC_TLVBMS_sohTestStateInternal m3 : 8|5@1+ (1,0) [0|0] "" Vector__XXX
 SG_ VC_TLVBMS_tempSense1 m2 : 8|11@1+ (0.1,-50) [0|0] "" Vector__XXX
 SG_ VC_TLVBMS_impTestRGrowthMax m9 : 16|8@1+ (0.01,0.5) [0|0] "" Vector__XXX
 SG_ VC_TLVBMS_sohTestEndMode m3 : 16|4@1+ (1,0) [0|0] "" Vector__XXX
 SG_ VC_TLVBMS_socByOcvMaxBrick1 m0 : 18|10@1+ (0.1,0) [0|0] "" Vector__XXX
 SG_ VC_TLVBMS_tempSense2 m2 : 19|11@1+ (0.1,-50) [0|0] "" Vector__XXX
 SG_ VC_TLVBMS_cacMax m1 : 20|12@1+ (0.005,0) [0|0] "" Vector__XXX
 SG_ VC_TLVBMS_lowCurrentInterruptionReason m10 : 20|2@1+ (1,0) [0|0] "" Vector__XXX
 SG_ VC_TLVBMS_maxRegenPower m6 : 20|12@1+ (2,0) [0|0] "" Vector__XXX
 SG_ VC_TLVBMS_socByOcvEstMax m4 : 20|10@1+ (0.1,0) [0|0] "" Vector__XXX
 SG_ VC_TLVBMS_sohTestInitialSoc m3 : 20|7@1+ (0.1,90) [0|0] "" Vector__XXX
 SG_ VC_TLVBMS_calendarAgingCapacityLoss m8 : 21|9@1+ (0.1,0) [0|0] "" Vector__XXX
 SG_ VC_TLVBMS_bleedFetTestNeeded m10 : 22|1@1+ (1,0) [0|0] "" Vector__XXX
 SG_ VC_TLVBMS_bleedFetTestAllowed m10 : 23|1@1+ (1,0) [0|0] "" Vector__XXX
 SG_ VC_TLVBMS_brickImpedanceMin m5 : 24|14@1+ (2.5e-05,0) [0|0] "" Vector__XXX
 SG_ VC_TLVBMS_impTestRGrowthFiltMax m9 : 24|8@1+ (0.01,0.5) [0|0] "" Vector__XXX
 SG_ VC_TLVBMS_sohTestEndingSoc m3 : 27|10@1+ (0.1,0) [0|0] "" Vector__XXX
 SG_ VC_TLVBMS_socByOcvMaxError m0 : 28|10@1+ (0.1,0) [0|0] "" Vector__XXX
 SG_ VC_TLVBMS_socByOcvEstMin m4 : 30|10@1+ (0.1,0) [0|0] "" Vector__XXX
 SG_ VC_TLVBMS_tempSenseEfuse m2 : 30|11@1+ (0.1,-50) [0|0] "" Vector__XXX
 SG_ VC_TLVBMS_cacMinBrickId m1 : 32|5@1+ (1,1) [0|0] "" Vector__XXX
 SG_ VC_TLVBMS_calendarAgingDcrGrowth m8 : 32|14@1- (0.1,200) [0|0] "" Vector__XXX
 SG_ VC_TLVBMS_impTestDeltaI m9 : 32|12@1- (0.25,0) [0|0] "" Vector__XXX
 SG_ VC_TLVBMS_maxDischargeLoadedBrickV m6 : 32|10@1+ (0.005,0) [0|0] "" Vector__XXX
 SG_ VC_TLVBMS_sohTestUsableCapacity m3 : 37|7@1+ (0.2,-0.2) [0|0] "" Vector__XXX
 SG_ VC_TLVBMS_socRestingCurrentThreshold m0 : 38|10@1+ (0.002,0) [0|0] "" Vector__XXX
 SG_ VC_TLVBMS_boundedNegativeSocErrorMax m4 : 40|10@1+ (0.1,0) [0|0] "" Vector__XXX
 SG_ VC_TLVBMS_brickImpedanceMax m5 : 40|14@1+ (2.5e-05,0) [0|0] "" Vector__XXX
 SG_ VC_TLVBMS_brickImpedanceNormFiltMax m7 : 40|8@1+ (0.01,0.5) [0|0] "" Vector__XXX
 SG_ VC_TLVBMS_cacMaxBrickId m1 : 40|5@1+ (1,1) [0|0] "" Vector__XXX
 SG_ VC_TLVBMS_tempSenseBusbar m2 : 41|11@1+ (0.1,-50) [0|0] "" Vector__XXX
 SG_ VC_TLVBMS_minDischargeLoadedBrickV m6 : 42|10@1+ (0.005,0) [0|0] "" Vector__XXX
 SG_ VC_TLVBMS_sohTestUsableEnergy m3 : 44|10@1+ (0.2,-0.2) [0|0] "" Vector__XXX
 SG_ VC_TLVBMS_capacityImbalancePct m8 : 46|10@1+ (0.1,0) [0|0] "" Vector__XXX
 SG_ VC_TLVBMS_brickImpedanceNormFiltMaxId m7 : 48|5@1+ (1,1) [0|0] "" Vector__XXX
 SG_ VC_TLVBMS_efuseFeedbackVSense m1 : 48|12@1+ (0.02,0) [0|0] "" Vector__XXX
 SG_ VC_TLVBMS_heaterCurrent m0 : 48|7@1+ (0.04,0) [0|0] "" Vector__XXX
 SG_ VC_TLVBMS_impTestRGrowthMinId m9 : 48|5@1+ (1,1) [0|0] "" Vector__XXX
 SG_ VC_TLVBMS_brickImpedanceDeltaI m4 : 50|12@1- (0.25,0) [0|0] "" Vector__XXX
 SG_ VC_TLVBMS_bmb6VSense m2 : 52|12@1+ (0.002,0) [0|0] "" Vector__XXX
 SG_ VC_TLVBMS_usableEnergyAvailable m6 : 52|12@1+ (1,0) [0|0] "" Vector__XXX
 SG_ VC_TLVBMS_impTestRGrowthMaxId m9 : 53|5@1+ (1,1) [0|0] "" Vector__XXX
 SG_ VC_TLVBMS_brickImpedanceMinId m5 : 54|5@1+ (1,1) [0|0] "" Vector__XXX
 SG_ VC_TLVBMS_sohTestDuration m3 : 54|10@1+ (0.1,-0.1) [0|0] "" Vector__XXX
 SG_ VC_TLVBMS_heaterOn m0 : 55|1@1+ (1,0) [0|0] "" Vector__XXX
 SG_ VC_TLVBMS_allBricksRestingForSoc m0 : 56|1@1+ (1,0) [0|0] "" Vector__XXX
 SG_ VC_TLVBMS_capacityImbalanceSource m8 : 56|3@1+ (1,0) [0|0] "" Vector__XXX
 SG_ VC_TLVBMS_sohTestLabel m7 : 56|4@1+ (1,0) [0|0] "" Vector__XXX
 SG_ VC_TLVBMS_allBricksRestingForCac m0 : 57|1@1+ (1,0) [0|0] "" Vector__XXX
 SG_ VC_TLVBMS_chargingIsActiveFine m0 : 58|1@1+ (1,0) [0|0] "" Vector__XXX
 SG_ VC_TLVBMS_impTestRGrowthFiltMaxId m9 : 58|5@1+ (1,1) [0|0] "" Vector__XXX
 SG_ VC_TLVBMS_brickImpedanceMaxId m5 : 59|5@1+ (1,1) [0|0] "" Vector__XXX
 SG_ VC_TLVBMS_chargingIsActiveCoarse m0 : 59|1@1+ (1,0) [0|0] "" Vector__XXX
 SG_ VC_TLVBMS_socByDeltaVEnabled m0 : 60|1@1+ (1,0) [0|0] "" Vector__XXX
 SG_ VC_TLVBMS_hwCellProtectionsTripped m0 : 61|1@1+ (1,0) [0|0] "" Vector__XXX
 SG_ VC_TLVBMS_hwOverCurrentSet m0 : 62|1@1+ (1,0) [0|0] "" Vector__XXX
 SG_ VC_TLVBMS_socByTopOfChargeEnabled m0 : 63|1@1+ (1,0) [0|0] "" Vector__XXX

BO_ 1122 VCBATT1_TLVBMS_debug: 8 Vector__XXX
 SG_ VCBATT1_TLVBMS_debugMultiplexer M : 0|8@1+ (1,0) [0|0] "" Vector__XXX
 SG_ VCBATT1_TLVBMS_brickImpedanceAvg m5 : 8|14@1+ (2.5e-05,0) [0|0] "" Vector__XXX
 SG_ VCBATT1_TLVBMS_cacMin m1 : 8|12@1+ (0.005,0) [0|0] "" Vector__XXX
 SG_ VCBATT1_TLVBMS_dischargeVoltageLimit m4 : 8|12@1+ (0.015,0) [0|0] "" Vector__XXX
 SG_ VCBATT1_TLVBMS_impTestRGrowthMin m9 : 8|8@1+ (0.01,0.5) [0|0] "" Vector__XXX
 SG_ VCBATT1_TLVBMS_lowCurrentInterruptionCurrent m10 : 8|12@1- (0.001,0) [0|0] "" Vector__XXX
 SG_ VCBATT1_TLVBMS_maxDischargePower m6 : 8|12@1+ (2,-8000) [0|0] "" Vector__XXX
 SG_ VCBATT1_TLVBMS_packBirthEpochBinned m8 : 8|13@1+ (864000,0) [0|0] "" Vector__XXX
 SG_ VCBATT1_TLVBMS_socByOcvMinBrick1 m0 : 8|10@1+ (0.1,0) [0|0] "" Vector__XXX
 SG_ VCBATT1_TLVBMS_sohTestCompletionEpochTime m7 : 8|32@1+ (1,0) [0|0] "" Vector__XXX
 SG_ VCBATT1_TLVBMS_sohTestStateInternal m3 : 8|5@1+ (1,0) [0|0] "" Vector__XXX
 SG_ VCBATT1_TLVBMS_tempSense1 m2 : 8|11@1+ (0.1,-50) [0|0] "" Vector__XXX
 SG_ VCBATT1_TLVBMS_impTestRGrowthMax m9 : 16|8@1+ (0.01,0.5) [0|0] "" Vector__XXX
 SG_ VCBATT1_TLVBMS_sohTestEndMode m3 : 16|4@1+ (1,0) [0|0] "" Vector__XXX
 SG_ VCBATT1_TLVBMS_socByOcvMaxBrick1 m0 : 18|10@1+ (0.1,0) [0|0] "" Vector__XXX
 SG_ VCBATT1_TLVBMS_tempSense2 m2 : 19|11@1+ (0.1,-50) [0|0] "" Vector__XXX
 SG_ VCBATT1_TLVBMS_cacMax m1 : 20|12@1+ (0.005,0) [0|0] "" Vector__XXX
 SG_ VCBATT1_TLVBMS_lowCurrentInterruptionReason m10 : 20|2@1+ (1,0) [0|0] "" Vector__XXX
 SG_ VCBATT1_TLVBMS_maxRegenPower m6 : 20|12@1+ (2,0) [0|0] "" Vector__XXX
 SG_ VCBATT1_TLVBMS_socByOcvEstMax m4 : 20|10@1+ (0.1,0) [0|0] "" Vector__XXX
 SG_ VCBATT1_TLVBMS_sohTestInitialSoc m3 : 20|7@1+ (0.1,90) [0|0] "" Vector__XXX
 SG_ VCBATT1_TLVBMS_calendarAgingCapacityLoss m8 : 21|9@1+ (0.1,0) [0|0] "" Vector__XXX
 SG_ VCBATT1_TLVBMS_bleedFetTestNeeded m10 : 22|1@1+ (1,0) [0|0] "" Vector__XXX
 SG_ VCBATT1_TLVBMS_bleedFetTestAllowed m10 : 23|1@1+ (1,0) [0|0] "" Vector__XXX
 SG_ VCBATT1_TLVBMS_brickImpedanceMin m5 : 24|14@1+ (2.5e-05,0) [0|0] "" Vector__XXX
 SG_ VCBATT1_TLVBMS_impTestRGrowthFiltMax m9 : 24|8@1+ (0.01,0.5) [0|0] "" Vector__XXX
 SG_ VCBATT1_TLVBMS_sohTestEndingSoc m3 : 27|10@1+ (0.1,0) [0|0] "" Vector__XXX
 SG_ VCBATT1_TLVBMS_socByOcvMaxError m0 : 28|10@1+ (0.1,0) [0|0] "" Vector__XXX
 SG_ VCBATT1_TLVBMS_socByOcvEstMin m4 : 30|10@1+ (0.1,0) [0|0] "" Vector__XXX
 SG_ VCBATT1_TLVBMS_tempSenseEfuse m2 : 30|11@1+ (0.1,-50) [0|0] "" Vector__XXX
 SG_ VCBATT1_TLVBMS_cacMinBrickId m1 : 32|5@1+ (1,1) [0|0] "" Vector__XXX
 SG_ VCBATT1_TLVBMS_calendarAgingDcrGrowth m8 : 32|14@1- (0.1,200) [0|0] "" Vector__XXX
 SG_ VCBATT1_TLVBMS_impTestDeltaI m9 : 32|12@1- (0.25,0) [0|0] "" Vector__XXX
 SG_ VCBATT1_TLVBMS_maxDischargeLoadedBrickV m6 : 32|10@1+ (0.005,0) [0|0] "" Vector__XXX
 SG_ VCBATT1_TLVBMS_sohTestUsableCapacity m3 : 37|7@1+ (0.2,-0.2) [0|0] "" Vector__XXX
 SG_ VCBATT1_TLVBMS_socRestingCurrentThreshold m0 : 38|10@1+ (0.002,0) [0|0] "" Vector__XXX
 SG_ VCBATT1_TLVBMS_boundedNegativeSocErrorMax m4 : 40|10@1+ (0.1,0) [0|0] "" Vector__XXX
 SG_ VCBATT1_TLVBMS_brickImpedanceMax m5 : 40|14@1+ (2.5e-05,0) [0|0] "" Vector__XXX
 SG_ VCBATT1_TLVBMS_brickImpedanceNormFiltMax m7 : 40|8@1+ (0.01,0.5) [0|0] "" Vector__XXX
 SG_ VCBATT1_TLVBMS_cacMaxBrickId m1 : 40|5@1+ (1,1) [0|0] "" Vector__XXX
 SG_ VCBATT1_TLVBMS_tempSenseBusbar m2 : 41|11@1+ (0.1,-50) [0|0] "" Vector__XXX
 SG_ VCBATT1_TLVBMS_minDischargeLoadedBrickV m6 : 42|10@1+ (0.005,0) [0|0] "" Vector__XXX
 SG_ VCBATT1_TLVBMS_sohTestUsableEnergy m3 : 44|10@1+ (0.2,-0.2) [0|0] "" Vector__XXX
 SG_ VCBATT1_TLVBMS_capacityImbalancePct m8 : 46|10@1+ (0.1,0) [0|0] "" Vector__XXX
 SG_ VCBATT1_TLVBMS_brickImpedanceNormFiltMaxId m7 : 48|5@1+ (1,1) [0|0] "" Vector__XXX
 SG_ VCBATT1_TLVBMS_efuseFeedbackVSense m1 : 48|12@1+ (0.02,0) [0|0] "" Vector__XXX
 SG_ VCBATT1_TLVBMS_heaterCurrent m0 : 48|7@1+ (0.04,0) [0|0] "" Vector__XXX
 SG_ VCBATT1_TLVBMS_impTestRGrowthMinId m9 : 48|5@1+ (1,1) [0|0] "" Vector__XXX
 SG_ VCBATT1_TLVBMS_brickImpedanceDeltaI m4 : 50|12@1- (0.25,0) [0|0] "" Vector__XXX
 SG_ VCBATT1_TLVBMS_bmb6VSense m2 : 52|12@1+ (0.002,0) [0|0] "" Vector__XXX
 SG_ VCBATT1_TLVBMS_usableEnergyAvailable m6 : 52|12@1+ (1,0) [0|0] "" Vector__XXX
 SG_ VCBATT1_TLVBMS_impTestRGrowthMaxId m9 : 53|5@1+ (1,1) [0|0] "" Vector__XXX
 SG_ VCBATT1_TLVBMS_brickImpedanceMinId m5 : 54|5@1+ (1,1) [0|0] "" Vector__XXX
 SG_ VCBATT1_TLVBMS_sohTestDuration m3 : 54|10@1+ (0.1,-0.1) [0|0] "" Vector__XXX
 SG_ VCBATT1_TLVBMS_heaterOn m0 : 55|1@1+ (1,0) [0|0] "" Vector__XXX
 SG_ VCBATT1_TLVBMS_allBricksRestingForSoc m0 : 56|1@1+ (1,0) [0|0] "" Vector__XXX
 SG_ VCBATT1_TLVBMS_capacityImbalanceSource m8 : 56|3@1+ (1,0) [0|0] "" Vector__XXX
 SG_ VCBATT1_TLVBMS_sohTestLabel m7 : 56|4@1+ (1,0) [0|0] "" Vector__XXX
 SG_ VCBATT1_TLVBMS_allBricksRestingForCac m0 : 57|1@1+ (1,0) [0|0] "" Vector__XXX
 SG_ VCBATT1_TLVBMS_chargingIsActiveFine m0 : 58|1@1+ (1,0) [0|0] "" Vector__XXX
 SG_ VCBATT1_TLVBMS_impTestRGrowthFiltMaxId m9 : 58|5@1+ (1,1) [0|0] "" Vector__XXX
 SG_ VCBATT1_TLVBMS_brickImpedanceMaxId m5 : 59|5@1+ (1,1) [0|0] "" Vector__XXX
 SG_ VCBATT1_TLVBMS_chargingIsActiveCoarse m0 : 59|1@1+ (1,0) [0|0] "" Vector__XXX
 SG_ VCBATT1_TLVBMS_socByDeltaVEnabled m0 : 60|1@1+ (1,0) [0|0] "" Vector__XXX
 SG_ VCBATT1_TLVBMS_hwCellProtectionsTripped m0 : 61|1@1+ (1,0) [0|0] "" Vector__XXX
 SG_ VCBATT1_TLVBMS_hwOverCurrentSet m0 : 62|1@1+ (1,0) [0|0] "" Vector__XXX
 SG_ VCBATT1_TLVBMS_socByTopOfChargeEnabled m0 : 63|1@1+ (1,0) [0|0] "" Vector__XXX

BO_ 1132 CC_alertMatrix1: 8 Vector__XXX
 SG_ CC_a001_gndMonIntrptLineSide : 0|1@1+ (1,0) [0|0] "" Vector__XXX
 SG_ CC_a002_gndMonIntrptLoadSide : 1|1@1+ (1,0) [0|0] "" Vector__XXX
 SG_ CC_a003_CCIDTripped : 2|1@1+ (1,0) [0|0] "" Vector__XXX
 SG_ CC_a004_CCIDSelfTestFault : 3|1@1+ (1,0) [0|0] "" Vector__XXX
 SG_ CC_a005_groundedNeutral : 4|1@1+ (1,0) [0|0] "" Vector__XXX
 SG_ CC_a006_inputOverCurrent : 5|1@1+ (1,0) [0|0] "" Vector__XXX
 SG_ CC_a007_inputOverVoltage : 6|1@1+ (1,0) [0|0] "" Vector__XXX
 SG_ CC_a008_inputUnderVoltage : 7|1@1+ (1,0) [0|0] "" Vector__XXX
 SG_ CC_a009_inputMiswired : 8|1@1+ (1,0) [0|0] "" Vector__XXX
 SG_ CC_a010_contactorWelded : 9|1@1+ (1,0) [0|0] "" Vector__XXX
 SG_ CC_a011_ambientOT : 10|1@1+ (1,0) [0|0] "" Vector__XXX
 SG_ CC_a012_wallPlugOT : 11|1@1+ (1,0) [0|0] "" Vector__XXX
 SG_ CC_a013_vehConnOT : 12|1@1+ (1,0) [0|0] "" Vector__XXX
 SG_ CC_a014_mcuSelfTestFault : 13|1@1+ (1,0) [0|0] "" Vector__XXX
 SG_ CC_a015_PilotAFault : 14|1@1+ (1,0) [0|0] "" Vector__XXX
 SG_ CC_a016_PilotBFault : 15|1@1+ (1,0) [0|0] "" Vector__XXX
 SG_ CC_a017_PilotCFault : 16|1@1+ (1,0) [0|0] "" Vector__XXX
 SG_ CC_a018_PilotDFault : 17|1@1+ (1,0) [0|0] "" Vector__XXX
 SG_ CC_a019_proxDisconnected : 18|1@1+ (1,0) [0|0] "" Vector__XXX
 SG_ CC_a020_3vRailIncorrect : 19|1@1+ (1,0) [0|0] "" Vector__XXX
 SG_ CC_a021_CB_noMaster : 20|1@1+ (1,0) [0|0] "" Vector__XXX
 SG_ CC_a022_CB_tooManyMasters : 21|1@1+ (1,0) [0|0] "" Vector__XXX
 SG_ CC_a023_CB_tooManySlaves : 22|1@1+ (1,0) [0|0] "" Vector__XXX
 SG_ CC_a024_CB_masterISetTooLow : 23|1@1+ (1,0) [0|0] "" Vector__XXX
 SG_ CC_a025_evseTemp : 24|1@1+ (1,0) [0|0] "" Vector__XXX
 SG_ CC_a026_wallPlugTemp : 25|1@1+ (1,0) [0|0] "" Vector__XXX
 SG_ CC_a027_vehicleHandleTemp : 26|1@1+ (1,0) [0|0] "" Vector__XXX
 SG_ CC_a028_CB_rotarySelect : 27|1@1+ (1,0) [0|0] "" Vector__XXX
 SG_ CC_a029_PilotFFault : 28|1@1+ (1,0) [0|0] "" Vector__XXX
 SG_ CC_a030_masterSlaveMismatch : 29|1@1+ (1,0) [0|0] "" Vector__XXX
 SG_ CC_a031_pllLockLost : 30|1@1+ (1,0) [0|0] "" Vector__XXX
 SG_ CC_a032_meteringFailure : 31|1@1+ (1,0) [0|0] "" Vector__XXX
 SG_ CC_a033_vRefOutOfRange : 32|1@1+ (1,0) [0|0] "" Vector__XXX
 SG_ CC_a034_bootAlert : 33|1@1+ (1,0) [0|0] "" Vector__XXX
 SG_ CC_a035_CCIDCalibration : 34|1@1+ (1,0) [0|0] "" Vector__XXX
 SG_ CC_a036_contactorStuckOpen : 35|1@1+ (1,0) [0|0] "" Vector__XXX
 SG_ CC_a037_internalModuleWatchdogExpired : 36|1@1+ (1,0) [0|0] "" Vector__XXX
 SG_ CC_a038_internalModuleMia : 37|1@1+ (1,0) [0|0] "" Vector__XXX
 SG_ CC_a039_internalModuleOverTemp : 38|1@1+ (1,0) [0|0] "" Vector__XXX
 SG_ CC_a040_handleTempFoldback : 39|1@1+ (1,0) [0|0] "" Vector__XXX
 SG_ CC_a041_inputWiringFoldback : 40|1@1+ (1,0) [0|0] "" Vector__XXX
 SG_ CC_a042_pcbaTempFoldback : 41|1@1+ (1,0) [0|0] "" Vector__XXX
 SG_ CC_a043_configurationRequired : 42|1@1+ (1,0) [0|0] "" Vector__XXX
 SG_ CC_a044_relayCoilVoltageRationality : 43|1@1+ (1,0) [0|0] "" Vector__XXX
 SG_ CC_a045_ACPowerLoss : 44|1@1+ (1,0) [0|0] "" Vector__XXX
 SG_ CC_a046_GFCIConfigInvalid : 45|1@1+ (1,0) [0|0] "" Vector__XXX
 SG_ CC_a047_MDMotorContFault : 46|1@1+ (1,0) [0|0] "" Vector__XXX
 SG_ CC_a048_ACMDAdapterFault : 47|1@1+ (1,0) [0|0] "" Vector__XXX
 SG_ CC_a049_rs485Fault : 48|1@1+ (1,0) [0|0] "" Vector__XXX
 SG_ CC_a050_eFuseFault : 49|1@1+ (1,0) [0|0] "" Vector__XXX
 SG_ CC_a051_chcCriticalFault : 50|1@1+ (1,0) [0|0] "" Vector__XXX
 SG_ CC_a052_vRefOutOfRangePWM : 51|1@1+ (1,0) [0|0] "" Vector__XXX
 SG_ CC_a057_chcVitalsRequestFailure : 56|1@1+ (1,0) [0|0] "" Vector__XXX
 SG_ CC_a060_persistenceFault : 59|1@1+ (1,0) [0|0] "" Vector__XXX
 SG_ CC_a061_unfinishedCommissioning : 60|1@1+ (1,0) [0|0] "" Vector__XXX

BO_ 1138 BMS_chargeInfo: 8 Vector__XXX
 SG_ BMS_cellChargeDcCurrentLimit : 0|12@1+ (0.5,0) [0|0] "" Vector__XXX
 SG_ BMS_voltageRegCurrentTarget : 12|12@1+ (0.5,0) [0|0] "" Vector__XXX
 SG_ BMS_vehicleChargeDcCurrentLimit : 24|12@1+ (0.5,0) [0|0] "" Vector__XXX
 SG_ BMS_userChargeCurrentLimitMode : 36|3@1+ (1,0) [0|0] "" Vector__XXX
 SG_ BMS_chargeCurrentLimitMode : 40|5@1+ (1,0) [0|0] "" Vector__XXX
 SG_ BMS_timeToFinishHeatForCharge : 45|7@1+ (5,0) [0|0] "" Vector__XXX
 SG_ BMS_timeToTripPlanChargingTarget : 52|11@1+ (1,0) [0|0] "" Vector__XXX
 SG_ BMS_useChargeTimeEstimate : 63|1@1+ (1,0) [0|0] "" Vector__XXX

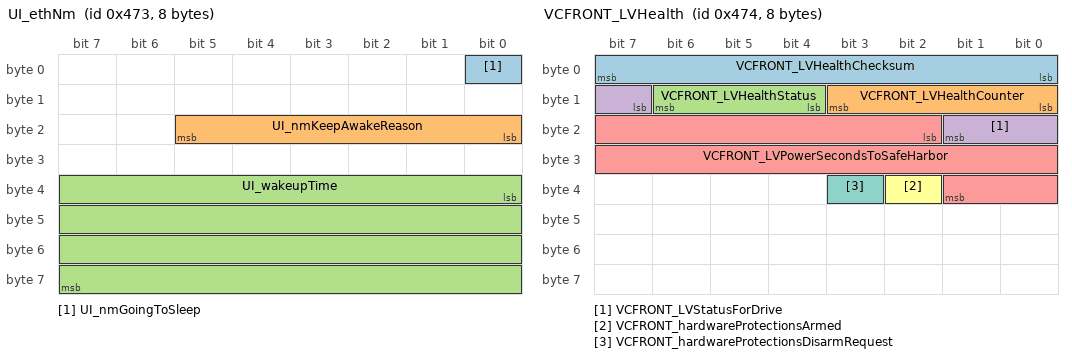
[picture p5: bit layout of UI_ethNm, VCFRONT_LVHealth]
BO_ 1139 UI_ethNm: 8 Vector__XXX
 SG_ UI_nmGoingToSleep : 0|1@1+ (1,0) [0|0] "" Vector__XXX
 SG_ UI_nmKeepAwakeReason : 16|6@1+ (1,0) [0|0] "" Vector__XXX
 SG_ UI_wakeupTime : 32|32@1+ (1,0) [0|0] "" Vector__XXX

BO_ 1140 VCFRONT_LVHealth: 8 Vector__XXX
 SG_ VCFRONT_LVHealthChecksum : 0|8@1+ (1,0) [0|0] "" Vector__XXX
 SG_ VCFRONT_LVHealthCounter : 8|4@1+ (1,0) [0|0] "" Vector__XXX
 SG_ VCFRONT_LVHealthStatus : 12|3@1+ (1,0) [0|0] "" Vector__XXX
 SG_ VCFRONT_LVStatusForDrive : 15|3@1+ (1,0) [0|0] "" Vector__XXX
 SG_ VCFRONT_LVPowerSecondsToSafeHarbor : 18|16@1+ (1,0) [0|0] "" Vector__XXX
 SG_ VCFRONT_hardwareProtectionsArmed : 34|1@1+ (1,0) [0|0] "" Vector__XXX
 SG_ VCFRONT_hardwareProtectionsDisarmRequest : 35|1@1+ (1,0) [0|0] "" Vector__XXX

BO_ 1145 GTW_bootp: 8 Vector__XXX
 SG_ GTW_bootpByte : 0|8@1+ (1,0) [0|0] "" Vector__XXX

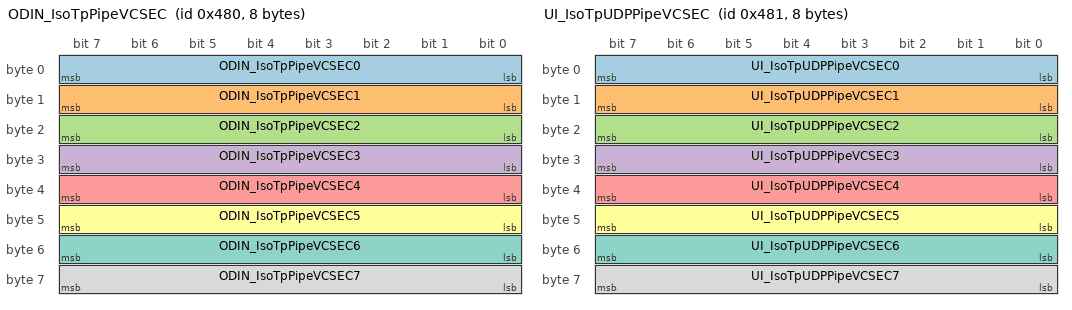
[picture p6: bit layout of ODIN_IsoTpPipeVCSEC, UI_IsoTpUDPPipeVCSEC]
BO_ 1152 ODIN_IsoTpPipeVCSEC: 8 Vector__XXX
 SG_ ODIN_IsoTpPipeVCSEC0 : 7|8@0+ (1,0) [0|0] "" Vector__XXX
 SG_ ODIN_IsoTpPipeVCSEC1 : 15|8@0+ (1,0) [0|0] "" Vector__XXX
 SG_ ODIN_IsoTpPipeVCSEC2 : 23|8@0+ (1,0) [0|0] "" Vector__XXX
 SG_ ODIN_IsoTpPipeVCSEC3 : 31|8@0+ (1,0) [0|0] "" Vector__XXX
 SG_ ODIN_IsoTpPipeVCSEC4 : 39|8@0+ (1,0) [0|0] "" Vector__XXX
 SG_ ODIN_IsoTpPipeVCSEC5 : 47|8@0+ (1,0) [0|0] "" Vector__XXX
 SG_ ODIN_IsoTpPipeVCSEC6 : 55|8@0+ (1,0) [0|0] "" Vector__XXX
 SG_ ODIN_IsoTpPipeVCSEC7 : 63|8@0+ (1,0) [0|0] "" Vector__XXX

BO_ 1153 UI_IsoTpUDPPipeVCSEC: 8 Vector__XXX
 SG_ UI_IsoTpUDPPipeVCSEC0 : 7|8@0+ (1,0) [0|0] "" Vector__XXX
 SG_ UI_IsoTpUDPPipeVCSEC1 : 15|8@0+ (1,0) [0|0] "" Vector__XXX
 SG_ UI_IsoTpUDPPipeVCSEC2 : 23|8@0+ (1,0) [0|0] "" Vector__XXX
 SG_ UI_IsoTpUDPPipeVCSEC3 : 31|8@0+ (1,0) [0|0] "" Vector__XXX
 SG_ UI_IsoTpUDPPipeVCSEC4 : 39|8@0+ (1,0) [0|0] "" Vector__XXX
 SG_ UI_IsoTpUDPPipeVCSEC5 : 47|8@0+ (1,0) [0|0] "" Vector__XXX
 SG_ UI_IsoTpUDPPipeVCSEC6 : 55|8@0+ (1,0) [0|0] "" Vector__XXX
 SG_ UI_IsoTpUDPPipeVCSEC7 : 63|8@0+ (1,0) [0|0] "" Vector__XXX

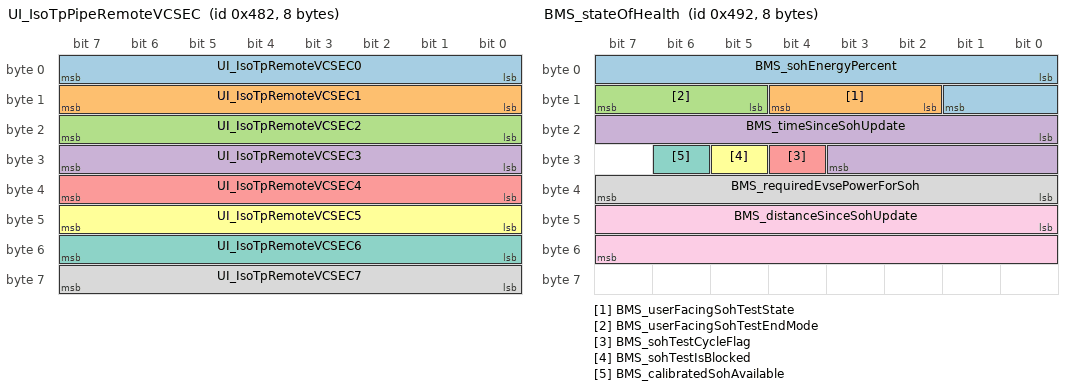
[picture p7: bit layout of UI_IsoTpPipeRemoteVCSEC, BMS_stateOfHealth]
BO_ 1154 UI_IsoTpPipeRemoteVCSEC: 8 Vector__XXX
 SG_ UI_IsoTpRemoteVCSEC0 : 7|8@0+ (1,0) [0|0] "" Vector__XXX
 SG_ UI_IsoTpRemoteVCSEC1 : 15|8@0+ (1,0) [0|0] "" Vector__XXX
 SG_ UI_IsoTpRemoteVCSEC2 : 23|8@0+ (1,0) [0|0] "" Vector__XXX
 SG_ UI_IsoTpRemoteVCSEC3 : 31|8@0+ (1,0) [0|0] "" Vector__XXX
 SG_ UI_IsoTpRemoteVCSEC4 : 39|8@0+ (1,0) [0|0] "" Vector__XXX
 SG_ UI_IsoTpRemoteVCSEC5 : 47|8@0+ (1,0) [0|0] "" Vector__XXX
 SG_ UI_IsoTpRemoteVCSEC6 : 55|8@0+ (1,0) [0|0] "" Vector__XXX
 SG_ UI_IsoTpRemoteVCSEC7 : 63|8@0+ (1,0) [0|0] "" Vector__XXX

BO_ 1170 BMS_stateOfHealth: 8 Vector__XXX
 SG_ BMS_sohEnergyPercent : 0|10@1+ (0.1,0) [0|0] "" Vector__XXX
 SG_ BMS_userFacingSohTestState : 10|3@1+ (1,0) [0|0] "" Vector__XXX
 SG_ BMS_userFacingSohTestEndMode : 13|3@1+ (1,0) [0|0] "" Vector__XXX
 SG_ BMS_timeSinceSohUpdate : 16|12@1+ (1,0) [0|0] "" Vector__XXX
 SG_ BMS_sohTestCycleFlag : 28|1@1+ (1,0) [0|0] "" Vector__XXX
 SG_ BMS_sohTestIsBlocked : 29|1@1+ (1,0) [0|0] "" Vector__XXX
 SG_ BMS_calibratedSohAvailable : 30|1@1+ (1,0) [0|0] "" Vector__XXX
 SG_ BMS_requiredEvsePowerForSoh : 32|8@1+ (0.125,0) [0|0] "" Vector__XXX
 SG_ BMS_distanceSinceSohUpdate : 40|16@1+ (1,0) [0|0] "" Vector__XXX

BO_ 1173 VCFRONT_LVHealthDebug: 8 Vector__XXX
 SG_ VCFRONT_LVHealthDebugIndex M : 0|4@1+ (1,0) [0|0] "" Vector__XXX
 SG_ VCFRONT_LVHEALTH_placeholder m0 : 8|1@1+ (1,0) [0|0] "" Vector__XXX
 SG_ VCFRONT_placeholderCheckResult m1 : 8|2@1+ (1,0) [0|0] "" Vector__XXX
 SG_ VCFRONT_LVHEALTH_activeDecelEnergyWarning m0 : 9|1@1+ (1,0) [0|0] "" Vector__XXX
 SG_ VCFRONT_LVHEALTH_criticalPulloverEnergyWarning m0 : 10|1@1+ (1,0) [0|0] "" Vector__XXX
 SG_ VCFRONT_activeDecelEnergyCheckResult m1 : 10|2@1+ (1,0) [0|0] "" Vector__XXX
 SG_ VCFRONT_LVHEALTH_revBattEFuseOff m0 : 11|1@1+ (1,0) [0|0] "" Vector__XXX
 SG_ VCFRONT_LVHEALTH_LVBMBEFuseOpen m0 : 12|1@1+ (1,0) [0|0] "" Vector__XXX
 SG_ VCFRONT_criticalPulloverEnergyCheckResult m1 : 12|2@1+ (1,0) [0|0] "" Vector__XXX
 SG_ VCFRONT_LVHEALTH_lvBatteryCommsMia m0 : 13|1@1+ (1,0) [0|0] "" Vector__XXX
 SG_ VCFRONT_LVHEALTH_pcsEFuseOff m0 : 14|1@1+ (1,0) [0|0] "" Vector__XXX
 SG_ VCFRONT_revBattEFuseCheckResult m1 : 14|2@1+ (1,0) [0|0] "" Vector__XXX
 SG_ VCFRONT_LVHEALTH_pcsNotActive m0 : 15|1@1+ (1,0) [0|0] "" Vector__XXX
 SG_ VCFRONT_LVBMBEFuseCheckResult m1 : 16|2@1+ (1,0) [0|0] "" Vector__XXX
 SG_ VCFRONT_LVHEALTH_pcsMIA m0 : 16|1@1+ (1,0) [0|0] "" Vector__XXX
 SG_ VCFRONT_LVHEALTH_IBSMIA m0 : 17|1@1+ (1,0) [0|0] "" Vector__XXX
 SG_ VCFRONT_LVHEALTH_LVBatteryElecDisc m0 : 18|1@1+ (1,0) [0|0] "" Vector__XXX
 SG_ VCFRONT_lvBatteryCommsMiaCheckResult m1 : 18|2@1+ (1,0) [0|0] "" Vector__XXX
 SG_ VCFRONT_LVHEALTH_LVBatteryElecDiscUnknown m0 : 19|1@1+ (1,0) [0|0] "" Vector__XXX
 SG_ VCFRONT_LVHEALTH_pcsOpenCircuit m0 : 20|1@1+ (1,0) [0|0] "" Vector__XXX
 SG_ VCFRONT_pcsEFuseOffCheckResult m1 : 20|2@1+ (1,0) [0|0] "" Vector__XXX
 SG_ VCFRONT_LVHEALTH_activeDecelPowerWarning m0 : 21|1@1+ (1,0) [0|0] "" Vector__XXX
 SG_ VCFRONT_LVHEALTH_lvBatteryCapabilityLowAccuracy m0 : 22|1@1+ (1,0) [0|0] "" Vector__XXX
 SG_ VCFRONT_pcsNotActiveCheckResult m1 : 22|2@1+ (1,0) [0|0] "" Vector__XXX
 SG_ VCFRONT_LVHEALTH_lvBatteryConfiguration m0 : 23|1@1+ (1,0) [0|0] "" Vector__XXX
 SG_ VCFRONT_LVHEALTH_lvBatteryImpedance m0 : 24|1@1+ (1,0) [0|0] "" Vector__XXX
 SG_ VCFRONT_pcsMIACheckResult m1 : 24|2@1+ (1,0) [0|0] "" Vector__XXX
 SG_ VCFRONT_LVHEALTH_lvBatteryExtendedOverVoltage m0 : 25|1@1+ (1,0) [0|0] "" Vector__XXX
 SG_ VCFRONT_IBSMIACheckResult m1 : 26|2@1+ (1,0) [0|0] "" Vector__XXX
 SG_ VCFRONT_LVBattElecDiscCheckResult m1 : 28|2@1+ (1,0) [0|0] "" Vector__XXX
 SG_ VCFRONT_LVBattElecDiscUnknownCheckResult m1 : 30|2@1+ (1,0) [0|0] "" Vector__XXX
 SG_ VCFRONT_pcsOpenCircuitCheckResult m1 : 32|2@1+ (1,0) [0|0] "" Vector__XXX
 SG_ VCFRONT_activeDecelPowerCheckResult m1 : 34|2@1+ (1,0) [0|0] "" Vector__XXX
 SG_ VCFRONT_lvBatteryCapabilityAccuracyCheckResult m1 : 36|2@1+ (1,0) [0|0] "" Vector__XXX
 SG_ VCFRONT_lvBatteryConfigurationCheckResult m1 : 38|2@1+ (1,0) [0|0] "" Vector__XXX
 SG_ VCFRONT_lvBatteryImpedanceCheckResult m1 : 40|2@1+ (1,0) [0|0] "" Vector__XXX
 SG_ VCFRONT_lvBatteryExtendedOverVoltageCheckResult m1 : 42|2@1+ (1,0) [0|0] "" Vector__XXX

BO_ 1175 VCBATT1_LVHealthDebug: 8 Vector__XXX
 SG_ VCBATT1_LVHealthDebugIndex M : 0|4@1+ (1,0) [0|0] "" Vector__XXX
 SG_ VCBATT1_bridgeStateCheckResult m0 : 4|2@1+ (1,0) [0|0] "" Vector__XXX
 SG_ VCBATT1_dualPowerLoadsSelfTestSMState m3 : 4|2@1+ (1,0) [0|0] "" Vector__XXX
 SG_ VCBATT1_ocProtectionState m2 : 4|3@1+ (1,0) [0|0] "" Vector__XXX
 SG_ VCBATT1_ovReferenceMonitor m1 : 4|12@1+ (0.005443676098,0) [0|0] "" Vector__XXX
 SG_ VCBATT1_selfTestsStartReason m4 : 4|3@1+ (1,0) [0|0] "" Vector__XXX
 SG_ VCBATT1_bridgeEFuseSelfTestCheckResult m0 : 6|2@1+ (1,0) [0|0] "" Vector__XXX
 SG_ VCBATT1_ocSelfTestEnablePinActive m2 : 7|1@1+ (1,0) [0|0] "" Vector__XXX
 SG_ VCBATT1_selfTestsBlockedByDrive m4 : 7|1@1+ (1,0) [0|0] "" Vector__XXX
 SG_ VCBATT1_hvcBatteryPowerFeedVoltage m3 : 8|12@1+ (0.005443676098,0) [0|0] "" Vector__XXX
 SG_ VCBATT1_ocSelfTestPWM m2 : 8|7@1+ (1,0) [0|0] "" Vector__XXX
 SG_ VCBATT1_selfTestsBlockedByLVBusControl m4 : 8|1@1+ (1,0) [0|0] "" Vector__XXX
 SG_ VCBATT1_vcfrontCommsCheckResult m0 : 8|2@1+ (1,0) [0|0] "" Vector__XXX
 SG_ VCBATT1_selfTestsBlockedByPCSNotSupporting m4 : 9|1@1+ (1,0) [0|0] "" Vector__XXX
 SG_ VCBATT1_selfTestsBlockedByMissingHighPower m4 : 10|1@1+ (1,0) [0|0] "" Vector__XXX
 SG_ VCBATT1_undervoltageTripStateCheckResult m0 : 10|2@1+ (1,0) [0|0] "" Vector__XXX
 SG_ VCBATT1_selfTestsBlockedByLVBatteryNotGood m4 : 11|1@1+ (1,0) [0|0] "" Vector__XXX
 SG_ VCBATT1_selfTestsBlockedByLVBatteryEfuseOpen m4 : 12|1@1+ (1,0) [0|0] "" Vector__XXX
 SG_ VCBATT1_undervoltageSelfTestCheckResult m0 : 12|2@1+ (1,0) [0|0] "" Vector__XXX
 SG_ VCBATT1_selfTestsBlockedByLVBatteryMosOpen m4 : 13|1@1+ (1,0) [0|0] "" Vector__XXX
 SG_ VCBATT1_overvoltageTripStateCheckResult m0 : 14|2@1+ (1,0) [0|0] "" Vector__XXX
 SG_ VCBATT1_selfTestsBlockedByLVBatterySupport m4 : 14|1@1+ (1,0) [0|0] "" Vector__XXX
 SG_ VCBATT1_selfTestsBlockedByLVBMBAttemptingRecovery m4 : 15|1@1+ (1,0) [0|0] "" Vector__XXX
 SG_ VCBATT1_ocSenseAmpCurrent m2 : 16|12@1+ (0.1,0) [0|0] "" Vector__XXX
 SG_ VCBATT1_ovBridgeShutdownFaultActive m1 : 16|1@1+ (1,0) [0|0] "" Vector__XXX
 SG_ VCBATT1_overvoltageSelfTestCheckResult m0 : 16|2@1+ (1,0) [0|0] "" Vector__XXX
 SG_ VCBATT1_selfTestsBlockedByBridgeOpen m4 : 16|1@1+ (1,0) [0|0] "" Vector__XXX
 SG_ VCBATT1_ovProtectionState m1 : 17|3@1+ (1,0) [0|0] "" Vector__XXX
 SG_ VCBATT1_selfTestsBlockedBySelfTestsRunning m4 : 17|1@1+ (1,0) [0|0] "" Vector__XXX
 SG_ VCBATT1_overcurrentTripStateCheckResult m0 : 18|2@1+ (1,0) [0|0] "" Vector__XXX
 SG_ VCBATT1_selfTestsBlockedByTestStatusNotReceived m4 : 18|1@1+ (1,0) [0|0] "" Vector__XXX
 SG_ VCBATT1_selfTestsBlockedByOTAActive m4 : 19|1@1+ (1,0) [0|0] "" Vector__XXX
 SG_ VCBATT1_hvcPCSPowerFeedVoltage m3 : 20|12@1+ (0.005443676098,0) [0|0] "" Vector__XXX
 SG_ VCBATT1_ovBridgeReset m1 : 20|1@1+ (1,0) [0|0] "" Vector__XXX
 SG_ VCBATT1_overcurrentSelfTestCheckResult m0 : 20|2@1+ (1,0) [0|0] "" Vector__XXX
 SG_ VCBATT1_selfTestsBlockedByECUMismatch m4 : 20|1@1+ (1,0) [0|0] "" Vector__XXX
 SG_ VCBATT1_ovBridgeFaultInject m1 : 21|1@1+ (1,0) [0|0] "" Vector__XXX
 SG_ VCBATT1_selfTestsBlockedByUnparked m4 : 21|1@1+ (1,0) [0|0] "" Vector__XXX
 SG_ VCBATT1_dualPowerLoadsSelfTestCheckResult m0 : 22|2@1+ (1,0) [0|0] "" Vector__XXX
 SG_ VCBATT1_ovTimingSelfTestEn m1 : 22|1@1+ (1,0) [0|0] "" Vector__XXX
 SG_ VCBATT1_selfTestsBlockedByBridgeEfusesNotReady m4 : 22|1@1+ (1,0) [0|0] "" Vector__XXX
 SG_ VCBATT1_bridgeOutState m1 : 23|1@1+ (1,0) [0|0] "" Vector__XXX
 SG_ VCBATT1_selfTestsBlockedByHardwareFaultActive m4 : 23|1@1+ (1,0) [0|0] "" Vector__XXX
 SG_ VCBATT1_ARailLocked m1 : 24|1@1+ (1,0) [0|0] "" Vector__XXX
 SG_ VCBATT1_hardwareProtectionsArmStateCheckResult m0 : 24|2@1+ (1,0) [0|0] "" Vector__XXX
 SG_ VCBATT1_selfTestsBlockedByLowBusVoltage m4 : 24|1@1+ (1,0) [0|0] "" Vector__XXX
 SG_ VCBATT1_selfTestsBlockedByThermalTestsRunning m4 : 25|1@1+ (1,0) [0|0] "" Vector__XXX
 SG_ VCBATT1_upstreamLoadshedEfuseVoltage m1 : 25|12@1+ (0.005443676098,0) [0|0] "" Vector__XXX
 SG_ VCBATT1_eFuseConfigurationCheckResult m0 : 26|2@1+ (1,0) [0|0] "" Vector__XXX
 SG_ VCBATT1_selfTestsBlockedByLoadshedEfuseOpen m4 : 26|1@1+ (1,0) [0|0] "" Vector__XXX
 SG_ VCBATT1_selfTestsBlockedBySelfTestsDisabled m4 : 27|1@1+ (1,0) [0|0] "" Vector__XXX
 SG_ VCBATT1_revBattEFuseStateCheckResult m0 : 28|2@1+ (1,0) [0|0] "" Vector__XXX
 SG_ VCBATT1_selfTestsBlockedByDefogTestsRunning m4 : 28|1@1+ (1,0) [0|0] "" Vector__XXX
 SG_ VCBATT1_selfTestsBlockedByOutOfRetries m4 : 29|1@1+ (1,0) [0|0] "" Vector__XXX
 SG_ VCBATT1_lvBattElecConnectionCheckResult m0 : 30|2@1+ (1,0) [0|0] "" Vector__XXX
 SG_ VCBATT1_selfTestsBlockedByFactoryGated m4 : 30|1@1+ (1,0) [0|0] "" Vector__XXX
 SG_ VCBATT1_selfTestsBlockedByVCFrontMIA m4 : 31|1@1+ (1,0) [0|0] "" Vector__XXX
 SG_ VCBATT1_hvcDualPowerFeedVoltage m3 : 32|12@1+ (0.005443676098,0) [0|0] "" Vector__XXX
 SG_ VCBATT1_lvBattElecConnectionConfidenceCheckResult m0 : 32|2@1+ (1,0) [0|0] "" Vector__XXX
 SG_ VCBATT1_ocSelfTestFailureReason m2 : 32|7@1+ (1,0) [0|0] "" Vector__XXX
 SG_ VCBATT1_selfTestsBlockedByVCRightMIA m4 : 32|1@1+ (1,0) [0|0] "" Vector__XXX
 SG_ VCBATT1_selfTestsBlockedByPCSMIA m4 : 33|1@1+ (1,0) [0|0] "" Vector__XXX
 SG_ VCBATT1_lvBattCommsCheckResult m0 : 34|2@1+ (1,0) [0|0] "" Vector__XXX
 SG_ VCBATT1_selfTestsBlockedByGTWMIA m4 : 34|1@1+ (1,0) [0|0] "" Vector__XXX
 SG_ VCBATT1_selfTestsOpportunisticBlockedByWaitForUserLeft m4 : 35|1@1+ (1,0) [0|0] "" Vector__XXX
 SG_ VCBATT1_lvBattEFuseStateCheckResult m0 : 36|2@1+ (1,0) [0|0] "" Vector__XXX
 SG_ VCBATT1_selfTestsOpportunisticBlockedByPotentialUserApproach m4 : 36|1@1+ (1,0) [0|0] "" Vector__XXX
 SG_ VCBATT1_upstreamLoadshedEfuseLVState m1 : 37|2@1+ (1,0) [0|0] "" Vector__XXX
 SG_ VCBATT1_lvBattSensorCommsCheckResult m0 : 38|2@1+ (1,0) [0|0] "" Vector__XXX
 SG_ VCBATT1_ocSlowFaultActive m2 : 39|1@1+ (1,0) [0|0] "" Vector__XXX
 SG_ VCBATT1_uvLoadshedFaultActive m1 : 39|1@1+ (1,0) [0|0] "" Vector__XXX
 SG_ VCBATT1_lvBattVSenseRationalityCheckResult m0 : 40|2@1+ (1,0) [0|0] "" Vector__XXX
 SG_ VCBATT1_ocMediumFaultActive m2 : 40|1@1+ (1,0) [0|0] "" Vector__XXX
 SG_ VCBATT1_uvLoadshedReset m1 : 40|1@1+ (1,0) [0|0] "" Vector__XXX
 SG_ VCBATT1_ocFastFaultActive m2 : 41|1@1+ (1,0) [0|0] "" Vector__XXX
 SG_ VCBATT1_uvReferenceMonitor m1 : 41|12@1+ (0.005443676098,0) [0|0] "" Vector__XXX
 SG_ VCBATT1_lvBattISenseRationalityCheckResult m0 : 42|2@1+ (1,0) [0|0] "" Vector__XXX
 SG_ VCBATT1_revBattGateVoltage m2 : 42|13@1+ (0.005443676098,0) [0|0] "" Vector__XXX
 SG_ VCBATT1_lvBattEnergyUrgentPulloverCheckResult m0 : 44|2@1+ (1,0) [0|0] "" Vector__XXX
 SG_ VCBATT1_lvBattEnergyActiveDecelCheckResult m0 : 46|2@1+ (1,0) [0|0] "" Vector__XXX
 SG_ VCBATT1_lvBattPowerActiveDecelCheckResult m0 : 48|2@1+ (1,0) [0|0] "" Vector__XXX
 SG_ VCBATT1_lvBattEnergyPulloverCheckResult m0 : 50|2@1+ (1,0) [0|0] "" Vector__XXX
 SG_ VCBATT1_lvBattCapabilityAccCheckResult m0 : 52|2@1+ (1,0) [0|0] "" Vector__XXX
 SG_ VCBATT1_uvTimingSelfTestEn m1 : 53|1@1+ (1,0) [0|0] "" Vector__XXX
 SG_ VCBATT1_lvBattConfigurationCheckResult m0 : 54|2@1+ (1,0) [0|0] "" Vector__XXX
 SG_ VCBATT1_uvLoadshedFaultInject m1 : 54|1@1+ (1,0) [0|0] "" Vector__XXX
 SG_ VCBATT1_bridgeShutdownActive m1 : 55|1@1+ (1,0) [0|0] "" Vector__XXX
 SG_ VCBATT1_lvBattImpedanceCheckResult m0 : 56|2@1+ (1,0) [0|0] "" Vector__XXX
 SG_ VCBATT1_revBattEFuseState m2 : 56|2@1+ (1,0) [0|0] "" Vector__XXX
 SG_ VCBATT1_bridgeOcFaultActive m2 : 58|1@1+ (1,0) [0|0] "" Vector__XXX
 SG_ VCBATT1_lvBattCriticalResistanceCheckResult m0 : 58|2@1+ (1,0) [0|0] "" Vector__XXX
 SG_ VCBATT1_bridgeOcRevBattFaultInject m2 : 59|1@1+ (1,0) [0|0] "" Vector__XXX
 SG_ VCBATT1_bridgeOcReset m2 : 60|1@1+ (1,0) [0|0] "" Vector__XXX

BO_ 1176 VCFRONT1_LVHealthDebug: 8 Vector__XXX
 SG_ VCFRONT1_LVHealthDebugIndex M : 0|4@1+ (1,0) [0|0] "" Vector__XXX
 SG_ VCFRONT1_bridgeStateCheckResult m0 : 4|2@1+ (1,0) [0|0] "" Vector__XXX
 SG_ VCFRONT1_ovClampMonitorVoltage2 m3 : 4|12@1+ (0.005443676098,0) [0|0] "" Vector__XXX
 SG_ VCFRONT1_pcsOvShutdownState m2 : 4|4@1+ (1,0) [0|0] "" Vector__XXX
 SG_ VCFRONT1_uvLoadshedFaultActive m1 : 4|1@1+ (1,0) [0|0] "" Vector__XXX
 SG_ VCFRONT1_uvLoadshedFaultInject m1 : 5|1@1+ (1,0) [0|0] "" Vector__XXX
 SG_ VCFRONT1_bridgeEFuseSelfTestCheckResult m0 : 6|2@1+ (1,0) [0|0] "" Vector__XXX
 SG_ VCFRONT1_uvLoadshedReset m1 : 6|1@1+ (1,0) [0|0] "" Vector__XXX
 SG_ VCFRONT1_ovShutdownArmed m2 : 8|1@1+ (1,0) [0|0] "" Vector__XXX
 SG_ VCFRONT1_uvReferenceMonitor m1 : 8|12@1+ (0.005443676098,0) [0|0] "" Vector__XXX
 SG_ VCFRONT1_vcbattCommsCheckResult m0 : 8|2@1+ (1,0) [0|0] "" Vector__XXX
 SG_ VCFRONT1_ovShutdownArmedFeedback m2 : 9|1@1+ (1,0) [0|0] "" Vector__XXX
 SG_ VCFRONT1_ovShutdownFaultActive m2 : 10|1@1+ (1,0) [0|0] "" Vector__XXX
 SG_ VCFRONT1_undervoltageTripStateCheckResult m0 : 10|2@1+ (1,0) [0|0] "" Vector__XXX
 SG_ VCFRONT1_ovShutdownFaultInject m2 : 11|1@1+ (1,0) [0|0] "" Vector__XXX
 SG_ VCFRONT1_dcdcEnableVoltage m2 : 12|12@1+ (0.005443676098,0) [0|0] "" Vector__XXX
 SG_ VCFRONT1_undervoltageSelfTestCheckResult m0 : 12|2@1+ (1,0) [0|0] "" Vector__XXX
 SG_ VCFRONT1_overvoltageTripStateCheckResult m0 : 14|2@1+ (1,0) [0|0] "" Vector__XXX
 SG_ VCFRONT1_ovClampMonitorVoltage3 m3 : 16|12@1+ (0.005443676098,0) [0|0] "" Vector__XXX
 SG_ VCFRONT1_overvoltageSelfTestCheckResult m0 : 16|2@1+ (1,0) [0|0] "" Vector__XXX
 SG_ VCFRONT1_hardwareProtectionsArmStateCheckResult m0 : 18|2@1+ (1,0) [0|0] "" Vector__XXX
 SG_ VCFRONT1_pcsShutdownTripStateCheckResult m0 : 20|2@1+ (1,0) [0|0] "" Vector__XXX
 SG_ VCFRONT1_uvTimingSelfTestEn m1 : 20|1@1+ (1,0) [0|0] "" Vector__XXX
 SG_ VCFRONT1_pcsShutdownSelfTestCheckResult m0 : 22|2@1+ (1,0) [0|0] "" Vector__XXX
 SG_ VCFRONT1_ovClampBusVoltage m2 : 24|12@1+ (0.005443676098,0) [0|0] "" Vector__XXX
 SG_ VCFRONT1_ovReferenceMonitor m1 : 24|12@1+ (0.005443676098,0) [0|0] "" Vector__XXX
 SG_ VCFRONT1_pcsShutdownArmStateCheckResult m0 : 24|2@1+ (1,0) [0|0] "" Vector__XXX
 SG_ VCFRONT1_eFuseConfigurationCheckResult m0 : 26|2@1+ (1,0) [0|0] "" Vector__XXX
 SG_ VCFRONT1_pcsEFuseStateCheckResult m0 : 28|2@1+ (1,0) [0|0] "" Vector__XXX
 SG_ VCFRONT1_pcsElecConnConfidenceCheckResult m0 : 30|2@1+ (1,0) [0|0] "" Vector__XXX
 SG_ VCFRONT1_pcsElecConnCheckResult m0 : 32|2@1+ (1,0) [0|0] "" Vector__XXX
 SG_ VCFRONT1_pcsCommsCheckResult m0 : 34|2@1+ (1,0) [0|0] "" Vector__XXX
 SG_ VCFRONT1_ovBridgeShutdownFaultActive m1 : 36|1@1+ (1,0) [0|0] "" Vector__XXX
 SG_ VCFRONT1_ovClampReferenceVoltage m2 : 36|12@1+ (0.005443676098,0) [0|0] "" Vector__XXX
 SG_ VCFRONT1_pcsPowerCapabilityCheckResult m0 : 36|2@1+ (1,0) [0|0] "" Vector__XXX
 SG_ VCFRONT1_ovBridgeFaultInject m1 : 37|1@1+ (1,0) [0|0] "" Vector__XXX
 SG_ VCFRONT1_ovBridgeReset m1 : 38|1@1+ (1,0) [0|0] "" Vector__XXX
 SG_ VCFRONT1_pcsSupportStatusCheckResult m0 : 38|2@1+ (1,0) [0|0] "" Vector__XXX
 SG_ VCFRONT1_ovTimingSelfTestEn m1 : 39|1@1+ (1,0) [0|0] "" Vector__XXX
 SG_ VCFRONT1_ovProtectionState m1 : 40|3@1+ (1,0) [0|0] "" Vector__XXX
 SG_ VCFRONT1_pcsOvClampReferenceRationalityCheckResult m0 : 40|2@1+ (1,0) [0|0] "" Vector__XXX
 SG_ VCFRONT1_pcsOvClampBusRationalityCheckResult m0 : 42|2@1+ (1,0) [0|0] "" Vector__XXX
 SG_ VCFRONT1_bridgeOutState m1 : 43|1@1+ (1,0) [0|0] "" Vector__XXX
 SG_ VCFRONT1_BRailLocked m1 : 44|1@1+ (1,0) [0|0] "" Vector__XXX
 SG_ VCFRONT1_pcsOvClampTripStateCheckResult m0 : 44|2@1+ (1,0) [0|0] "" Vector__XXX
 SG_ VCFRONT1_pcsOvClampArmStateCheckResult m0 : 46|2@1+ (1,0) [0|0] "" Vector__XXX
 SG_ VCFRONT1_hvcEFuseStateCheckResult m0 : 48|2@1+ (1,0) [0|0] "" Vector__XXX
 SG_ VCFRONT1_ovClampMonitorVoltage1 m2 : 48|12@1+ (0.005443676098,0) [0|0] "" Vector__XXX
 SG_ VCFRONT1_upstreamLoadshedVoltage m1 : 48|12@1+ (0.005443676098,0) [0|0] "" Vector__XXX
 SG_ VCFRONT1_pcsCriticalResistanceCheckResult m0 : 50|2@1+ (1,0) [0|0] "" Vector__XXX
 SG_ VCFRONT1_ovClampActive m2 : 60|1@1+ (1,0) [0|0] "" Vector__XXX
 SG_ VCFRONT1_upstreamLoadshedEfuseLVState m1 : 60|2@1+ (1,0) [0|0] "" Vector__XXX
 SG_ VCFRONT1_bridgeShutdownActive m1 : 62|1@1+ (1,0) [0|0] "" Vector__XXX

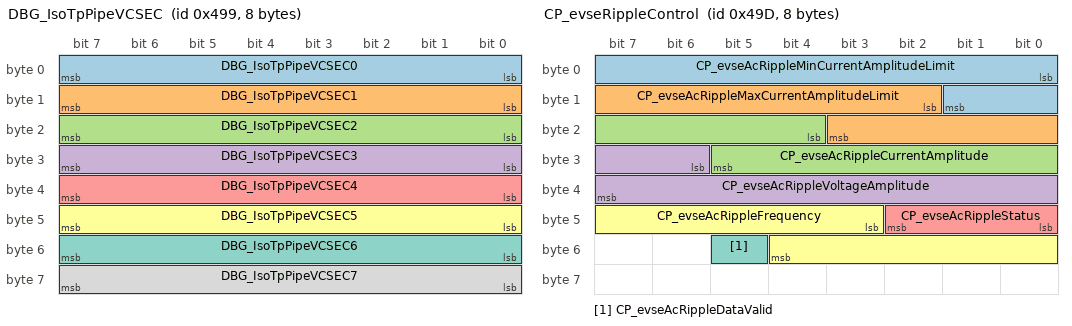
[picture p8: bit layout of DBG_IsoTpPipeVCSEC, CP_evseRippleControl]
BO_ 1177 DBG_IsoTpPipeVCSEC: 8 Vector__XXX
 SG_ DBG_IsoTpPipeVCSEC0 : 0|8@1+ (1,0) [0|0] "" Vector__XXX
 SG_ DBG_IsoTpPipeVCSEC1 : 8|8@1+ (1,0) [0|0] "" Vector__XXX
 SG_ DBG_IsoTpPipeVCSEC2 : 16|8@1+ (1,0) [0|0] "" Vector__XXX
 SG_ DBG_IsoTpPipeVCSEC3 : 24|8@1+ (1,0) [0|0] "" Vector__XXX
 SG_ DBG_IsoTpPipeVCSEC4 : 32|8@1+ (1,0) [0|0] "" Vector__XXX
 SG_ DBG_IsoTpPipeVCSEC5 : 40|8@1+ (1,0) [0|0] "" Vector__XXX
 SG_ DBG_IsoTpPipeVCSEC6 : 48|8@1+ (1,0) [0|0] "" Vector__XXX
 SG_ DBG_IsoTpPipeVCSEC7 : 56|8@1+ (1,0) [0|0] "" Vector__XXX

BO_ 1181 CP_evseRippleControl: 8 Vector__XXX
 SG_ CP_evseAcRippleMinCurrentAmplitudeLimit : 0|10@1+ (1,0) [0|0] "" Vector__XXX
 SG_ CP_evseAcRippleMaxCurrentAmplitudeLimit : 10|10@1+ (1,0) [0|0] "" Vector__XXX
 SG_ CP_evseAcRippleCurrentAmplitude : 20|10@1+ (1,0) [0|0] "" Vector__XXX
 SG_ CP_evseAcRippleVoltageAmplitude : 30|10@1+ (1,0) [0|0] "" Vector__XXX
 SG_ CP_evseAcRippleStatus : 40|3@1+ (1,0) [0|0] "" Vector__XXX
 SG_ CP_evseAcRippleFrequency : 43|10@1+ (1,0) [0|0] "" Vector__XXX
 SG_ CP_evseAcRippleDataValid : 53|1@1+ (1,0) [0|0] "" Vector__XXX

BO_ 1206 VCSEC_rawRSSI0: 8 Vector__XXX
 SG_ VCSEC_rawRSSI0ChannelIndex M : 0|3@1+ (1,0) [0|0] "" Vector__XXX
 SG_ VCSEC_centerRawRSSI0 m1 : 8|8@1- (1,0) [0|0] "" Vector__XXX
 SG_ VCSEC_frontLeftRawRSSI0 m5 : 8|8@1- (1,0) [0|0] "" Vector__XXX
 SG_ VCSEC_frontRawRSSI0 m4 : 8|8@1- (1,0) [0|0] "" Vector__XXX
 SG_ VCSEC_leftRawRSSI0 m0 : 8|8@1- (1,0) [0|0] "" Vector__XXX
 SG_ VCSEC_rearLeftRawRSSI0 m2 : 8|8@1- (1,0) [0|0] "" Vector__XXX
 SG_ VCSEC_secondaryCenterRawRSSI0 m3 : 8|8@1- (1,0) [0|0] "" Vector__XXX
 SG_ VCSEC_centerReverseRawRSSI0 m1 : 16|8@1- (1,0) [0|0] "" Vector__XXX
 SG_ VCSEC_frontLeftReverseRawRSSI0 m5 : 16|8@1- (1,0) [0|0] "" Vector__XXX
 SG_ VCSEC_frontReverseRawRSSI0 m4 : 16|8@1- (1,0) [0|0] "" Vector__XXX
 SG_ VCSEC_leftReverseRawRSSI0 m0 : 16|8@1- (1,0) [0|0] "" Vector__XXX
 SG_ VCSEC_rearLeftReverseRawRSSI0 m2 : 16|8@1- (1,0) [0|0] "" Vector__XXX
 SG_ VCSEC_secondaryReverseRawRSSI0 m3 : 16|8@1- (1,0) [0|0] "" Vector__XXX
 SG_ VCSEC_centerRSSI0Channel m1 : 24|6@1+ (1,0) [0|0] "" Vector__XXX
 SG_ VCSEC_frontLeftRSSI0Channel m5 : 24|6@1+ (1,0) [0|0] "" Vector__XXX
 SG_ VCSEC_frontRSSI0Channel m4 : 24|6@1+ (1,0) [0|0] "" Vector__XXX
 SG_ VCSEC_leftRSSI0Channel m0 : 24|6@1+ (1,0) [0|0] "" Vector__XXX
 SG_ VCSEC_rearLeftRSSI0Channel m2 : 24|6@1+ (1,0) [0|0] "" Vector__XXX
 SG_ VCSEC_secondaryCenterRSSI0Channel m3 : 24|6@1+ (1,0) [0|0] "" Vector__XXX
 SG_ VCSEC_frontRightRawRSSI0 m5 : 32|8@1- (1,0) [0|0] "" Vector__XXX
 SG_ VCSEC_nfcRawRSSI0 m3 : 32|8@1- (1,0) [0|0] "" Vector__XXX
 SG_ VCSEC_rearRawRSSI0 m1 : 32|8@1- (1,0) [0|0] "" Vector__XXX
 SG_ VCSEC_rearRightRawRSSI0 m2 : 32|8@1- (1,0) [0|0] "" Vector__XXX
 SG_ VCSEC_rightRawRSSI0 m0 : 32|8@1- (1,0) [0|0] "" Vector__XXX
 SG_ VCSEC_frontRightReverseRawRSSI0 m5 : 40|8@1- (1,0) [0|0] "" Vector__XXX
 SG_ VCSEC_nfcReverseRawRSSI0 m3 : 40|8@1- (1,0) [0|0] "" Vector__XXX
 SG_ VCSEC_rearReverseRawRSSI0 m1 : 40|8@1- (1,0) [0|0] "" Vector__XXX
 SG_ VCSEC_rearRightReverseRawRSSI0 m2 : 40|8@1- (1,0) [0|0] "" Vector__XXX
 SG_ VCSEC_rightReverseRawRSSI0 m0 : 40|8@1- (1,0) [0|0] "" Vector__XXX
 SG_ VCSEC_frontRightRSSI0Channel m5 : 48|6@1+ (1,0) [0|0] "" Vector__XXX
 SG_ VCSEC_nfcRSSI0Channel m3 : 48|6@1+ (1,0) [0|0] "" Vector__XXX
 SG_ VCSEC_rearRSSI0Channel m1 : 48|6@1+ (1,0) [0|0] "" Vector__XXX
 SG_ VCSEC_rearRightRSSI0Channel m2 : 48|6@1+ (1,0) [0|0] "" Vector__XXX
 SG_ VCSEC_rightRSSI0Channel m0 : 48|6@1+ (1,0) [0|0] "" Vector__XXX

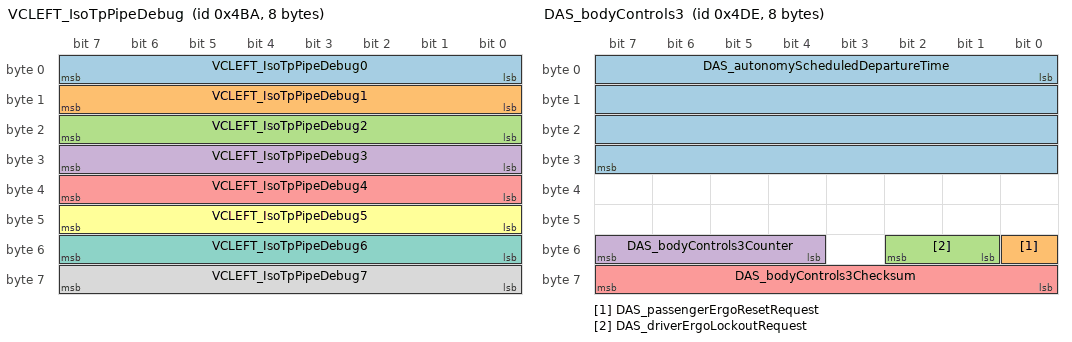
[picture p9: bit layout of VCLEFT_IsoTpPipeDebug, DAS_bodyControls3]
BO_ 1210 VCLEFT_IsoTpPipeDebug: 8 Vector__XXX
 SG_ VCLEFT_IsoTpPipeDebug0 : 0|8@1+ (1,0) [0|0] "" Vector__XXX
 SG_ VCLEFT_IsoTpPipeDebug1 : 8|8@1+ (1,0) [0|0] "" Vector__XXX
 SG_ VCLEFT_IsoTpPipeDebug2 : 16|8@1+ (1,0) [0|0] "" Vector__XXX
 SG_ VCLEFT_IsoTpPipeDebug3 : 24|8@1+ (1,0) [0|0] "" Vector__XXX
 SG_ VCLEFT_IsoTpPipeDebug4 : 32|8@1+ (1,0) [0|0] "" Vector__XXX
 SG_ VCLEFT_IsoTpPipeDebug5 : 40|8@1+ (1,0) [0|0] "" Vector__XXX
 SG_ VCLEFT_IsoTpPipeDebug6 : 48|8@1+ (1,0) [0|0] "" Vector__XXX
 SG_ VCLEFT_IsoTpPipeDebug7 : 56|8@1+ (1,0) [0|0] "" Vector__XXX

BO_ 1214 VCSEC_rawRSSI1: 8 Vector__XXX
 SG_ VCSEC_rawRSSI1ChannelIndex M : 0|3@1+ (1,0) [0|0] "" Vector__XXX
 SG_ VCSEC_centerRawRSSI1 m1 : 8|8@1- (1,0) [0|0] "" Vector__XXX
 SG_ VCSEC_frontLeftRawRSSI1 m5 : 8|8@1- (1,0) [0|0] "" Vector__XXX
 SG_ VCSEC_frontRawRSSI1 m4 : 8|8@1- (1,0) [0|0] "" Vector__XXX
 SG_ VCSEC_leftRawRSSI1 m0 : 8|8@1- (1,0) [0|0] "" Vector__XXX
 SG_ VCSEC_rearLeftRawRSSI1 m2 : 8|8@1- (1,0) [0|0] "" Vector__XXX
 SG_ VCSEC_secondaryCenterRawRSSI1 m3 : 8|8@1- (1,0) [0|0] "" Vector__XXX
 SG_ VCSEC_centerReverseRawRSSI1 m1 : 16|8@1- (1,0) [0|0] "" Vector__XXX
 SG_ VCSEC_frontLeftReverseRawRSSI1 m5 : 16|8@1- (1,0) [0|0] "" Vector__XXX
 SG_ VCSEC_frontReverseRawRSSI1 m4 : 16|8@1- (1,0) [0|0] "" Vector__XXX
 SG_ VCSEC_leftReverseRawRSSI1 m0 : 16|8@1- (1,0) [0|0] "" Vector__XXX
 SG_ VCSEC_rearLeftReverseRawRSSI1 m2 : 16|8@1- (1,0) [0|0] "" Vector__XXX
 SG_ VCSEC_secondaryReverseRawRSSI1 m3 : 16|8@1- (1,0) [0|0] "" Vector__XXX
 SG_ VCSEC_centerRSSI1Channel m1 : 24|6@1+ (1,0) [0|0] "" Vector__XXX
 SG_ VCSEC_frontLeftRSSI1Channel m5 : 24|6@1+ (1,0) [0|0] "" Vector__XXX
 SG_ VCSEC_frontRSSI1Channel m4 : 24|6@1+ (1,0) [0|0] "" Vector__XXX
 SG_ VCSEC_leftRSSI1Channel m0 : 24|6@1+ (1,0) [0|0] "" Vector__XXX
 SG_ VCSEC_rearLeftRSSI1Channel m2 : 24|6@1+ (1,0) [0|0] "" Vector__XXX
 SG_ VCSEC_secondaryCenterRSSI1Channel m3 : 24|6@1+ (1,0) [0|0] "" Vector__XXX
 SG_ VCSEC_frontRightRawRSSI1 m5 : 32|8@1- (1,0) [0|0] "" Vector__XXX
 SG_ VCSEC_nfcRawRSSI1 m3 : 32|8@1- (1,0) [0|0] "" Vector__XXX
 SG_ VCSEC_rearRawRSSI1 m1 : 32|8@1- (1,0) [0|0] "" Vector__XXX
 SG_ VCSEC_rearRightRawRSSI1 m2 : 32|8@1- (1,0) [0|0] "" Vector__XXX
 SG_ VCSEC_rightRawRSSI1 m0 : 32|8@1- (1,0) [0|0] "" Vector__XXX
 SG_ VCSEC_frontRightReverseRawRSSI1 m5 : 40|8@1- (1,0) [0|0] "" Vector__XXX
 SG_ VCSEC_nfcReverseRawRSSI1 m3 : 40|8@1- (1,0) [0|0] "" Vector__XXX
 SG_ VCSEC_rearReverseRawRSSI1 m1 : 40|8@1- (1,0) [0|0] "" Vector__XXX
 SG_ VCSEC_rearRightReverseRawRSSI1 m2 : 40|8@1- (1,0) [0|0] "" Vector__XXX
 SG_ VCSEC_rightReverseRawRSSI1 m0 : 40|8@1- (1,0) [0|0] "" Vector__XXX
 SG_ VCSEC_frontRightRSSI1Channel m5 : 48|6@1+ (1,0) [0|0] "" Vector__XXX
 SG_ VCSEC_nfcRSSI1Channel m3 : 48|6@1+ (1,0) [0|0] "" Vector__XXX
 SG_ VCSEC_rearRSSI1Channel m1 : 48|6@1+ (1,0) [0|0] "" Vector__XXX
 SG_ VCSEC_rearRightRSSI1Channel m2 : 48|6@1+ (1,0) [0|0] "" Vector__XXX
 SG_ VCSEC_rightRSSI1Channel m0 : 48|6@1+ (1,0) [0|0] "" Vector__XXX

BO_ 1215 VCSEC_rawRSSI2: 8 Vector__XXX
 SG_ VCSEC_rawRSSI2ChannelIndex M : 0|3@1+ (1,0) [0|0] "" Vector__XXX
 SG_ VCSEC_centerRawRSSI2 m1 : 8|8@1- (1,0) [0|0] "" Vector__XXX
 SG_ VCSEC_frontLeftRawRSSI2 m5 : 8|8@1- (1,0) [0|0] "" Vector__XXX
 SG_ VCSEC_frontRawRSSI2 m4 : 8|8@1- (1,0) [0|0] "" Vector__XXX
 SG_ VCSEC_leftRawRSSI2 m0 : 8|8@1- (1,0) [0|0] "" Vector__XXX
 SG_ VCSEC_rearLeftRawRSSI2 m2 : 8|8@1- (1,0) [0|0] "" Vector__XXX
 SG_ VCSEC_secondaryCenterRawRSSI2 m3 : 8|8@1- (1,0) [0|0] "" Vector__XXX
 SG_ VCSEC_centerReverseRawRSSI2 m1 : 16|8@1- (1,0) [0|0] "" Vector__XXX
 SG_ VCSEC_frontLeftReverseRawRSSI2 m5 : 16|8@1- (1,0) [0|0] "" Vector__XXX
 SG_ VCSEC_frontReverseRawRSSI2 m4 : 16|8@1- (1,0) [0|0] "" Vector__XXX
 SG_ VCSEC_leftReverseRawRSSI2 m0 : 16|8@1- (1,0) [0|0] "" Vector__XXX
 SG_ VCSEC_rearLeftReverseRawRSSI2 m2 : 16|8@1- (1,0) [0|0] "" Vector__XXX
 SG_ VCSEC_secondaryReverseRawRSSI2 m3 : 16|8@1- (1,0) [0|0] "" Vector__XXX
 SG_ VCSEC_centerRSSI2Channel m1 : 24|6@1+ (1,0) [0|0] "" Vector__XXX
 SG_ VCSEC_frontLeftRSSI2Channel m5 : 24|6@1+ (1,0) [0|0] "" Vector__XXX
 SG_ VCSEC_frontRSSI2Channel m4 : 24|6@1+ (1,0) [0|0] "" Vector__XXX
 SG_ VCSEC_leftRSSI2Channel m0 : 24|6@1+ (1,0) [0|0] "" Vector__XXX
 SG_ VCSEC_rearLeftRSSI2Channel m2 : 24|6@1+ (1,0) [0|0] "" Vector__XXX
 SG_ VCSEC_secondaryCenterRSSI2Channel m3 : 24|6@1+ (1,0) [0|0] "" Vector__XXX
 SG_ VCSEC_frontRightRawRSSI2 m5 : 32|8@1- (1,0) [0|0] "" Vector__XXX
 SG_ VCSEC_nfcRawRSSI2 m3 : 32|8@1- (1,0) [0|0] "" Vector__XXX
 SG_ VCSEC_rearRawRSSI2 m1 : 32|8@1- (1,0) [0|0] "" Vector__XXX
 SG_ VCSEC_rearRightRawRSSI2 m2 : 32|8@1- (1,0) [0|0] "" Vector__XXX
 SG_ VCSEC_rightRawRSSI2 m0 : 32|8@1- (1,0) [0|0] "" Vector__XXX
 SG_ VCSEC_frontRightReverseRawRSSI2 m5 : 40|8@1- (1,0) [0|0] "" Vector__XXX
 SG_ VCSEC_nfcReverseRawRSSI2 m3 : 40|8@1- (1,0) [0|0] "" Vector__XXX
 SG_ VCSEC_rearReverseRawRSSI2 m1 : 40|8@1- (1,0) [0|0] "" Vector__XXX
 SG_ VCSEC_rearRightReverseRawRSSI2 m2 : 40|8@1- (1,0) [0|0] "" Vector__XXX
 SG_ VCSEC_rightReverseRawRSSI2 m0 : 40|8@1- (1,0) [0|0] "" Vector__XXX
 SG_ VCSEC_frontRightRSSI2Channel m5 : 48|6@1+ (1,0) [0|0] "" Vector__XXX
 SG_ VCSEC_nfcRSSI2Channel m3 : 48|6@1+ (1,0) [0|0] "" Vector__XXX
 SG_ VCSEC_rearRSSI2Channel m1 : 48|6@1+ (1,0) [0|0] "" Vector__XXX
 SG_ VCSEC_rearRightRSSI2Channel m2 : 48|6@1+ (1,0) [0|0] "" Vector__XXX
 SG_ VCSEC_rightRSSI2Channel m0 : 48|6@1+ (1,0) [0|0] "" Vector__XXX

BO_ 1246 DAS_bodyControls3: 8 Vector__XXX
 SG_ DAS_autonomyScheduledDepartureTime : 0|32@1+ (1,0) [0|0] "" Vector__XXX
 SG_ DAS_passengerErgoResetRequest : 48|1@1+ (1,0) [0|0] "" Vector__XXX
 SG_ DAS_driverErgoLockoutRequest : 49|2@1+ (1,0) [0|0] "" Vector__XXX
 SG_ DAS_bodyControls3Counter : 52|4@1+ (1,0) [0|0] "" Vector__XXX
 SG_ DAS_bodyControls3Checksum : 56|8@1+ (1,0) [0|0] "" Vector__XXX

BO_ 1250 VCLEFT_seatStatus: 8 Vector__XXX
 SG_ VCLEFT_seatStatusIndex M : 0|3@1+ (1,0) [0|0] "" Vector__XXX
 SG_ VCLEFT_frontSeatTrackPosOffset m6 : 3|12@1- (1,0) [0|0] "" Vector__XXX
 SG_ VCLEFT_frontSeatTrackPosReal m5 : 3|12@1- (1,0) [0|0] "" Vector__XXX
 SG_ VCLEFT_lumbarAPressurePercentage m7 : 3|7@1+ (1,0) [0|0] "" Vector__XXX
 SG_ VCLEFT_lumbarAState m4 : 3|3@1+ (1,0) [0|0] "" Vector__XXX
 SG_ VC_AH_1RowLeftSeatMovementHealth m0 : 5|3@1+ (1,0) [0|0] "" Vector__XXX
 SG_ VCLEFT_lumbarBState m4 : 6|3@1+ (1,0) [0|0] "" Vector__XXX
 SG_ VCLEFT_frontSeatBackPos m1 : 8|16@1- (1,0) [0|0] "" Vector__XXX
 SG_ VCLEFT_frontSeatLiftPos m2 : 8|16@1- (1,0) [0|0] "" Vector__XXX
 SG_ VCLEFT_frontSeatTiltPos m3 : 8|16@1- (1,0) [0|0] "" Vector__XXX
 SG_ VCLEFT_frontSeatTrackPos m0 : 8|16@1- (1,0) [0|0] "" Vector__XXX
 SG_ VCLEFT_lumbarAPressureHpa m4 : 9|12@1+ (1,0) [0|0] "" Vector__XXX
 SG_ VCLEFT_lumbarBPressurePercentage m7 : 10|7@1+ (1,0) [0|0] "" Vector__XXX
 SG_ VCLEFT_frontSeatBackPosOffset m6 : 16|12@1- (0.1,0) [0|0] "" Vector__XXX
 SG_ VCLEFT_frontSeatBackPosReal m5 : 16|12@1- (0.1,0) [0|0] "" Vector__XXX
 SG_ VCLEFT_lumbarAPressureHpaFilt m4 : 21|10@1+ (1,0) [0|0] "" Vector__XXX
 SG_ VCLEFT_frontSeatBackCurrent m1 : 24|12@1- (0.01,0) [0|0] "" Vector__XXX
 SG_ VCLEFT_frontSeatLiftCurrent m2 : 24|12@1- (0.01,0) [0|0] "" Vector__XXX
 SG_ VCLEFT_frontSeatTiltCurrent m3 : 24|12@1- (0.01,0) [0|0] "" Vector__XXX
 SG_ VCLEFT_frontSeatTrackCurrent m0 : 24|12@1- (0.01,0) [0|0] "" Vector__XXX
 SG_ VCLEFT_frontSeatLiftPosOffset m6 : 28|12@1- (1,0) [0|0] "" Vector__XXX
 SG_ VCLEFT_frontSeatLiftPosReal m5 : 28|12@1- (1,0) [0|0] "" Vector__XXX
 SG_ VCLEFT_lumbarBPressureHpa m4 : 31|12@1+ (1,0) [0|0] "" Vector__XXX
 SG_ VCLEFT_frontSeatBackDuty m1 : 36|12@1- (0.1,0) [0|0] "" Vector__XXX
 SG_ VCLEFT_frontSeatLiftDuty m2 : 36|12@1- (0.1,0) [0|0] "" Vector__XXX
 SG_ VCLEFT_frontSeatTiltDuty m3 : 36|12@1- (0.1,0) [0|0] "" Vector__XXX
 SG_ VCLEFT_frontSeatTrackDuty m0 : 36|12@1- (0.1,0) [0|0] "" Vector__XXX
 SG_ VCLEFT_frontSeatTiltPosOffset m6 : 40|12@1- (0.1,0) [0|0] "" Vector__XXX
 SG_ VCLEFT_frontSeatTiltPosReal m5 : 40|12@1- (0.1,0) [0|0] "" Vector__XXX
 SG_ VCLEFT_lumbarBPressureHpaFilt m4 : 43|10@1+ (1,0) [0|0] "" Vector__XXX
 SG_ VCLEFT_frontSeatBackState m1 : 48|3@1+ (1,0) [0|0] "" Vector__XXX
 SG_ VCLEFT_frontSeatLiftState m2 : 48|3@1+ (1,0) [0|0] "" Vector__XXX
 SG_ VCLEFT_frontSeatTiltState m3 : 48|3@1+ (1,0) [0|0] "" Vector__XXX
 SG_ VCLEFT_frontSeatTrackState m0 : 48|3@1+ (1,0) [0|0] "" Vector__XXX
 SG_ VCLEFT_frontSeatBackCalibrated m1 : 51|1@1+ (1,0) [0|0] "" Vector__XXX
 SG_ VCLEFT_frontSeatLiftCalibrated m2 : 51|1@1+ (1,0) [0|0] "" Vector__XXX
 SG_ VCLEFT_frontSeatTiltCalibrated m3 : 51|1@1+ (1,0) [0|0] "" Vector__XXX
 SG_ VCLEFT_frontSeatTrackCalibrated m0 : 51|1@1+ (1,0) [0|0] "" Vector__XXX
 SG_ VCLEFT_frontSeatBackLog m1 : 52|1@1+ (1,0) [0|0] "" Vector__XXX
 SG_ VCLEFT_frontSeatLiftLog m2 : 52|1@1+ (1,0) [0|0] "" Vector__XXX
 SG_ VCLEFT_frontSeatTiltLog m3 : 52|1@1+ (1,0) [0|0] "" Vector__XXX
 SG_ VCLEFT_frontSeatTrackLog m0 : 52|1@1+ (1,0) [0|0] "" Vector__XXX
 SG_ VCLEFT_frontSeatBackBridgeSt m1 : 53|2@1+ (1,0) [0|0] "" Vector__XXX
 SG_ VCLEFT_frontSeatLiftBridgeSt m2 : 53|2@1+ (1,0) [0|0] "" Vector__XXX
 SG_ VCLEFT_frontSeatTiltBridgeSt m3 : 53|2@1+ (1,0) [0|0] "" Vector__XXX
 SG_ VCLEFT_frontSeatTrackBridgeSt m0 : 53|2@1+ (1,0) [0|0] "" Vector__XXX
 SG_ VCLEFT_lumbarActiveTooLongErr m4 : 53|1@1+ (1,0) [0|0] "" Vector__XXX
 SG_ VCLEFT_lumbarMaxPErr m4 : 54|1@1+ (1,0) [0|0] "" Vector__XXX
 SG_ VCLEFT_frontSeatBackPercentage m1 : 55|7@1+ (1,0) [0|0] "" Vector__XXX
 SG_ VCLEFT_frontSeatLiftPercentage m2 : 55|7@1+ (1,0) [0|0] "" Vector__XXX
 SG_ VCLEFT_frontSeatTiltPercentage m3 : 55|7@1+ (1,0) [0|0] "" Vector__XXX
 SG_ VCLEFT_frontSeatTrackPercentage m0 : 55|7@1+ (1,0) [0|0] "" Vector__XXX
 SG_ VCLEFT_lumbarOvercurrentErr m4 : 55|1@1+ (1,0) [0|0] "" Vector__XXX
 SG_ VCLEFT_lumbarMaxOperatingPErr m4 : 56|1@1+ (1,0) [0|0] "" Vector__XXX
 SG_ VCLEFT_lumbarMinPErr m4 : 57|1@1+ (1,0) [0|0] "" Vector__XXX
 SG_ VCLEFT_lumbarGeneralErr m4 : 58|1@1+ (1,0) [0|0] "" Vector__XXX
 SG_ VCLEFT_lumbarDevMaxPumpPressA m4 : 59|1@1+ (1,0) [0|0] "" Vector__XXX
 SG_ VCLEFT_lumbarDevMaxPumpPressB m4 : 60|1@1+ (1,0) [0|0] "" Vector__XXX

BO_ 1251 VCRIGHT_seatStatus: 8 Vector__XXX
 SG_ VCRIGHT_seatStatusIndex M : 0|3@1+ (1,0) [0|0] "" Vector__XXX
 SG_ VCRIGHT_frontSeatTrackPosOffset m6 : 3|12@1- (1,0) [0|0] "" Vector__XXX
 SG_ VCRIGHT_frontSeatTrackPosReal m5 : 3|12@1- (1,0) [0|0] "" Vector__XXX
 SG_ VCRIGHT_lumbarAPressurePercentage m7 : 3|7@1+ (1,0) [0|0] "" Vector__XXX
 SG_ VCRIGHT_lumbarAState m4 : 3|3@1+ (1,0) [0|0] "" Vector__XXX
 SG_ VC_AH_1RowRightSeatMovementHealth m0 : 5|3@1+ (1,0) [0|0] "" Vector__XXX
 SG_ VCRIGHT_lumbarBState m4 : 6|3@1+ (1,0) [0|0] "" Vector__XXX
 SG_ VCRIGHT_frontSeatBackPos m1 : 8|16@1- (1,0) [0|0] "" Vector__XXX
 SG_ VCRIGHT_frontSeatLiftPos m2 : 8|16@1- (1,0) [0|0] "" Vector__XXX
 SG_ VCRIGHT_frontSeatTiltPos m3 : 8|16@1- (1,0) [0|0] "" Vector__XXX
 SG_ VCRIGHT_frontSeatTrackPos m0 : 8|16@1- (1,0) [0|0] "" Vector__XXX
 SG_ VCRIGHT_lumbarAPressureHpa m4 : 9|12@1+ (1,0) [0|0] "" Vector__XXX
 SG_ VCRIGHT_lumbarBPressurePercentage m7 : 10|7@1+ (1,0) [0|0] "" Vector__XXX
 SG_ VCRIGHT_frontSeatBackPosOffset m6 : 16|12@1- (0.1,0) [0|0] "" Vector__XXX
 SG_ VCRIGHT_frontSeatBackPosReal m5 : 16|12@1- (0.1,0) [0|0] "" Vector__XXX
 SG_ VCRIGHT_lumbarAPressureHpaFilt m4 : 21|10@1+ (1,0) [0|0] "" Vector__XXX
 SG_ VCRIGHT_frontSeatBackCurrent m1 : 24|12@1- (0.01,0) [0|0] "" Vector__XXX
 SG_ VCRIGHT_frontSeatLiftCurrent m2 : 24|12@1- (0.01,0) [0|0] "" Vector__XXX
 SG_ VCRIGHT_frontSeatTiltCurrent m3 : 24|12@1- (0.01,0) [0|0] "" Vector__XXX
 SG_ VCRIGHT_frontSeatTrackCurrent m0 : 24|12@1- (0.01,0) [0|0] "" Vector__XXX
 SG_ VCRIGHT_frontSeatLiftPosOffset m6 : 28|12@1- (1,0) [0|0] "" Vector__XXX
 SG_ VCRIGHT_frontSeatLiftPosReal m5 : 28|12@1- (1,0) [0|0] "" Vector__XXX
 SG_ VCRIGHT_lumbarBPressureHpa m4 : 31|12@1+ (1,0) [0|0] "" Vector__XXX
 SG_ VCRIGHT_frontSeatBackDuty m1 : 36|12@1- (0.1,0) [0|0] "" Vector__XXX
 SG_ VCRIGHT_frontSeatLiftDuty m2 : 36|12@1- (0.1,0) [0|0] "" Vector__XXX
 SG_ VCRIGHT_frontSeatTiltDuty m3 : 36|12@1- (0.1,0) [0|0] "" Vector__XXX
 SG_ VCRIGHT_frontSeatTrackDuty m0 : 36|12@1- (0.1,0) [0|0] "" Vector__XXX
 SG_ VCRIGHT_frontSeatTiltPosOffset m6 : 40|12@1- (0.1,0) [0|0] "" Vector__XXX
 SG_ VCRIGHT_frontSeatTiltPosReal m5 : 40|12@1- (0.1,0) [0|0] "" Vector__XXX
 SG_ VCRIGHT_lumbarBPressureHpaFilt m4 : 43|10@1+ (1,0) [0|0] "" Vector__XXX
 SG_ VCRIGHT_frontSeatBackState m1 : 48|3@1+ (1,0) [0|0] "" Vector__XXX
 SG_ VCRIGHT_frontSeatLiftState m2 : 48|3@1+ (1,0) [0|0] "" Vector__XXX
 SG_ VCRIGHT_frontSeatTiltState m3 : 48|3@1+ (1,0) [0|0] "" Vector__XXX
 SG_ VCRIGHT_frontSeatTrackState m0 : 48|3@1+ (1,0) [0|0] "" Vector__XXX
 SG_ VCRIGHT_frontSeatBackCalibrated m1 : 51|1@1+ (1,0) [0|0] "" Vector__XXX
 SG_ VCRIGHT_frontSeatLiftCalibrated m2 : 51|1@1+ (1,0) [0|0] "" Vector__XXX
 SG_ VCRIGHT_frontSeatTiltCalibrated m3 : 51|1@1+ (1,0) [0|0] "" Vector__XXX
 SG_ VCRIGHT_frontSeatTrackCalibrated m0 : 51|1@1+ (1,0) [0|0] "" Vector__XXX
 SG_ VCRIGHT_frontSeatBackLog m1 : 52|1@1+ (1,0) [0|0] "" Vector__XXX
 SG_ VCRIGHT_frontSeatLiftLog m2 : 52|1@1+ (1,0) [0|0] "" Vector__XXX
 SG_ VCRIGHT_frontSeatTiltLog m3 : 52|1@1+ (1,0) [0|0] "" Vector__XXX
 SG_ VCRIGHT_frontSeatTrackLog m0 : 52|1@1+ (1,0) [0|0] "" Vector__XXX
 SG_ VCRIGHT_frontSeatBackBridgeSt m1 : 53|2@1+ (1,0) [0|0] "" Vector__XXX
 SG_ VCRIGHT_frontSeatLiftBridgeSt m2 : 53|2@1+ (1,0) [0|0] "" Vector__XXX
 SG_ VCRIGHT_frontSeatTiltBridgeSt m3 : 53|2@1+ (1,0) [0|0] "" Vector__XXX
 SG_ VCRIGHT_frontSeatTrackBridgeSt m0 : 53|2@1+ (1,0) [0|0] "" Vector__XXX
 SG_ VCRIGHT_lumbarActiveTooLongErr m4 : 53|1@1+ (1,0) [0|0] "" Vector__XXX
 SG_ VCRIGHT_lumbarMaxPErr m4 : 54|1@1+ (1,0) [0|0] "" Vector__XXX
 SG_ VCRIGHT_frontSeatBackPercentage m1 : 55|7@1+ (1,0) [0|0] "" Vector__XXX
 SG_ VCRIGHT_frontSeatLiftPercentage m2 : 55|7@1+ (1,0) [0|0] "" Vector__XXX
 SG_ VCRIGHT_frontSeatTiltPercentage m3 : 55|7@1+ (1,0) [0|0] "" Vector__XXX
 SG_ VCRIGHT_frontSeatTrackPercentage m0 : 55|7@1+ (1,0) [0|0] "" Vector__XXX
 SG_ VCRIGHT_lumbarOvercurrentErr m4 : 55|1@1+ (1,0) [0|0] "" Vector__XXX
 SG_ VCRIGHT_lumbarMaxOperatingPErr m4 : 56|1@1+ (1,0) [0|0] "" Vector__XXX
 SG_ VCRIGHT_lumbarMinPErr m4 : 57|1@1+ (1,0) [0|0] "" Vector__XXX
 SG_ VCRIGHT_lumbarGeneralErr m4 : 58|1@1+ (1,0) [0|0] "" Vector__XXX
 SG_ VCRIGHT_lumbarDevMaxPumpPressA m4 : 59|1@1+ (1,0) [0|0] "" Vector__XXX
 SG_ VCRIGHT_lumbarDevMaxPumpPressB m4 : 60|1@1+ (1,0) [0|0] "" Vector__XXX

BO_ 1267 UI_frontSeatRequests: 8 Vector__XXX
 SG_ UI_frontRightSeatTrackForward : 0|1@1+ (1,0) [0|0] "" Vector__XXX
 SG_ UI_frontRightSeatTrackBack : 1|1@1+ (1,0) [0|0] "" Vector__XXX
 SG_ UI_frontLeftSeatTrackForward : 2|1@1+ (1,0) [0|0] "" Vector__XXX
 SG_ UI_frontLeftSeatTrackBack : 3|1@1+ (1,0) [0|0] "" Vector__XXX
 SG_ UI_frontRightSeatBackrestBack : 4|1@1+ (1,0) [0|0] "" Vector__XXX
 SG_ UI_frontRightSeatBackrestForward : 5|1@1+ (1,0) [0|0] "" Vector__XXX
 SG_ UI_frontLeftSeatBackrestBack : 6|1@1+ (1,0) [0|0] "" Vector__XXX
 SG_ UI_frontLeftSeatBackrestForward : 7|1@1+ (1,0) [0|0] "" Vector__XXX
 SG_ UI_frontRightSeatTiltUp : 8|1@1+ (1,0) [0|0] "" Vector__XXX
 SG_ UI_frontRightSeatTiltDown : 9|1@1+ (1,0) [0|0] "" Vector__XXX
 SG_ UI_frontLeftSeatTiltUp : 10|1@1+ (1,0) [0|0] "" Vector__XXX
 SG_ UI_frontLeftSeatTiltDown : 11|1@1+ (1,0) [0|0] "" Vector__XXX
 SG_ UI_frontRightSeatLiftUp : 12|1@1+ (1,0) [0|0] "" Vector__XXX
 SG_ UI_frontRightSeatLiftDown : 13|1@1+ (1,0) [0|0] "" Vector__XXX
 SG_ UI_frontLeftSeatLiftUp : 14|1@1+ (1,0) [0|0] "" Vector__XXX
 SG_ UI_frontLeftSeatLiftDown : 15|1@1+ (1,0) [0|0] "" Vector__XXX
 SG_ UI_frontLeftSeatLumbarUp : 16|1@1+ (1,0) [0|0] "" Vector__XXX
 SG_ UI_frontLeftSeatLumbarDown : 17|1@1+ (1,0) [0|0] "" Vector__XXX
 SG_ UI_frontRightSeatLumbarUp : 18|1@1+ (1,0) [0|0] "" Vector__XXX
 SG_ UI_frontRightSeatLumbarDown : 19|1@1+ (1,0) [0|0] "" Vector__XXX
 SG_ UI_frontLeftSeatLumbarIn : 20|1@1+ (1,0) [0|0] "" Vector__XXX
 SG_ UI_frontLeftSeatLumbarOut : 21|1@1+ (1,0) [0|0] "" Vector__XXX
 SG_ UI_frontRightSeatLumbarIn : 22|1@1+ (1,0) [0|0] "" Vector__XXX
 SG_ UI_frontRightSeatLumbarOut : 23|1@1+ (1,0) [0|0] "" Vector__XXX
 SG_ UI_seatAdjustmentSource : 24|3@1+ (1,0) [0|0] "" Vector__XXX

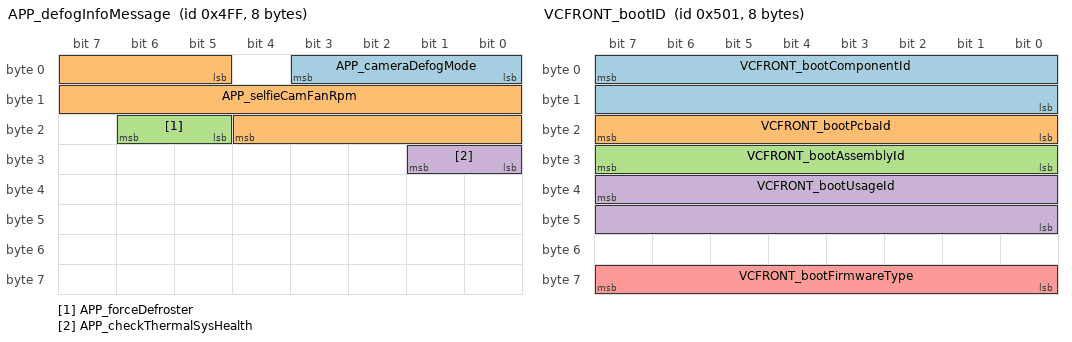
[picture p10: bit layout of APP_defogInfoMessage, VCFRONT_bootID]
BO_ 1279 APP_defogInfoMessage: 8 Vector__XXX
 SG_ APP_cameraDefogMode : 0|4@1+ (1,0) [0|0] "" Vector__XXX
 SG_ APP_selfieCamFanRpm : 5|16@1+ (1,0) [0|0] "" Vector__XXX
 SG_ APP_forceDefroster : 21|2@1+ (1,0) [0|0] "" Vector__XXX
 SG_ APP_checkThermalSysHealth : 24|2@1+ (1,0) [0|0] "" Vector__XXX

BO_ 1280 UI_debugECU: 8 Vector__XXX
 SG_ UI_debugEcuTarget M : 0|5@1+ (1,0) [0|0] "" Vector__XXX
 SG_ UI_VCFRONT_debugEnable m7 : 5|1@1+ (1,0) [0|0] "" Vector__XXX
 SG_ UI_BMS_debugAllEnable m5 : 8|1@1+ (1,0) [0|0] "" Vector__XXX
 SG_ UI_DIF_debugEnable m8 : 8|1@1+ (1,0) [0|0] "" Vector__XXX
 SG_ UI_DIR_debugEnable m9 : 8|1@1+ (1,0) [0|0] "" Vector__XXX
 SG_ UI_DIS_debugEnable m2 : 8|1@1+ (1,0) [0|0] "" Vector__XXX
 SG_ UI_DI_debugEnable m1 : 8|1@1+ (1,0) [0|0] "" Vector__XXX
 SG_ UI_PMF_debugEnable m10 : 8|1@1+ (1,0) [0|0] "" Vector__XXX
 SG_ UI_PMR_debugEnable m11 : 8|1@1+ (1,0) [0|0] "" Vector__XXX
 SG_ UI_PMS_debugEnable m4 : 8|1@1+ (1,0) [0|0] "" Vector__XXX
 SG_ UI_PM_debugEnable m3 : 8|1@1+ (1,0) [0|0] "" Vector__XXX
 SG_ UI_VCRIGHT_debugEnable m6 : 8|1@1+ (1,0) [0|0] "" Vector__XXX
 SG_ UI_BMS_debugDisable m5 : 9|1@1+ (1,0) [0|0] "" Vector__XXX
 SG_ UI_PMS_debugAt100Hz m4 : 9|1@1+ (1,0) [0|0] "" Vector__XXX
 SG_ UI_PM_debugAt100Hz m3 : 9|1@1+ (1,0) [0|0] "" Vector__XXX

BO_ 1281 VCFRONT_bootID: 8 Vector__XXX
 SG_ VCFRONT_bootComponentId : 7|16@0+ (1,0) [0|0] "" Vector__XXX
 SG_ VCFRONT_bootPcbaId : 23|8@0+ (1,0) [0|0] "" Vector__XXX
 SG_ VCFRONT_bootAssemblyId : 31|8@0+ (1,0) [0|0] "" Vector__XXX
 SG_ VCFRONT_bootUsageId : 39|16@0+ (1,0) [0|0] "" Vector__XXX
 SG_ VCFRONT_bootFirmwareType : 63|8@0+ (1,0) [0|0] "" Vector__XXX

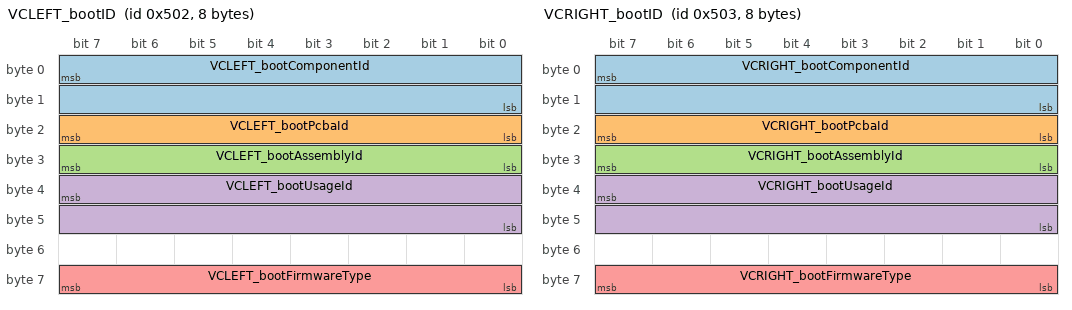
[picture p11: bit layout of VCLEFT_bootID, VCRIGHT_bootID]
BO_ 1282 VCLEFT_bootID: 8 Vector__XXX
 SG_ VCLEFT_bootComponentId : 7|16@0+ (1,0) [0|0] "" Vector__XXX
 SG_ VCLEFT_bootPcbaId : 23|8@0+ (1,0) [0|0] "" Vector__XXX
 SG_ VCLEFT_bootAssemblyId : 31|8@0+ (1,0) [0|0] "" Vector__XXX
 SG_ VCLEFT_bootUsageId : 39|16@0+ (1,0) [0|0] "" Vector__XXX
 SG_ VCLEFT_bootFirmwareType : 63|8@0+ (1,0) [0|0] "" Vector__XXX

BO_ 1283 VCRIGHT_bootID: 8 Vector__XXX
 SG_ VCRIGHT_bootComponentId : 7|16@0+ (1,0) [0|0] "" Vector__XXX
 SG_ VCRIGHT_bootPcbaId : 23|8@0+ (1,0) [0|0] "" Vector__XXX
 SG_ VCRIGHT_bootAssemblyId : 31|8@0+ (1,0) [0|0] "" Vector__XXX
 SG_ VCRIGHT_bootUsageId : 39|16@0+ (1,0) [0|0] "" Vector__XXX
 SG_ VCRIGHT_bootFirmwareType : 63|8@0+ (1,0) [0|0] "" Vector__XXX

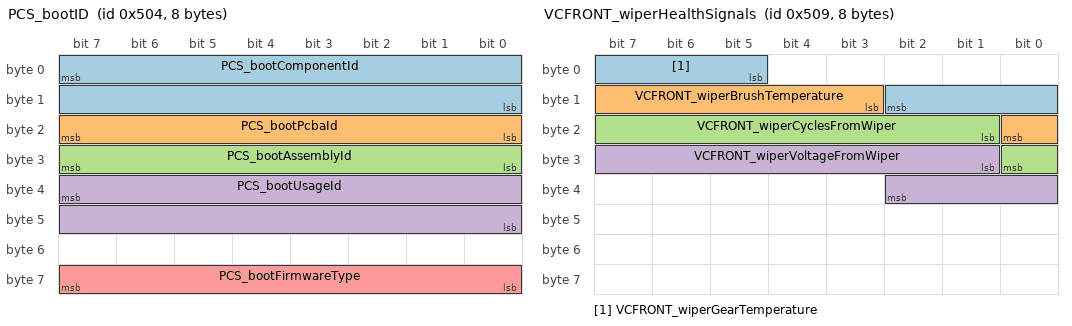
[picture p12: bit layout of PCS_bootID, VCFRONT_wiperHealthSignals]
BO_ 1284 PCS_bootID: 8 Vector__XXX
 SG_ PCS_bootComponentId : 7|16@0+ (1,0) [0|0] "" Vector__XXX
 SG_ PCS_bootPcbaId : 23|8@0+ (1,0) [0|0] "" Vector__XXX
 SG_ PCS_bootAssemblyId : 31|8@0+ (1,0) [0|0] "" Vector__XXX
 SG_ PCS_bootUsageId : 39|16@0+ (1,0) [0|0] "" Vector__XXX
 SG_ PCS_bootFirmwareType : 63|8@0+ (1,0) [0|0] "" Vector__XXX

BO_ 1285 UMC_smartAdapterInfo: 8 Vector__XXX
 SG_ SA_infoIndex M : 0|8@1+ (1,0) [0|0] "" Vector__XXX
 SG_ SA_genealogyVersion m0 : 8|8@1+ (1,0) [0|0] "" Vector__XXX
 SG_ SA_partNumChar01 m25 : 8|8@1+ (1,0) [0|0] "" Vector__XXX
 SG_ SA_partNumChar08 m26 : 8|8@1+ (1,0) [0|0] "" Vector__XXX
 SG_ SA_partNumChar15 m27 : 8|8@1+ (1,0) [0|0] "" Vector__XXX
 SG_ SA_partNumInt m31 : 8|32@1+ (1,0) [0|0] "" Vector__XXX
 SG_ SA_serialNumChar01 m29 : 8|8@1+ (1,0) [0|0] "" Vector__XXX
 SG_ SA_serialNumChar08 m30 : 8|8@1+ (1,0) [0|0] "" Vector__XXX
 SG_ SA_serialNumInt m32 : 8|40@1+ (1,0) [0|0] "" Vector__XXX
 SG_ SA_genealogyCrc m0 : 16|32@1+ (1,0) [0|0] "" Vector__XXX
 SG_ SA_partNumChar02 m25 : 16|8@1+ (1,0) [0|0] "" Vector__XXX
 SG_ SA_partNumChar09 m26 : 16|8@1+ (1,0) [0|0] "" Vector__XXX
 SG_ SA_partNumChar16 m27 : 16|8@1+ (1,0) [0|0] "" Vector__XXX
 SG_ SA_serialNumChar02 m29 : 16|8@1+ (1,0) [0|0] "" Vector__XXX
 SG_ SA_serialNumChar09 m30 : 16|8@1+ (1,0) [0|0] "" Vector__XXX
 SG_ SA_AssemblyID m11 : 24|8@1+ (1,0) [0|0] "" Vector__XXX
 SG_ SA_partNumChar03 m25 : 24|8@1+ (1,0) [0|0] "" Vector__XXX
 SG_ SA_partNumChar10 m26 : 24|8@1+ (1,0) [0|0] "" Vector__XXX
 SG_ SA_partNumChar17 m27 : 24|8@1+ (1,0) [0|0] "" Vector__XXX
 SG_ SA_serialNumChar03 m29 : 24|8@1+ (1,0) [0|0] "" Vector__XXX
 SG_ SA_serialNumChar10 m30 : 24|8@1+ (1,0) [0|0] "" Vector__XXX
 SG_ SA_UsageID m11 : 32|16@1+ (1,0) [0|0] "" Vector__XXX
 SG_ SA_partNumChar04 m25 : 32|8@1+ (1,0) [0|0] "" Vector__XXX
 SG_ SA_partNumChar11 m26 : 32|8@1+ (1,0) [0|0] "" Vector__XXX
 SG_ SA_partNumChar18 m27 : 32|8@1+ (1,0) [0|0] "" Vector__XXX
 SG_ SA_serialNumChar04 m29 : 32|8@1+ (1,0) [0|0] "" Vector__XXX
 SG_ SA_serialNumChar11 m30 : 32|8@1+ (1,0) [0|0] "" Vector__XXX
 SG_ SA_partNumChar05 m25 : 40|8@1+ (1,0) [0|0] "" Vector__XXX
 SG_ SA_partNumChar12 m26 : 40|8@1+ (1,0) [0|0] "" Vector__XXX
 SG_ SA_partNumChar19 m27 : 40|8@1+ (1,0) [0|0] "" Vector__XXX
 SG_ SA_partNumRev m31 : 40|8@1+ (1,0) [0|0] "" Vector__XXX
 SG_ SA_serialNumChar05 m29 : 40|8@1+ (1,0) [0|0] "" Vector__XXX
 SG_ SA_serialNumChar12 m30 : 40|8@1+ (1,0) [0|0] "" Vector__XXX
 SG_ SA_SubUsageID m11 : 48|16@1+ (1,0) [0|0] "" Vector__XXX
 SG_ SA_currentLimit m31 : 48|8@1+ (1,0) [0|0] "" Vector__XXX
 SG_ SA_partNumChar06 m25 : 48|8@1+ (1,0) [0|0] "" Vector__XXX
 SG_ SA_partNumChar13 m26 : 48|8@1+ (1,0) [0|0] "" Vector__XXX
 SG_ SA_partNumChar20 m27 : 48|8@1+ (1,0) [0|0] "" Vector__XXX
 SG_ SA_region m0 : 48|4@1+ (1,0) [0|0] "" Vector__XXX
 SG_ SA_serialNumChar06 m29 : 48|8@1+ (1,0) [0|0] "" Vector__XXX
 SG_ SA_serialNumChar13 m30 : 48|8@1+ (1,0) [0|0] "" Vector__XXX
 SG_ SA_type m32 : 48|8@1+ (1,0) [0|0] "" Vector__XXX
 SG_ SA_OverTempThreshold m0 : 56|8@1+ (1,0) [0|0] "" Vector__XXX
 SG_ SA_l1Voltage m31 : 56|8@1+ (1,0) [0|0] "" Vector__XXX
 SG_ SA_nominalFrequency m32 : 56|8@1+ (1,0) [0|0] "" Vector__XXX
 SG_ SA_partNumChar07 m25 : 56|8@1+ (1,0) [0|0] "" Vector__XXX
 SG_ SA_partNumChar14 m26 : 56|8@1+ (1,0) [0|0] "" Vector__XXX
 SG_ SA_serialNumChar07 m29 : 56|8@1+ (1,0) [0|0] "" Vector__XXX
 SG_ SA_serialNumChar14 m30 : 56|8@1+ (1,0) [0|0] "" Vector__XXX

BO_ 1289 VCFRONT_wiperHealthSignals: 8 Vector__XXX
 SG_ VCFRONT_wiperGearTemperature : 5|6@1+ (1,40) [0|0] "" Vector__XXX
 SG_ VCFRONT_wiperBrushTemperature : 11|6@1+ (1.6,100) [0|0] "" Vector__XXX
 SG_ VCFRONT_wiperCyclesFromWiper : 17|8@1+ (6000,0) [0|0] "" Vector__XXX
 SG_ VCFRONT_wiperVoltageFromWiper : 25|10@1+ (0.01,8) [0|0] "" Vector__XXX

BO_ 1290 HVP_alertLog: 8 Vector__XXX
 SG_ HVP_alertID M : 0|7@1+ (1,0) [0|0] "" Vector__XXX
 SG_ HVP_alertSet : 15|1@1+ (1,0) [0|0] "" Vector__XXX
 SG_ HVP_a000_alertDataW0 m0 : 16|16@1+ (1,0) [0|0] "" Vector__XXX
 SG_ HVP_a003_programCounter m3 : 16|32@1+ (1,0) [0|0] "" Vector__XXX
 SG_ HVP_a005_current m5 : 16|24@1- (0.001,0) [0|0] "" Vector__XXX
 SG_ HVP_a006_current m6 : 16|24@1- (0.001,0) [0|0] "" Vector__XXX
 SG_ HVP_a007_current m7 : 16|24@1- (0.001,0) [0|0] "" Vector__XXX
 SG_ HVP_a008_temperature m8 : 16|16@1- (0.01,0) [0|0] "" Vector__XXX
 SG_ HVP_a009_brickVoltage m9 : 16|16@1- (0.001,0) [0|0] "" Vector__XXX
 SG_ HVP_a010_brickVoltage m10 : 16|16@1- (0.001,0) [0|0] "" Vector__XXX
 SG_ HVP_a012_breakLocationA m12 : 16|5@1+ (1,0) [0|0] "" Vector__XXX
 SG_ HVP_a013_breakLocationA m13 : 16|5@1+ (1,0) [0|0] "" Vector__XXX
 SG_ HVP_a018_dcLinkVoltage m18 : 16|16@1+ (0.01,0) [0|0] "" Vector__XXX
 SG_ HVP_a020_energyReserveV m20 : 16|16@1+ (0.001,0) [0|0] "" Vector__XXX
 SG_ HVP_a021_pyroStatus m21 : 16|2@1+ (1,0) [0|0] "" Vector__XXX
 SG_ HVP_a022_pyroStatus m22 : 16|2@1+ (1,0) [0|0] "" Vector__XXX
 SG_ HVP_a023_bmbDeviceMask m23 : 16|16@1+ (1,0) [0|0] "" Vector__XXX
 SG_ HVP_a024_voltage m24 : 16|16@1+ (0.1,0) [0|0] "" Vector__XXX
 SG_ HVP_a025_voltage1 m25 : 16|16@1+ (0.1,0) [0|0] "" Vector__XXX
 SG_ HVP_a026_hvilStatus m26 : 16|4@1+ (1,0) [0|0] "" Vector__XXX
 SG_ HVP_a028_packVoltage m28 : 16|16@1+ (0.1,0) [0|0] "" Vector__XXX
 SG_ HVP_a030_packPositiveLinkV m30 : 16|16@1- (0.1,0) [0|0] "" Vector__XXX
 SG_ HVP_a031_packNegativeLinkV m31 : 16|16@1- (0.1,0) [0|0] "" Vector__XXX
 SG_ HVP_a033_contactorPowerV m33 : 16|16@1+ (0.1,0) [0|0] "" Vector__XXX
 SG_ HVP_a035_contactorPowerV m35 : 16|16@1+ (0.1,0) [0|0] "" Vector__XXX
 SG_ HVP_a036_pyroFiringHandle m36 : 16|4@1+ (1,0) [0|0] "" Vector__XXX
 SG_ HVP_a037_pyroFiringHandle m37 : 16|4@1+ (1,0) [0|0] "" Vector__XXX
 SG_ HVP_a039_posContactorFailed m39 : 16|1@1+ (1,0) [0|0] "" Vector__XXX
 SG_ HVP_a040_powerVoltage m40 : 16|8@1+ (0.1,0) [0|0] "" Vector__XXX
 SG_ HVP_a041_overCurrent m41 : 16|1@1+ (1,0) [0|0] "" Vector__XXX
 SG_ HVP_a042_overCurrent m42 : 16|1@1+ (1,0) [0|0] "" Vector__XXX
 SG_ HVP_a043_overCurrent m43 : 16|1@1+ (1,0) [0|0] "" Vector__XXX
 SG_ HVP_a044_overCurrent m44 : 16|1@1+ (1,0) [0|0] "" Vector__XXX
 SG_ HVP_a045_dcLinkVoltage m45 : 16|16@1+ (0.1,0) [0|0] "" Vector__XXX
 SG_ HVP_a046_shuntCurrent m46 : 16|16@1- (0.1,0) [0|0] "" Vector__XXX
 SG_ HVP_a047_shuntCurrent m47 : 16|16@1- (0.1,0) [0|0] "" Vector__XXX
 SG_ HVP_a049_contactorPowerV m49 : 16|16@1+ (0.1,0) [0|0] "" Vector__XXX
 SG_ HVP_a050_contactorPowerV m50 : 16|16@1+ (0.1,0) [0|0] "" Vector__XXX
 SG_ HVP_a051_shuntTemperature m51 : 16|16@1- (0.01,0) [0|0] "" Vector__XXX
 SG_ HVP_a052_bmbDeviceMask m52 : 16|16@1+ (1,0) [0|0] "" Vector__XXX
 SG_ HVP_a053_packVoltage m53 : 16|16@1+ (0.01,0) [0|0] "" Vector__XXX
 SG_ HVP_a056_diagnosis m56 : 16|2@1+ (1,0) [0|0] "" Vector__XXX
 SG_ HVP_a057_bmbDiagnosticsType m57 : 16|2@1+ (1,0) [0|0] "" Vector__XXX
 SG_ HVP_a058_VrefSample m58 : 16|16@1+ (0.0001,0) [0|0] "" Vector__XXX
 SG_ HVP_a059_VrefSample m59 : 16|16@1+ (0.0001,0) [0|0] "" Vector__XXX
 SG_ HVP_a060_stackVoltage m60 : 16|16@1+ (0.00128,0) [0|0] "" Vector__XXX
 SG_ HVP_a061_shuntCurrent m61 : 16|16@1- (0.1,0) [0|0] "" Vector__XXX
 SG_ HVP_a062_bmbDeviceMask m62 : 16|16@1+ (1,0) [0|0] "" Vector__XXX
 SG_ HVP_a063_primaryBrickVoltage m63 : 16|16@1+ (0.0001,0) [0|0] "" Vector__XXX
 SG_ HVP_a064_primaryAuxVoltage m64 : 16|16@1+ (0.0001,0) [0|0] "" Vector__XXX
 SG_ HVP_a067_hvilTypeFromHvp m67 : 16|2@1+ (1,0) [0|0] "" Vector__XXX
 SG_ HVP_a068_shuntTemperature m68 : 16|16@1- (0.01,0) [0|0] "" Vector__XXX
 SG_ HVP_a069_numFramesDropped m69 : 16|16@1+ (1,0) [0|0] "" Vector__XXX
 SG_ HVP_a070_numFramesDropped m70 : 16|16@1+ (1,0) [0|0] "" Vector__XXX
 SG_ HVP_a071_passivePyroReferenceVoltage m71 : 16|16@1- (0.001,0) [0|0] "" Vector__XXX
 SG_ HVP_a039_negContactorFailed m39 : 17|1@1+ (1,0) [0|0] "" Vector__XXX
 SG_ HVP_a041_overChargeCurrent m41 : 17|1@1+ (1,0) [0|0] "" Vector__XXX
 SG_ HVP_a042_overChargeCurrent m42 : 17|1@1+ (1,0) [0|0] "" Vector__XXX
 SG_ HVP_a043_overChargeCurrent m43 : 17|1@1+ (1,0) [0|0] "" Vector__XXX
 SG_ HVP_a044_overChargeCurrent m44 : 17|1@1+ (1,0) [0|0] "" Vector__XXX
 SG_ HVP_a021_ErTestFailed m21 : 18|1@1+ (1,0) [0|0] "" Vector__XXX
 SG_ HVP_a022_PyroLeakTestFailed m22 : 18|1@1+ (1,0) [0|0] "" Vector__XXX
 SG_ HVP_a041_overDischargeCurrent m41 : 18|1@1+ (1,0) [0|0] "" Vector__XXX
 SG_ HVP_a042_overDischargeCurrent m42 : 18|1@1+ (1,0) [0|0] "" Vector__XXX
 SG_ HVP_a043_overDischargeCurrent m43 : 18|1@1+ (1,0) [0|0] "" Vector__XXX
 SG_ HVP_a044_overDischargeCurrent m44 : 18|1@1+ (1,0) [0|0] "" Vector__XXX
 SG_ HVP_a057_bmbDeviceId m57 : 18|4@1+ (1,1) [0|0] "" Vector__XXX
 SG_ HVP_a067_hvilTypeFromGateway m67 : 18|2@1+ (1,0) [0|0] "" Vector__XXX
 SG_ HVP_a021_HighSideSwitchTestFailed m21 : 19|1@1+ (1,0) [0|0] "" Vector__XXX
 SG_ HVP_a022_OneShotSequence m22 : 19|1@1+ (1,0) [0|0] "" Vector__XXX
 SG_ HVP_a041_overVoltage m41 : 19|1@1+ (1,0) [0|0] "" Vector__XXX
 SG_ HVP_a042_overVoltage m42 : 19|1@1+ (1,0) [0|0] "" Vector__XXX
 SG_ HVP_a043_overVoltage m43 : 19|1@1+ (1,0) [0|0] "" Vector__XXX
 SG_ HVP_a044_overVoltage m44 : 19|1@1+ (1,0) [0|0] "" Vector__XXX
 SG_ HVP_a021_LowSideSwitchTestFailed m21 : 20|1@1+ (1,0) [0|0] "" Vector__XXX
 SG_ HVP_a022_HighSide m22 : 20|1@1+ (1,0) [0|0] "" Vector__XXX
 SG_ HVP_a041_overTemperature m41 : 20|1@1+ (1,0) [0|0] "" Vector__XXX
 SG_ HVP_a042_overTemperature m42 : 20|1@1+ (1,0) [0|0] "" Vector__XXX
 SG_ HVP_a043_overTemperature m43 : 20|1@1+ (1,0) [0|0] "" Vector__XXX
 SG_ HVP_a044_overTemperature m44 : 20|1@1+ (1,0) [0|0] "" Vector__XXX
 SG_ HVP_a067_hvilTypeIsFromCal m67 : 20|1@1+ (1,0) [0|0] "" Vector__XXX
 SG_ HVP_a012_bmbCommStatusTypeA m12 : 21|2@1+ (1,0) [0|0] "" Vector__XXX
 SG_ HVP_a013_bmbCommStatusTypeA m13 : 21|2@1+ (1,0) [0|0] "" Vector__XXX
 SG_ HVP_a021_RefCurrentTestFailed m21 : 21|1@1+ (1,0) [0|0] "" Vector__XXX
 SG_ HVP_a022_LowSide m22 : 21|1@1+ (1,0) [0|0] "" Vector__XXX
 SG_ HVP_a041_underVoltage m41 : 21|1@1+ (1,0) [0|0] "" Vector__XXX
 SG_ HVP_a042_crashEvent m42 : 21|1@1+ (1,0) [0|0] "" Vector__XXX
 SG_ HVP_a043_underVoltage m43 : 21|1@1+ (1,0) [0|0] "" Vector__XXX
 SG_ HVP_a044_crashEvent m44 : 21|1@1+ (1,0) [0|0] "" Vector__XXX
 SG_ HVP_a065_brickId m65 : 21|7@1+ (1,1) [0|0] "" Vector__XXX
 SG_ HVP_a021_PyroLeakTestFailed m21 : 22|1@1+ (1,0) [0|0] "" Vector__XXX
 SG_ HVP_a041_crashEvent m41 : 22|1@1+ (1,0) [0|0] "" Vector__XXX
 SG_ HVP_a042_fcContactorHw m42 : 22|1@1+ (1,0) [0|0] "" Vector__XXX
 SG_ HVP_a043_crashEvent m43 : 22|1@1+ (1,0) [0|0] "" Vector__XXX
 SG_ HVP_a044_fcContactorHw m44 : 22|1@1+ (1,0) [0|0] "" Vector__XXX
 SG_ HVP_a057_readCVA m57 : 22|1@1+ (1,0) [0|0] "" Vector__XXX
 SG_ HVP_a021_SquibResTestFailed m21 : 23|1@1+ (1,0) [0|0] "" Vector__XXX
 SG_ HVP_a041_packContactorHw m41 : 23|1@1+ (1,0) [0|0] "" Vector__XXX
 SG_ HVP_a042_notAllowedtoEnergize m42 : 23|1@1+ (1,0) [0|0] "" Vector__XXX
 SG_ HVP_a043_packContactorHw m43 : 23|1@1+ (1,0) [0|0] "" Vector__XXX
 SG_ HVP_a044_notAllowedtoEnergize m44 : 23|1@1+ (1,0) [0|0] "" Vector__XXX
 SG_ HVP_a057_readCVB m57 : 23|1@1+ (1,0) [0|0] "" Vector__XXX
 SG_ HVP_a012_breakLocationB m12 : 24|5@1+ (1,0) [0|0] "" Vector__XXX
 SG_ HVP_a013_breakLocationB m13 : 24|5@1+ (1,0) [0|0] "" Vector__XXX
 SG_ HVP_a021_VstTestFailed m21 : 24|1@1+ (1,0) [0|0] "" Vector__XXX
 SG_ HVP_a022_Aout m22 : 24|14@1+ (0.001,0) [0|0] "" Vector__XXX
 SG_ HVP_a026_inputVoltage m26 : 24|8@1+ (0.04,0) [0|0] "" Vector__XXX
 SG_ HVP_a036_pyroFiringTime m36 : 24|16@1+ (1,0) [0|0] "" Vector__XXX
 SG_ HVP_a040_coilCurrent m40 : 24|8@1+ (0.1,0) [0|0] "" Vector__XXX
 SG_ HVP_a041_notAllowedtoEnergize m41 : 24|1@1+ (1,0) [0|0] "" Vector__XXX
 SG_ HVP_a042_bmsHvsMia m42 : 24|1@1+ (1,0) [0|0] "" Vector__XXX
 SG_ HVP_a043_notAllowedtoEnergize m43 : 24|1@1+ (1,0) [0|0] "" Vector__XXX
 SG_ HVP_a044_bmsHvsMia m44 : 24|1@1+ (1,0) [0|0] "" Vector__XXX
 SG_ HVP_a056_shuntCurrent m56 : 24|16@1- (0.1,0) [0|0] "" Vector__XXX
 SG_ HVP_a057_readCVC m57 : 24|1@1+ (1,0) [0|0] "" Vector__XXX
 SG_ HVP_a021_SquibResistance m21 : 25|16@1+ (0.001,0) [0|0] "" Vector__XXX
 SG_ HVP_a041_bmbMia m41 : 25|1@1+ (1,0) [0|0] "" Vector__XXX
 SG_ HVP_a042_cpMia m42 : 25|1@1+ (1,0) [0|0] "" Vector__XXX
 SG_ HVP_a043_bmbMia m43 : 25|1@1+ (1,0) [0|0] "" Vector__XXX
 SG_ HVP_a044_cpMia m44 : 25|1@1+ (1,0) [0|0] "" Vector__XXX
 SG_ HVP_a057_readCVD m57 : 25|1@1+ (1,0) [0|0] "" Vector__XXX
 SG_ HVP_a041_hvilFault m41 : 26|1@1+ (1,0) [0|0] "" Vector__XXX
 SG_ HVP_a042_cpFault m42 : 26|1@1+ (1,0) [0|0] "" Vector__XXX
 SG_ HVP_a043_contactorOpened m43 : 26|1@1+ (1,0) [0|0] "" Vector__XXX
 SG_ HVP_a044_cpFault m44 : 26|1@1+ (1,0) [0|0] "" Vector__XXX
 SG_ HVP_a057_readCVE m57 : 26|1@1+ (1,0) [0|0] "" Vector__XXX
 SG_ HVP_a041_contactorStateWelded m41 : 27|1@1+ (1,0) [0|0] "" Vector__XXX
 SG_ HVP_a042_supply12V m42 : 27|1@1+ (1,0) [0|0] "" Vector__XXX
 SG_ HVP_a044_supply12V m44 : 27|1@1+ (1,0) [0|0] "" Vector__XXX
 SG_ HVP_a057_readCVF m57 : 27|1@1+ (1,0) [0|0] "" Vector__XXX
 SG_ HVP_a041_shuntHwMia m41 : 28|1@1+ (1,0) [0|0] "" Vector__XXX
 SG_ HVP_a042_supplyVer m42 : 28|1@1+ (1,0) [0|0] "" Vector__XXX
 SG_ HVP_a044_supplyVer m44 : 28|1@1+ (1,0) [0|0] "" Vector__XXX
 SG_ HVP_a057_readSNA m57 : 28|1@1+ (1,0) [0|0] "" Vector__XXX
 SG_ HVP_a012_bmbCommStatusTypeB m12 : 29|2@1+ (1,0) [0|0] "" Vector__XXX
 SG_ HVP_a013_bmbCommStatusTypeB m13 : 29|2@1+ (1,0) [0|0] "" Vector__XXX
 SG_ HVP_a041_shuntCurrentMia m41 : 29|1@1+ (1,0) [0|0] "" Vector__XXX
 SG_ HVP_a042_packVoltageMismatch m42 : 29|1@1+ (1,0) [0|0] "" Vector__XXX
 SG_ HVP_a044_packVoltageMismatch m44 : 29|1@1+ (1,0) [0|0] "" Vector__XXX
 SG_ HVP_a057_readSNB m57 : 29|1@1+ (1,0) [0|0] "" Vector__XXX
 SG_ HVP_a041_packVoltageMismatch m41 : 30|1@1+ (1,0) [0|0] "" Vector__XXX
 SG_ HVP_a042_hvilFault m42 : 30|1@1+ (1,0) [0|0] "" Vector__XXX
 SG_ HVP_a044_contactorOpened m44 : 30|1@1+ (1,0) [0|0] "" Vector__XXX
 SG_ HVP_a057_readSNC m57 : 30|1@1+ (1,0) [0|0] "" Vector__XXX
 SG_ HVP_a041_gpoRequestActive m41 : 31|1@1+ (1,0) [0|0] "" Vector__XXX
 SG_ HVP_a042_contactorStateWelded m42 : 31|1@1+ (1,0) [0|0] "" Vector__XXX
 SG_ HVP_a044_cpVersionMismatch m44 : 31|1@1+ (1,0) [0|0] "" Vector__XXX
 SG_ HVP_a057_readSND m57 : 31|1@1+ (1,0) [0|0] "" Vector__XXX
 SG_ HVP_a000_alertDataW1 m0 : 32|16@1+ (1,0) [0|0] "" Vector__XXX
 SG_ HVP_a008_sensorId m8 : 32|6@1+ (1,1) [0|0] "" Vector__XXX
 SG_ HVP_a009_brickId m9 : 32|7@1+ (1,1) [0|0] "" Vector__XXX
 SG_ HVP_a010_brickId m10 : 32|7@1+ (1,1) [0|0] "" Vector__XXX
 SG_ HVP_a013_bmbChainBreakType m13 : 32|3@1+ (1,0) [0|0] "" Vector__XXX
 SG_ HVP_a018_battery12V m18 : 32|12@1+ (0.1,0) [0|0] "" Vector__XXX
 SG_ HVP_a020_shuntCurrentAux m20 : 32|16@1- (0.1,0) [0|0] "" Vector__XXX
 SG_ HVP_a023_reason m23 : 32|2@1+ (1,0) [0|0] "" Vector__XXX
 SG_ HVP_a025_voltage2 m25 : 32|16@1+ (0.1,0) [0|0] "" Vector__XXX
 SG_ HVP_a026_outputVoltage m26 : 32|8@1+ (0.04,0) [0|0] "" Vector__XXX
 SG_ HVP_a028_sumOfBrickV m28 : 32|16@1+ (0.1,0) [0|0] "" Vector__XXX
 SG_ HVP_a030_dcPositiveLinkV m30 : 32|16@1- (0.1,0) [0|0] "" Vector__XXX
 SG_ HVP_a031_dcNegativeLinkV m31 : 32|16@1- (0.1,0) [0|0] "" Vector__XXX
 SG_ HVP_a033_coilCurrent m33 : 32|16@1+ (0.1,0) [0|0] "" Vector__XXX
 SG_ HVP_a035_coilCurrent m35 : 32|16@1+ (0.1,0) [0|0] "" Vector__XXX
 SG_ HVP_a040_posCtrVoltageDrop m40 : 32|15@1- (0.1,0) [0|0] "" Vector__XXX
 SG_ HVP_a041_fcContactorClosing m41 : 32|1@1+ (1,0) [0|0] "" Vector__XXX
 SG_ HVP_a042_shuntHwMia m42 : 32|1@1+ (1,0) [0|0] "" Vector__XXX
 SG_ HVP_a046_shuntTemperature m46 : 32|16@1- (0.01,0) [0|0] "" Vector__XXX
 SG_ HVP_a047_auxCurrent m47 : 32|16@1- (0.1,0) [0|0] "" Vector__XXX
 SG_ HVP_a049_coilCurrent m49 : 32|16@1+ (0.1,0) [0|0] "" Vector__XXX
 SG_ HVP_a050_coilCurrent m50 : 32|16@1+ (0.1,0) [0|0] "" Vector__XXX
 SG_ HVP_a051_shuntCurrent m51 : 32|16@1- (0.1,0) [0|0] "" Vector__XXX
 SG_ HVP_a052_regErrorType m52 : 32|8@1+ (1,0) [0|0] "" Vector__XXX
 SG_ HVP_a053_dcLinkVoltage m53 : 32|16@1+ (0.01,0) [0|0] "" Vector__XXX
 SG_ HVP_a057_readSNE m57 : 32|1@1+ (1,0) [0|0] "" Vector__XXX
 SG_ HVP_a058_bmbDeviceId m58 : 32|4@1+ (1,1) [0|0] "" Vector__XXX
 SG_ HVP_a059_bmbDeviceId m59 : 32|4@1+ (1,1) [0|0] "" Vector__XXX
 SG_ HVP_a060_sumBrickVoltage m60 : 32|16@1+ (0.00128,0) [0|0] "" Vector__XXX
 SG_ HVP_a061_auxCurrent m61 : 32|16@1- (0.1,0) [0|0] "" Vector__XXX
 SG_ HVP_a063_secondaryBrickVoltage m63 : 32|16@1+ (0.0001,0) [0|0] "" Vector__XXX
 SG_ HVP_a064_secondaryAuxVoltage m64 : 32|16@1+ (0.0001,0) [0|0] "" Vector__XXX
 SG_ HVP_a068_shuntCurrent m68 : 32|16@1- (0.1,0) [0|0] "" Vector__XXX
 SG_ HVP_a041_fcContactorOpening m41 : 33|1@1+ (1,0) [0|0] "" Vector__XXX
 SG_ HVP_a042_shuntCurrentMia m42 : 33|1@1+ (1,0) [0|0] "" Vector__XXX
 SG_ HVP_a057_readSNF m57 : 33|1@1+ (1,0) [0|0] "" Vector__XXX
 SG_ HVP_a041_resetRequestRequired m41 : 34|1@1+ (1,0) [0|0] "" Vector__XXX
 SG_ HVP_a042_packContactorClosing m42 : 34|1@1+ (1,0) [0|0] "" Vector__XXX
 SG_ HVP_a057_readAUXA m57 : 34|1@1+ (1,0) [0|0] "" Vector__XXX
 SG_ HVP_a041_pyroFault m41 : 35|1@1+ (1,0) [0|0] "" Vector__XXX
 SG_ HVP_a042_packContactorOpening m42 : 35|1@1+ (1,0) [0|0] "" Vector__XXX
 SG_ HVP_a057_readAUXB m57 : 35|1@1+ (1,0) [0|0] "" Vector__XXX
 SG_ HVP_a041_dcLinkOverVoltage m41 : 36|1@1+ (1,0) [0|0] "" Vector__XXX
 SG_ HVP_a042_resetRequestRequired m42 : 36|1@1+ (1,0) [0|0] "" Vector__XXX
 SG_ HVP_a057_readSTAT m57 : 36|1@1+ (1,0) [0|0] "" Vector__XXX
 SG_ HVP_a058_VrefStatus m58 : 36|2@1+ (1,0) [0|0] "" Vector__XXX
 SG_ HVP_a059_VrefStatus m59 : 36|2@1+ (1,0) [0|0] "" Vector__XXX
 SG_ HVP_a042_cpVersionMismatch m42 : 37|1@1+ (1,0) [0|0] "" Vector__XXX
 SG_ HVP_a008_primaryChainSensor m8 : 38|1@1+ (1,0) [0|0] "" Vector__XXX
 SG_ HVP_a058_VrefType m58 : 38|2@1+ (1,0) [0|0] "" Vector__XXX
 SG_ HVP_a059_VrefType m59 : 38|2@1+ (1,0) [0|0] "" Vector__XXX
 SG_ HVP_a009_primaryChainSensor m9 : 39|1@1+ (1,0) [0|0] "" Vector__XXX
 SG_ HVP_a010_primaryChainSensor m10 : 39|1@1+ (1,0) [0|0] "" Vector__XXX
 SG_ HVP_a022_SquibResistance m22 : 40|16@1+ (0.001,0) [0|0] "" Vector__XXX
 SG_ HVP_a026_internalVoltage m26 : 40|8@1+ (0.04,0) [0|0] "" Vector__XXX
 SG_ HVP_a036_pyroFiringAttempt m36 : 40|4@1+ (1,0) [0|0] "" Vector__XXX
 SG_ HVP_a056_posPackContactorState m56 : 40|3@1+ (1,0) [0|0] "" Vector__XXX
 SG_ HVP_a021_OneShotSequence m21 : 41|1@1+ (1,0) [0|0] "" Vector__XXX
 SG_ HVP_a021_HighSide m21 : 42|1@1+ (1,0) [0|0] "" Vector__XXX
 SG_ HVP_a021_LowSide m21 : 43|1@1+ (1,0) [0|0] "" Vector__XXX
 SG_ HVP_a056_negPackContactorState m56 : 43|3@1+ (1,0) [0|0] "" Vector__XXX
 SG_ HVP_a018_remainingPcsPowerCyclesAllowed m18 : 44|2@1+ (1,0) [0|0] "" Vector__XXX
 SG_ HVP_a021_Aout m21 : 44|14@1+ (0.001,0) [0|0] "" Vector__XXX
 SG_ HVP_a018_remainingPcsRecoveriesAllowed m18 : 46|2@1+ (1,0) [0|0] "" Vector__XXX
 SG_ HVP_a040_negCtrVoltageDrop m40 : 47|15@1- (0.1,0) [0|0] "" Vector__XXX
 SG_ HVP_a000_alertDataW2 m0 : 48|16@1+ (1,0) [0|0] "" Vector__XXX
 SG_ HVP_a018_hvcHardwareSupportsCycling m18 : 48|1@1+ (1,0) [0|0] "" Vector__XXX
 SG_ HVP_a020_shuntTemperature m20 : 48|16@1- (0.01,0) [0|0] "" Vector__XXX
 SG_ HVP_a025_packVoltage m25 : 48|16@1+ (0.1,0) [0|0] "" Vector__XXX
 SG_ HVP_a026_dirVoltage m26 : 48|8@1+ (0.04,0) [0|0] "" Vector__XXX
 SG_ HVP_a033_pwmDutyCylePositive m33 : 48|8@1+ (1,0) [0|0] "" Vector__XXX
 SG_ HVP_a035_pwmDutyCylePositive m35 : 48|8@1+ (1,0) [0|0] "" Vector__XXX
 SG_ HVP_a046_asicTemperature m46 : 48|16@1- (0.01,0) [0|0] "" Vector__XXX
 SG_ HVP_a049_posCtrState m49 : 48|3@1+ (1,0) [0|0] "" Vector__XXX
 SG_ HVP_a050_posCtrState m50 : 48|3@1+ (1,0) [0|0] "" Vector__XXX
 SG_ HVP_a051_energyReserveV m51 : 48|16@1+ (0.001,0) [0|0] "" Vector__XXX
 SG_ HVP_a056_posFcContactorState m56 : 48|3@1+ (1,0) [0|0] "" Vector__XXX
 SG_ HVP_a060_stackId m60 : 48|8@1+ (1,1) [0|0] "" Vector__XXX
 SG_ HVP_a063_brickId m63 : 48|8@1+ (1,1) [0|0] "" Vector__XXX
 SG_ HVP_a064_auxId m64 : 48|8@1+ (1,1) [0|0] "" Vector__XXX
 SG_ HVP_a068_energyReserveV m68 : 48|16@1+ (0.001,0) [0|0] "" Vector__XXX
 SG_ HVP_a018_pcsHardwareOkToBePowerCycled m18 : 49|1@1+ (1,0) [0|0] "" Vector__XXX
 SG_ HVP_a018_gpioLogicPowerEnable m18 : 50|1@1+ (1,0) [0|0] "" Vector__XXX
 SG_ HVP_a018_gpioDcDcEnable m18 : 51|1@1+ (1,0) [0|0] "" Vector__XXX
 SG_ HVP_a049_negCtrState m49 : 51|3@1+ (1,0) [0|0] "" Vector__XXX
 SG_ HVP_a050_negCtrState m50 : 51|3@1+ (1,0) [0|0] "" Vector__XXX
 SG_ HVP_a056_negFcContactorState m56 : 51|3@1+ (1,0) [0|0] "" Vector__XXX
 SG_ HVP_a018_gpioChgEnable m18 : 52|1@1+ (1,0) [0|0] "" Vector__XXX
 SG_ HVP_a026_difVoltage m26 : 56|8@1+ (0.04,0) [0|0] "" Vector__XXX
 SG_ HVP_a033_pwmDutyCyleNegative m33 : 56|8@1+ (1,0) [0|0] "" Vector__XXX
 SG_ HVP_a035_pwmDutyCyleNegative m35 : 56|8@1+ (1,0) [0|0] "" Vector__XXX
 SG_ HVP_a063_numFailedBricks m63 : 56|8@1+ (1,0) [0|0] "" Vector__XXX
 SG_ HVP_a064_numFailedAux m64 : 56|8@1+ (1,0) [0|0] "" Vector__XXX
 SG_ HVP_a040_posCtrAuxOpen m40 : 62|1@1+ (1,0) [0|0] "" Vector__XXX
 SG_ HVP_a040_negCtrAuxOpen m40 : 63|1@1+ (1,0) [0|0] "" Vector__XXX
